VERSION "HNNBNNNYNNNNNNNNNNNNNNNNNNNNNNNNNNNNNNNNNN/4/%%%/4/'%**4NNN///"

NS_ :

BS_:

BU_: BAP_Tester BCM Gateway_Max TSGGen3_BFS TSGGen3_FS TSGGen3_HBFS TSGGen3_HFS WLC_01_CFD

BO_ 1524 Innenlicht_11: 8 BCM
 SG_ IL_Dimmung_V_Tuerkontur : 0|8@1+ (1,0) [0|100] "Unit_PerCent"  Gateway_Max
 SG_ IL_Dimmung_H_Tuerkontur : 8|8@1+ (1,0) [0|100] "Unit_PerCent"  Gateway_Max
 SG_ IL_Dimmung_Tuerinnengriff : 16|8@1+ (1,0) [0|100] "Unit_PerCent"  Gateway_Max
 SG_ IL_Dimmung_Umfeldbel : 24|8@1+ (1,0) [0|100] "Unit_PerCent"  Gateway_Max
 SG_ IL_Bel_FS_Ausstieg : 32|1@1+ (1.0,0.0) [0.0|1] ""  Gateway_Max
 SG_ IL_Bel_BFS_Ausstieg : 33|1@1+ (1.0,0.0) [0.0|1] ""  Gateway_Max
 SG_ IL_Bel_HFS_Ausstieg : 34|1@1+ (1.0,0.0) [0.0|1] ""  Gateway_Max
 SG_ IL_Bel_HBFS_Ausstieg : 35|1@1+ (1.0,0.0) [0.0|1] ""  Gateway_Max
 SG_ BCM1_Innenlicht_gedimmt_V : 36|1@1+ (1.0,0.0) [0.0|1] ""  Gateway_Max
 SG_ BCM1_Innenlicht_gedimmt_H : 37|1@1+ (1.0,0.0) [0.0|1] ""  Gateway_Max
 SG_ IL_Innenlicht_aktiv : 38|1@1+ (1.0,0.0) [0.0|1] ""  Gateway_Max
 SG_ IL_Klemme_30G_aktiv : 39|1@1+ (1.0,0.0) [0.0|1] ""  Gateway_Max,TSGGen3_BFS,TSGGen3_FS,TSGGen3_HBFS,TSGGen3_HFS
 SG_ BCM1_DI_Rampe_Innenlicht : 40|1@1+ (1.0,0.0) [0.0|1] ""  Gateway_Max
 SG_ BCM1_DI_Rampe_Leselicht : 41|1@1+ (1.0,0.0) [0.0|1] ""  Gateway_Max
 SG_ BCM1_Innenlicht_H : 42|1@1+ (1.0,0.0) [0.0|1] ""  Gateway_Max
 SG_ BCM1_Innenlicht_V : 43|1@1+ (1.0,0.0) [0.0|1] ""  Gateway_Max
 SG_ BCM1_Leselicht_Anf_hl : 44|1@1+ (1.0,0.0) [0.0|1] ""  Gateway_Max
 SG_ BCM1_Leselicht_Anf_hr : 45|1@1+ (1.0,0.0) [0.0|1] ""  Gateway_Max
 SG_ BCM1_Leselicht_Anf_vl : 46|1@1+ (1.0,0.0) [0.0|1] ""  Gateway_Max
 SG_ BCM1_Leselicht_Anf_vr : 47|1@1+ (1.0,0.0) [0.0|1] ""  Gateway_Max
 SG_ BCM1_Leuchten_Aus : 48|1@1+ (1.0,0.0) [0.0|1] ""  Gateway_Max
 SG_ AMB_Charisma_FahrPr : 49|4@1+ (1.0,0.0) [0.0|15] ""  Gateway_Max
 SG_ AMB_Charisma_Status : 53|2@1+ (1.0,0.0) [0.0|3] ""  Gateway_Max
 SG_ IL_Dimmung_Lautspr : 56|8@1+ (1,0) [0|100] "Unit_PerCent"  Gateway_Max

BO_ 2527679583 IPA_02: 8 Gateway_Max
 SG_ IPA_02_CRC : 0|8@1+ (1,0) [0|255] ""  BCM
 SG_ IPA_02_BZ : 8|4@1+ (1,0) [0|15] ""  BCM
 SG_ IPA_PL_Anzeige_links : 12|2@1+ (1.0,0.0) [0.0|3] ""  BCM
 SG_ IPA_PL_Anzeige_rechts : 14|2@1+ (1.0,0.0) [0.0|3] ""  BCM
 SG_ Parken_Seitenspiegel_Anf : 20|2@1+ (1.0,0.0) [0.0|3] ""  BCM
 SG_ Parken_ZV_Schliessen : 22|2@1+ (1.0,0.0) [0.0|3] ""  BCM
 SG_ Parken_aktives_System_02 : 24|5@1+ (1.0,0.0) [0.0|31] ""  BCM
 SG_ Parken_ZR_Sondermodus_Anf : 29|2@1+ (1.0,0.0) [0.0|3] ""  BCM
 SG_ Parken_Schluesselsuche_Anf : 31|1@1+ (1.0,0.0) [0.0|1] ""  BCM
 SG_ Parken_FFB_LED_Anf : 32|2@1+ (1.0,0.0) [0.0|3] ""  BCM
 SG_ Parken_Wegfahrsperren_Anf : 34|2@1+ (1.0,0.0) [0.0|3] ""  BCM
 SG_ Parken_Aktivierungslicht_Anf : 36|1@1+ (1.0,0.0) [0.0|1] ""  BCM
 SG_ Parken_Fahrtrichtungslicht_Anf : 37|2@1+ (1.0,0.0) [0.0|3] ""  BCM
 SG_ Parken_Lichtnachlauf_Anf : 39|1@1+ (1.0,0.0) [0.0|1] ""  BCM
 SG_ IPA_Akustik_PL_gefunden : 45|1@1+ (1.0,0.0) [0.0|1] ""  BCM
 SG_ Parken_Blinker_li_Anf : 46|1@1+ (1.0,0.0) [0.0|1] ""  BCM
 SG_ Parken_Blinker_re_Anf : 47|1@1+ (1.0,0.0) [0.0|1] ""  BCM
 SG_ Parken_Fahrerhinweise_Anf : 51|1@1+ (1.0,0.0) [0.0|1] ""  BCM
 SG_ Parken_Bestaetigungsblinken_Anf : 52|2@1+ (1.0,0.0) [0.0|3] ""  BCM
 SG_ Parken_Fahrbereitschaftlicht_Anf : 54|1@1+ (1.0,0.0) [0.0|1] ""  BCM
 SG_ Parken_Lichtsteuerung_Anf : 55|1@1+ (1.0,0.0) [0.0|1] ""  BCM
 SG_ IPA_Anf_Meldungen : 56|8@1+ (1.0,0.0) [0.0|255] ""  BCM

BO_ 1806 ISO_BCM1_Req: 8 Gateway_Max
 SG_ ISO_BCM1_Req_Data : 0|64@1+ (1.0,0.0) [0.0|18446744073709551615] ""  BCM

BO_ 1912 ISO_BCM1_Resp: 8 BCM
 SG_ ISO_BCM1_Resp_Data : 0|64@1+ (1.0,0.0) [0.0|18446744073709551615] ""  Gateway_Max

BO_ 1792 ISO_Funktionaler_Req_All: 8 Gateway_Max
 SG_ ISO_ALL_01_Req_Data : 0|64@1+ (1.0,0.0) [0.0|18446744073709551615] ""  BCM,TSGGen3_BFS,TSGGen3_FS,TSGGen3_HBFS,TSGGen3_HFS,WLC_01_CFD

BO_ 1842 ISO_Kessy_Req: 8 Gateway_Max
 SG_ ISO_Kessy_Req_Data : 0|64@1+ (1.0,0.0) [0.0|18446744073709551615] ""  BCM

BO_ 1948 ISO_Kessy_Resp: 8 BCM
 SG_ ISO_Kessy_Resp_Data : 0|64@1+ (1.0,0.0) [0.0|18446744073709551615] ""  Gateway_Max

BO_ 1867 ISO_TSG_BT_Req: 8 Gateway_Max
 SG_ ISO_TSG_BT_Req_Data : 0|64@1+ (1.0,0.0) [0.0|18446744073709551615] ""  TSGGen3_BFS

BO_ 1973 ISO_TSG_BT_Resp: 8 TSGGen3_BFS
 SG_ ISO_TSG_BT_Resp_Data : 0|64@1+ (1.0,0.0) [0.0|18446744073709551615] ""  Gateway_Max

BO_ 1866 ISO_TSG_FT_Req: 8 Gateway_Max
 SG_ ISO_TSG_FT_Req_Data : 0|64@1+ (1.0,0.0) [0.0|18446744073709551615] ""  TSGGen3_FS

BO_ 1972 ISO_TSG_FT_Resp: 8 TSGGen3_FS
 SG_ ISO_TSG_FT_Resp_Data : 0|64@1+ (1.0,0.0) [0.0|18446744073709551615] ""  Gateway_Max

BO_ 1855 ISO_TSG_HBFS_Req: 8 Gateway_Max
 SG_ ISO_TSG_HBFS_Req_Data : 0|64@1+ (1.0,0.0) [0.0|18446744073709551615] ""  TSGGen3_HBFS

BO_ 1961 ISO_TSG_HBFS_Resp: 8 TSGGen3_HBFS
 SG_ ISO_TSG_HBFS_Resp_Data : 0|64@1+ (1.0,0.0) [0.0|18446744073709551615] ""  Gateway_Max

BO_ 1854 ISO_TSG_HFS_Req: 8 Gateway_Max
 SG_ ISO_TSG_HFS_Req_Data : 0|64@1+ (1.0,0.0) [0.0|18446744073709551615] ""  TSGGen3_HFS

BO_ 1960 ISO_TSG_HFS_Resp: 8 TSGGen3_HFS
 SG_ ISO_TSG_HFS_Resp_Data : 0|64@1+ (1.0,0.0) [0.0|18446744073709551615] ""  Gateway_Max

BO_ 2621440014 ISOx_BCM1_Req_FD: 64 Gateway_Max
 SG_ ISOx_BCM1_Req_FD_Data : 0|512@1+ (1.0,0.0) [0.0|13407807929942597099574024998205846127479365820592393377723561443721764030073546976801874298166903427690031858186486050853753882811946569946433649006084095] ""  BCM

BO_ 2621571086 ISOx_BCM1_Resp_FD: 64 BCM
 SG_ ISOx_BCM1_Resp_FD_Data : 0|512@1+ (1.0,0.0) [0.0|13407807929942597099574024998205846127479365820592393377723561443721764030073546976801874298166903427690031858186486050853753882811946569946433649006084095] ""  Gateway_Max

BO_ 2549874874 ISOx_DDA_Req: 8 Gateway_Max
 SG_ ISOx_DDA_Req_Data : 0|64@1+ (1.0,0.0) [0.0|18446744073709551615] ""  BCM

BO_ 2550005946 ISOx_DDA_Resp: 8 BCM
 SG_ ISOx_DDA_Resp_Data : 0|64@1+ (1.0,0.0) [0.0|18446744073709551615] ""  Gateway_Max

BO_ 2621505536 ISOx_Funkt_Req_All_FD: 64 Gateway_Max
 SG_ ISOx_Funkt_Req_All_FD_Data : 0|512@1+ (1.0,0.0) [0.0|13407807929942597099574024998205846127479365820592393377723561443721764030073546976801874298166903427690031858186486050853753882811946569946433649006084095] ""  BCM,TSGGen3_BFS,TSGGen3_FS,TSGGen3_HBFS,TSGGen3_HFS,WLC_01_CFD

BO_ 2549874838 ISOx_LED_LM_L_Req: 8 Gateway_Max
 SG_ ISOx_LED_LM_L_Req_Data : 0|64@1+ (1.0,0.0) [0.0|18446744073709551615] ""  BCM

BO_ 2550005910 ISOx_LED_LM_L_Resp: 8 BCM
 SG_ ISOx_LED_LM_L_Resp_Data : 0|64@1+ (1.0,0.0) [0.0|18446744073709551615] ""  Gateway_Max

BO_ 2549874839 ISOx_LED_LM_R_Req: 8 Gateway_Max
 SG_ ISOx_LED_LM_R_Req_Data : 0|64@1+ (1.0,0.0) [0.0|18446744073709551615] ""  BCM

BO_ 2550005911 ISOx_LED_LM_R_Resp: 8 BCM
 SG_ ISOx_LED_LM_R_Resp_Data : 0|64@1+ (1.0,0.0) [0.0|18446744073709551615] ""  Gateway_Max

BO_ 2550398979 ISOx_RSAD_HL_Req: 8 Gateway_Max
 SG_ ISOx_RSAD_HL_Req_Data : 0|64@1+ (1.0,0.0) [0.0|18446744073709551615] ""  BCM

BO_ 2621702147 ISOx_RSAD_HL_Req_FD: 64 Gateway_Max
 SG_ ISOx_RSAD_HL_Req_FD_Data : 0|512@1+ (1.0,0.0) [0.0|13407807929942597099574024998205846127479365820592393377723561443721764030073546976801874298166903427690031858186486050853753882811946569946433649006084095] ""  BCM

BO_ 2550530051 ISOx_RSAD_HL_Resp: 8 BCM
 SG_ ISOx_RSAD_HL_Resp_Data : 0|64@1+ (1.0,0.0) [0.0|18446744073709551615] ""  Gateway_Max

BO_ 2621833219 ISOx_RSAD_HL_Resp_FD: 64 BCM
 SG_ ISOx_RSAD_HL_Resp_FD_Data : 0|512@1+ (1.0,0.0) [0.0|13407807929942597099574024998205846127479365820592393377723561443721764030073546976801874298166903427690031858186486050853753882811946569946433649006084095] ""  Gateway_Max

BO_ 2550398980 ISOx_RSAD_HR_Req: 8 Gateway_Max
 SG_ ISOx_RSAD_HR_Req_Data : 0|64@1+ (1.0,0.0) [0.0|18446744073709551615] ""  BCM

BO_ 2621702148 ISOx_RSAD_HR_Req_FD: 64 Gateway_Max
 SG_ ISOx_RSAD_HR_Req_FD_Data : 0|512@1+ (1.0,0.0) [0.0|13407807929942597099574024998205846127479365820592393377723561443721764030073546976801874298166903427690031858186486050853753882811946569946433649006084095] ""  BCM

BO_ 2550530052 ISOx_RSAD_HR_Resp: 8 BCM
 SG_ ISOx_RSAD_HR_Resp_Data : 0|64@1+ (1.0,0.0) [0.0|18446744073709551615] ""  Gateway_Max

BO_ 2621833220 ISOx_RSAD_HR_Resp_FD: 64 BCM
 SG_ ISOx_RSAD_HR_Resp_FD_Data : 0|512@1+ (1.0,0.0) [0.0|13407807929942597099574024998205846127479365820592393377723561443721764030073546976801874298166903427690031858186486050853753882811946569946433649006084095] ""  Gateway_Max

BO_ 2550399029 ISOx_RSAD_IN2_Req: 8 Gateway_Max
 SG_ ISOx_RSAD_IN2_Req_Data : 0|64@1+ (1.0,0.0) [0.0|18446744073709551615] ""  BCM

BO_ 2621702197 ISOx_RSAD_IN2_Req_FD: 64 Gateway_Max
 SG_ ISOx_RSAD_IN2_Req_FD_Data : 0|512@1+ (1.0,0.0) [0.0|13407807929942597099574024998205846127479365820592393377723561443721764030073546976801874298166903427690031858186486050853753882811946569946433649006084095] ""  BCM

BO_ 2550530101 ISOx_RSAD_IN2_Resp: 8 BCM
 SG_ ISOx_RSAD_IN2_Resp_Data : 0|64@1+ (1.0,0.0) [0.0|18446744073709551615] ""  Gateway_Max

BO_ 2621833269 ISOx_RSAD_IN2_Resp_FD: 64 BCM
 SG_ ISOx_RSAD_IN2_Resp_FD_Data : 0|512@1+ (1.0,0.0) [0.0|13407807929942597099574024998205846127479365820592393377723561443721764030073546976801874298166903427690031858186486050853753882811946569946433649006084095] ""  Gateway_Max

BO_ 2550399030 ISOx_RSAD_IN3_Req: 8 Gateway_Max
 SG_ ISOx_RSAD_IN3_Req_Data : 0|64@1+ (1.0,0.0) [0.0|18446744073709551615] ""  BCM

BO_ 2621702198 ISOx_RSAD_IN3_Req_FD: 64 Gateway_Max
 SG_ ISOx_RSAD_IN3_Req_FD_Data : 0|512@1+ (1.0,0.0) [0.0|13407807929942597099574024998205846127479365820592393377723561443721764030073546976801874298166903427690031858186486050853753882811946569946433649006084095] ""  BCM

BO_ 2550530102 ISOx_RSAD_IN3_Resp: 8 BCM
 SG_ ISOx_RSAD_IN3_Resp_Data : 0|64@1+ (1.0,0.0) [0.0|18446744073709551615] ""  Gateway_Max

BO_ 2621833270 ISOx_RSAD_IN3_Resp_FD: 64 BCM
 SG_ ISOx_RSAD_IN3_Resp_FD_Data : 0|512@1+ (1.0,0.0) [0.0|13407807929942597099574024998205846127479365820592393377723561443721764030073546976801874298166903427690031858186486050853753882811946569946433649006084095] ""  Gateway_Max

BO_ 2550399031 ISOx_RSAD_IN4_Req: 8 Gateway_Max
 SG_ ISOx_RSAD_IN4_Req_Data : 0|64@1+ (1.0,0.0) [0.0|18446744073709551615] ""  BCM

BO_ 2621702199 ISOx_RSAD_IN4_Req_FD: 64 Gateway_Max
 SG_ ISOx_RSAD_IN4_Req_FD_Data : 0|512@1+ (1.0,0.0) [0.0|13407807929942597099574024998205846127479365820592393377723561443721764030073546976801874298166903427690031858186486050853753882811946569946433649006084095] ""  BCM

BO_ 2550530103 ISOx_RSAD_IN4_Resp: 8 BCM
 SG_ ISOx_RSAD_IN4_Resp_Data : 0|64@1+ (1.0,0.0) [0.0|18446744073709551615] ""  Gateway_Max

BO_ 2621833271 ISOx_RSAD_IN4_Resp_FD: 64 BCM
 SG_ ISOx_RSAD_IN4_Resp_FD_Data : 0|512@1+ (1.0,0.0) [0.0|13407807929942597099574024998205846127479365820592393377723561443721764030073546976801874298166903427690031858186486050853753882811946569946433649006084095] ""  Gateway_Max

BO_ 2550398981 ISOx_RSAD_IN_Req: 8 Gateway_Max
 SG_ ISOx_RSAD_IN_Req_Data : 0|64@1+ (1.0,0.0) [0.0|18446744073709551615] ""  BCM

BO_ 2621702149 ISOx_RSAD_IN_Req_FD: 64 Gateway_Max
 SG_ ISOx_RSAD_IN_Req_FD_Data : 0|512@1+ (1.0,0.0) [0.0|13407807929942597099574024998205846127479365820592393377723561443721764030073546976801874298166903427690031858186486050853753882811946569946433649006084095] ""  BCM

BO_ 2550530053 ISOx_RSAD_IN_Resp: 8 BCM
 SG_ ISOx_RSAD_IN_Resp_Data : 0|64@1+ (1.0,0.0) [0.0|18446744073709551615] ""  Gateway_Max

BO_ 2621833221 ISOx_RSAD_IN_Resp_FD: 64 BCM
 SG_ ISOx_RSAD_IN_Resp_FD_Data : 0|512@1+ (1.0,0.0) [0.0|13407807929942597099574024998205846127479365820592393377723561443721764030073546976801874298166903427690031858186486050853753882811946569946433649006084095] ""  Gateway_Max

BO_ 2550398977 ISOx_RSAD_VL_Req: 8 Gateway_Max
 SG_ ISOx_RSAD_VL_Req_Data : 0|64@1+ (1.0,0.0) [0.0|18446744073709551615] ""  BCM

BO_ 2621702145 ISOx_RSAD_VL_Req_FD: 64 Gateway_Max
 SG_ ISOx_RSAD_VL_Req_FD_Data : 0|512@1+ (1.0,0.0) [0.0|13407807929942597099574024998205846127479365820592393377723561443721764030073546976801874298166903427690031858186486050853753882811946569946433649006084095] ""  BCM

BO_ 2550530049 ISOx_RSAD_VL_Resp: 8 BCM
 SG_ ISOx_RSAD_VL_Resp_Data : 0|64@1+ (1.0,0.0) [0.0|18446744073709551615] ""  Gateway_Max

BO_ 2621833217 ISOx_RSAD_VL_Resp_FD: 64 BCM
 SG_ ISOx_RSAD_VL_Resp_FD_Data : 0|512@1+ (1.0,0.0) [0.0|13407807929942597099574024998205846127479365820592393377723561443721764030073546976801874298166903427690031858186486050853753882811946569946433649006084095] ""  Gateway_Max

BO_ 2550398978 ISOx_RSAD_VR_Req: 8 Gateway_Max
 SG_ ISOx_RSAD_VR_Req_Data : 0|64@1+ (1.0,0.0) [0.0|18446744073709551615] ""  BCM

BO_ 2621702146 ISOx_RSAD_VR_Req_FD: 64 Gateway_Max
 SG_ ISOx_RSAD_VR_Req_FD_Data : 0|512@1+ (1.0,0.0) [0.0|13407807929942597099574024998205846127479365820592393377723561443721764030073546976801874298166903427690031858186486050853753882811946569946433649006084095] ""  BCM

BO_ 2550530050 ISOx_RSAD_VR_Resp: 8 BCM
 SG_ ISOx_RSAD_VR_Resp_Data : 0|64@1+ (1.0,0.0) [0.0|18446744073709551615] ""  Gateway_Max

BO_ 2621833218 ISOx_RSAD_VR_Resp_FD: 64 BCM
 SG_ ISOx_RSAD_VR_Resp_FD_Data : 0|512@1+ (1.0,0.0) [0.0|13407807929942597099574024998205846127479365820592393377723561443721764030073546976801874298166903427690031858186486050853753882811946569946433649006084095] ""  Gateway_Max

BO_ 2621440075 ISOx_TSG_BT_Req_FD: 64 Gateway_Max
 SG_ ISOx_TSG_BT_Req_FD_Data : 0|512@1+ (1.0,0.0) [0.0|13407807929942597099574024998205846127479365820592393377723561443721764030073546976801874298166903427690031858186486050853753882811946569946433649006084095] ""  TSGGen3_BFS

BO_ 2621571147 ISOx_TSG_BT_Resp_FD: 64 TSGGen3_BFS
 SG_ ISOx_TSG_BT_Resp_FD_Data : 0|512@1+ (1.0,0.0) [0.0|13407807929942597099574024998205846127479365820592393377723561443721764030073546976801874298166903427690031858186486050853753882811946569946433649006084095] ""  Gateway_Max

BO_ 2621440074 ISOx_TSG_FT_Req_FD: 64 Gateway_Max
 SG_ ISOx_TSG_FT_Req_FD_Data : 0|512@1+ (1.0,0.0) [0.0|13407807929942597099574024998205846127479365820592393377723561443721764030073546976801874298166903427690031858186486050853753882811946569946433649006084095] ""  TSGGen3_FS

BO_ 2621571146 ISOx_TSG_FT_Resp_FD: 64 TSGGen3_FS
 SG_ ISOx_TSG_FT_Resp_FD_Data : 0|512@1+ (1.0,0.0) [0.0|13407807929942597099574024998205846127479365820592393377723561443721764030073546976801874298166903427690031858186486050853753882811946569946433649006084095] ""  Gateway_Max

BO_ 2621440063 ISOx_TSG_HBFS_Req_FD: 64 Gateway_Max
 SG_ ISOx_TSG_HBFS_Req_FD_Data : 0|512@1+ (1.0,0.0) [0.0|13407807929942597099574024998205846127479365820592393377723561443721764030073546976801874298166903427690031858186486050853753882811946569946433649006084095] ""  TSGGen3_HBFS

BO_ 2621571135 ISOx_TSG_HBFS_Resp_FD: 64 TSGGen3_HBFS
 SG_ ISOx_TSG_HBFS_Resp_FD_Data : 0|512@1+ (1.0,0.0) [0.0|13407807929942597099574024998205846127479365820592393377723561443721764030073546976801874298166903427690031858186486050853753882811946569946433649006084095] ""  Gateway_Max

BO_ 2621440062 ISOx_TSG_HFS_Req_FD: 64 Gateway_Max
 SG_ ISOx_TSG_HFS_Req_FD_Data : 0|512@1+ (1.0,0.0) [0.0|13407807929942597099574024998205846127479365820592393377723561443721764030073546976801874298166903427690031858186486050853753882811946569946433649006084095] ""  TSGGen3_HFS

BO_ 2621571134 ISOx_TSG_HFS_Resp_FD: 64 TSGGen3_HFS
 SG_ ISOx_TSG_HFS_Resp_FD_Data : 0|512@1+ (1.0,0.0) [0.0|13407807929942597099574024998205846127479365820592393377723561443721764030073546976801874298166903427690031858186486050853753882811946569946433649006084095] ""  Gateway_Max

BO_ 2549874853 ISOx_WLC1_Req: 8 Gateway_Max
 SG_ ISOx_WLC1_Req_Data : 0|64@1+ (1.0,0.0) [0.0|18446744073709551615] ""  WLC_01_CFD

BO_ 2621440165 ISOx_WLC1_Req_FD: 64 Gateway_Max
 SG_ ISOx_WLC1_Req_FD_Data : 0|512@1+ (1.0,0.0) [0.0|13407807929942597099574024998205846127479365820592393377723561443721764030073546976801874298166903427690031858186486050853753882811946569946433649006084095] ""  WLC_01_CFD

BO_ 2550005925 ISOx_WLC1_Resp: 8 WLC_01_CFD
 SG_ ISOx_WLC1_Resp_Data : 0|64@1+ (1.0,0.0) [0.0|18446744073709551615] ""  Gateway_Max

BO_ 2621571237 ISOx_WLC1_Resp_FD: 64 WLC_01_CFD
 SG_ ISOx_WLC1_Resp_FD_Data : 0|512@1+ (1.0,0.0) [0.0|13407807929942597099574024998205846127479365820592393377723561443721764030073546976801874298166903427690031858186486050853753882811946569946433649006084095] ""  Gateway_Max

BO_ 1425 Kessy_03: 8 BCM
 SG_ KY_Gesamt_Entr : 8|1@1+ (1.0,0.0) [0.0|1] ""  Gateway_Max
 SG_ KY_FS_Entr : 9|1@1+ (1.0,0.0) [0.0|1] ""  Gateway_Max
 SG_ KY_BFS_Entr : 10|1@1+ (1.0,0.0) [0.0|1] ""  Gateway_Max
 SG_ KY_HFS_Entr : 11|1@1+ (1.0,0.0) [0.0|1] ""  Gateway_Max
 SG_ KY_HBFS_Entr : 12|1@1+ (1.0,0.0) [0.0|1] ""  Gateway_Max
 SG_ KY_HD_Entr : 13|1@1+ (1.0,0.0) [0.0|1] ""  Gateway_Max
 SG_ KY_HS_Entr : 14|1@1+ (1.0,0.0) [0.0|1] ""  Gateway_Max
 SG_ KY_Schliessverh_HD : 15|1@1+ (1.0,0.0) [0.0|1] ""  Gateway_Max
 SG_ KY_Zufallszahl : 16|32@1+ (1.0,0.0) [0.0|4294967295] ""  Gateway_Max
 SG_ KY_Burst_1 : 48|2@1+ (1,0) [0|3] ""  Gateway_Max
 SG_ KY_Burst_2 : 50|2@1+ (1,0) [0|3] ""  Gateway_Max
 SG_ KY_Burst_3 : 52|2@1+ (1,0) [0|3] ""  Gateway_Max
 SG_ KY_Bdraten_Rueckspr : 56|1@1+ (1.0,0.0) [0.0|1] ""  Gateway_Max
 SG_ KY_Entry_ETuer_HFS : 57|1@1+ (1.0,0.0) [0.0|1] ""  Gateway_Max
 SG_ KY_Entry_ETuer_HBFS : 58|1@1+ (1.0,0.0) [0.0|1] ""  Gateway_Max
 SG_ KY_VirtuellesPedal_HK : 59|1@1+ (1.0,0.0) [0.0|1] ""  Gateway_Max
 SG_ KY_3_Bremslicht_Ein : 60|1@1+ (1.0,0.0) [0.0|1] ""  Gateway_Max

BO_ 1426 Kessy_04: 8 BCM
 SG_ KY_ID_Geber1_im_Fzg : 12|1@1+ (1.0,0.0) [0.0|1] ""  Gateway_Max
 SG_ KY_ID_Geber2_im_Fzg : 13|1@1+ (1.0,0.0) [0.0|1] ""  Gateway_Max
 SG_ KY_ID_Geber3_im_Fzg : 14|1@1+ (1.0,0.0) [0.0|1] ""  Gateway_Max
 SG_ KY_ID_Geber4_im_Fzg : 15|1@1+ (1.0,0.0) [0.0|1] ""  Gateway_Max
 SG_ KY_Startknopf_Bel : 16|1@1+ (1.0,0.0) [0.0|1] ""  Gateway_Max
 SG_ KY_ID_Geber_Suche : 17|1@1+ (1.0,0.0) [0.0|1] ""  Gateway_Max
 SG_ KY_Meldungen : 18|4@1+ (1.0,0.0) [0.0|15] ""  Gateway_Max
 SG_ KY_Gong_600 : 22|1@1+ (1.0,0.0) [0.0|1] ""  Gateway_Max
 SG_ KY_Passiv_Autolock_Menue : 23|1@1+ (1.0,0.0) [0.0|1] ""  Gateway_Max
 SG_ KY_Passiv_Autolock_Akt : 24|1@1+ (1.0,0.0) [0.0|1] ""  Gateway_Max
 SG_ KY_Passiv_Autolock : 25|1@1+ (1.0,0.0) [0.0|1] ""  Gateway_Max
 SG_ KY_Passiv_Autounlock : 26|1@1+ (1.0,0.0) [0.0|1] ""  Gateway_Max
 SG_ KY_Gestik_HD : 27|1@1+ (1.0,0.0) [0.0|1] ""  Gateway_Max
 SG_ KY_StartStopp_Info : 28|2@1+ (1.0,0.0) [0.0|3] ""  Gateway_Max
 SG_ KY_Fzg_Verlassen_erkannt : 30|1@1+ (1.0,0.0) [0.0|1] ""  Gateway_Max
 SG_ KY_Fzg_Zugang_erkannt : 31|1@1+ (1.0,0.0) [0.0|1] ""  Gateway_Max
 SG_ KY_EasyClose_Abbruch : 32|1@1+ (1.0,0.0) [0.0|1] ""  Gateway_Max
 SG_ KY_EasyClose_Status : 33|3@1+ (1.0,0.0) [0.0|7] ""  Gateway_Max
 SG_ KY_HD_Auffahrt : 36|1@1+ (1.0,0.0) [0.0|1] ""  Gateway_Max
 SG_ KY_HD_Zufahrt : 37|1@1+ (1.0,0.0) [0.0|1] ""  Gateway_Max
 SG_ KY_Aktive_LFScans : 38|4@1+ (1.0,0.0) [0.0|15] ""  Gateway_Max
 SG_ KY_LF_Aktiv : 42|1@1+ (1.0,0.0) [0.0|1] ""  Gateway_Max
 SG_ KY_AnzKoord_Info : 43|2@1+ (1.0,0.0) [0.0|3] ""  Gateway_Max
 SG_ KY_Schluesselposition_9 : 45|2@1+ (1.0,0.0) [0.0|3] ""  Gateway_Max
 SG_ KY_Schluesselposition_1 : 48|2@1+ (1.0,0.0) [0.0|3] ""  Gateway_Max
 SG_ KY_Schluesselposition_2 : 50|2@1+ (1.0,0.0) [0.0|3] ""  Gateway_Max
 SG_ KY_Schluesselposition_3 : 52|2@1+ (1.0,0.0) [0.0|3] ""  Gateway_Max
 SG_ KY_Schluesselposition_4 : 54|2@1+ (1.0,0.0) [0.0|3] ""  Gateway_Max
 SG_ KY_Schluesselposition_5 : 56|2@1+ (1.0,0.0) [0.0|3] ""  Gateway_Max
 SG_ KY_Schluesselposition_6 : 58|2@1+ (1.0,0.0) [0.0|3] ""  Gateway_Max
 SG_ KY_Schluesselposition_7 : 60|2@1+ (1.0,0.0) [0.0|3] ""  Gateway_Max
 SG_ KY_Schluesselposition_8 : 62|2@1+ (1.0,0.0) [0.0|3] ""  Gateway_Max

BO_ 960 Klemmen_Status_01: 4 BCM
 SG_ Klemmen_Status_01_CRC : 0|8@1+ (1,0) [0|255] ""  Gateway_Max
 SG_ Klemmen_Status_01_BZ : 8|4@1+ (1,0) [0|15] ""  Gateway_Max
 SG_ RSt_Fahrerhinweise : 12|4@1+ (1.0,0.0) [0.0|15] ""  Gateway_Max
 SG_ ZAS_Kl_S : 16|1@1+ (1.0,0.0) [0.0|1] ""  Gateway_Max,TSGGen3_BFS,TSGGen3_FS,TSGGen3_HBFS,TSGGen3_HFS,WLC_01_CFD
 SG_ ZAS_Kl_15 : 17|1@1+ (1.0,0.0) [0.0|1] ""  Gateway_Max,TSGGen3_BFS,TSGGen3_FS,TSGGen3_HBFS,TSGGen3_HFS,WLC_01_CFD
 SG_ ZAS_Kl_X : 18|1@1+ (1.0,0.0) [0.0|1] ""  Gateway_Max,TSGGen3_BFS,TSGGen3_FS,TSGGen3_HBFS,TSGGen3_HFS
 SG_ ZAS_Kl_50_Startanforderung : 19|1@1+ (1.0,0.0) [0.0|1] ""  Gateway_Max,TSGGen3_BFS,TSGGen3_FS,TSGGen3_HBFS,TSGGen3_HFS
 SG_ BCM_Remotestart_Betrieb : 20|1@1+ (1.0,0.0) [0.0|1] ""  Gateway_Max,TSGGen3_BFS,TSGGen3_FS
 SG_ ZAS_Kl_Infotainment : 21|1@1+ (1.0,0.0) [0.0|1] ""  Gateway_Max
 SG_ BCM_Remotestart_KL15_Anf : 22|1@1+ (1.0,0.0) [0.0|1] ""  Gateway_Max
 SG_ BCM_Remotestart_MO_Start : 23|1@1+ (1.0,0.0) [0.0|1] ""  Gateway_Max
 SG_ KST_Warn_P1_ZST_def : 24|1@1+ (1.0,0.0) [0.0|1] ""  Gateway_Max
 SG_ KST_Warn_P2_ZST_def : 25|1@1+ (1.0,0.0) [0.0|1] ""  Gateway_Max
 SG_ KST_Fahrerhinweis_1 : 26|1@1+ (1.0,0.0) [0.0|1] ""  Gateway_Max
 SG_ KST_Fahrerhinweis_2 : 27|1@1+ (1.0,0.0) [0.0|1] ""  Gateway_Max
 SG_ BCM_Ausparken_Betrieb : 28|1@1+ (1.0,0.0) [0.0|1] ""  Gateway_Max
 SG_ KST_Fahrerhinweis_4 : 29|1@1+ (1.0,0.0) [0.0|1] ""  Gateway_Max
 SG_ KST_Fahrerhinweis_5 : 30|1@1+ (1.0,0.0) [0.0|1] ""  Gateway_Max
 SG_ KST_Fahrerhinweis_6 : 31|1@1+ (1.0,0.0) [0.0|1] ""  Gateway_Max

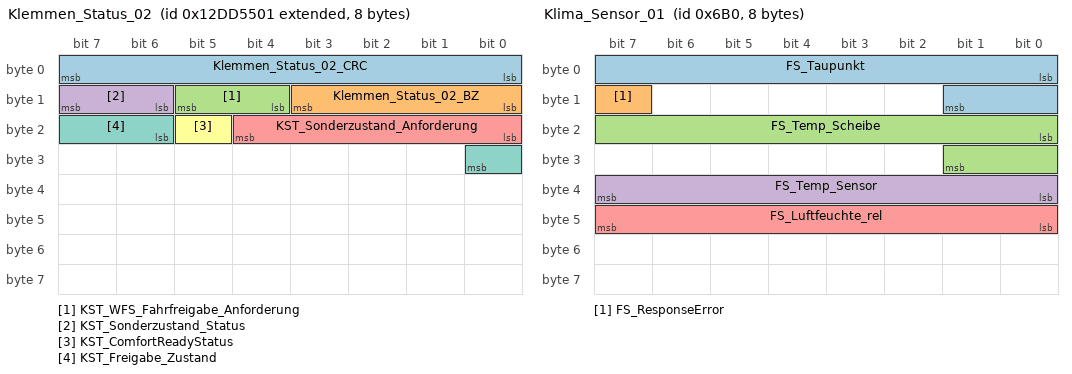
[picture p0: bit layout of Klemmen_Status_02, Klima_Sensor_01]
BO_ 2463978753 Klemmen_Status_02: 8 BCM
 SG_ Klemmen_Status_02_CRC : 0|8@1+ (1,0) [0|255] ""  Gateway_Max
 SG_ Klemmen_Status_02_BZ : 8|4@1+ (1,0) [0|15] ""  Gateway_Max
 SG_ KST_WFS_Fahrfreigabe_Anforderung : 12|2@1+ (1.0,0.0) [0.0|3] ""  Gateway_Max
 SG_ KST_Sonderzustand_Status : 14|2@1+ (1.0,0.0) [0.0|3] ""  Gateway_Max,TSGGen3_BFS,TSGGen3_FS,TSGGen3_HBFS,TSGGen3_HFS
 SG_ KST_Sonderzustand_Anforderung : 16|5@1+ (1.0,0.0) [0.0|31] ""  Gateway_Max,TSGGen3_BFS,TSGGen3_FS,TSGGen3_HBFS,TSGGen3_HFS
 SG_ KST_ComfortReadyStatus : 21|1@1+ (1.0,0.0) [0.0|1] ""  Gateway_Max
 SG_ KST_Freigabe_Zustand : 22|3@1+ (1.0,0.0) [0.0|7] ""  Gateway_Max

BO_ 1420 Klemmen_Steuerung_01: 8 BCM
 SG_ Klemmen_Steuerung_01_CRC : 0|8@1+ (1,0) [0|255] ""  Gateway_Max
 SG_ Klemmen_Steuerung_01_BZ : 8|4@1+ (1,0) [0|15] ""  Gateway_Max
 SG_ KST_Anf_Klemme_15 : 12|1@1+ (1.0,0.0) [0.0|1] ""  Gateway_Max
 SG_ KST_Anf_Klemme_50 : 13|1@1+ (1.0,0.0) [0.0|1] ""  Gateway_Max
 SG_ KST_Anf_Klemme_S : 14|1@1+ (1.0,0.0) [0.0|1] ""  Gateway_Max
 SG_ KST_Txt_Werkstatt : 15|1@1+ (1.0,0.0) [0.0|1] ""  Gateway_Max
 SG_ KST_Txt_P_Gang : 16|1@1+ (1.0,0.0) [0.0|1] ""  Gateway_Max
 SG_ KST_Txt_Panikabschaltung : 17|1@1+ (1.0,0.0) [0.0|1] ""  Gateway_Max
 SG_ KST_Anf_Klemmenfreigabe_ELV : 18|1@1+ (1.0,0.0) [0.0|1] ""  Gateway_Max
 SG_ KST_Txt_Komfortabschaltung : 19|1@1+ (1.0,0.0) [0.0|1] ""  Gateway_Max
 SG_ KST_ZAT_betaetigt : 20|1@1+ (1.0,0.0) [0.0|1] ""  Gateway_Max
 SG_ KST_Unterdr_Zuendungsmeldung : 21|1@1+ (1.0,0.0) [0.0|1] ""  Gateway_Max
 SG_ KST_aut_Abschaltung_Zuendung : 22|1@1+ (1.0,0.0) [0.0|1] ""  Gateway_Max
 SG_ KST_Anf_Klemmenfreigabe_WFS : 23|1@1+ (1.0,0.0) [0.0|1] ""  Gateway_Max
 SG_ KST_Anf_ZV_Verriegelung : 24|1@1+ (1.0,0.0) [0.0|1] ""  Gateway_Max
 SG_ Relais_VoKo_angesteuert : 25|1@1+ (1.0,0.0) [0.0|1] ""  Gateway_Max
 SG_ RSt_Anforderung_HMS : 26|3@1+ (1.0,0.0) [0.0|7] ""  Gateway_Max
 SG_ KST_Zuendungswarnung : 29|2@1+ (1.0,0.0) [0.0|3] ""  Gateway_Max
 SG_ KST_Anzeige_Klemmenzustand : 36|3@1+ (1.0,0.0) [0.0|7] ""  Gateway_Max

BO_ 1646 Klima_03: 8 Gateway_Max
 SG_ KL_STL_aktiv : 0|1@1+ (1.0,0.0) [0.0|1] ""  BCM
 SG_ KL_STH_aktiv : 1|1@1+ (1.0,0.0) [0.0|1] ""  BCM,TSGGen3_FS
 SG_ KL_Solarluefter_aktiv : 2|1@1+ (1.0,0.0) [0.0|1] ""  Vector__XXX
 SG_ KL_Umluft_Taste : 3|1@1+ (1.0,0.0) [0.0|1] ""  Vector__XXX
 SG_ KL_Geblaese_Fond_Status : 4|4@1+ (1.0,0.0) [0.0|15] ""  BCM
 SG_ KL_STH_Ansteuerung : 8|2@1+ (1.0,0.0) [0.0|3] ""  Vector__XXX
 SG_ KL_STH_Betriebsdauer : 10|6@1+ (1,0) [0|60] "Unit_Minut"  Vector__XXX
 SG_ KL_Magnetventil : 16|1@1+ (1.0,0.0) [0.0|1] ""  Vector__XXX
 SG_ KL_WaPu : 17|1@1+ (1.0,0.0) [0.0|1] ""  Vector__XXX
 SG_ KL_Geblaese_Status : 18|4@1+ (1.0,0.0) [0.0|15] ""  BCM,WLC_01_CFD
 SG_ KL_Restwaerme_aktiv : 22|1@1+ (1.0,0.0) [0.0|1] ""  BCM
 SG_ KL_Kompressorkupplung : 23|1@1+ (1.0,0.0) [0.0|1] ""  Vector__XXX
 SG_ KL_BCmE_Livetip_Freigabe : 24|1@1+ (1.0,0.0) [0.0|1] ""  Vector__XXX
 SG_ KL_SH_Soll_hl : 25|3@1+ (1.0,0.0) [0.0|7] ""  Vector__XXX
 SG_ KL_SH_Soll_hr : 28|3@1+ (1.0,0.0) [0.0|7] ""  Vector__XXX
 SG_ KL_ErwVK_Anf : 31|1@1+ (1.0,0.0) [0.0|1] ""  BCM,TSGGen3_BFS,TSGGen3_FS,TSGGen3_HBFS,TSGGen3_HFS
 SG_ KL_Innen_Temp : 32|8@1+ (0.5,-50) [-50.0|76.0] "Unit_DegreCelsi"  TSGGen3_BFS,TSGGen3_FS,TSGGen3_HBFS,TSGGen3_HFS,WLC_01_CFD
 SG_ KL_I_Geblaese_Fond : 40|8@1+ (0.25,0) [0.00|63.50] "Unit_Amper"  Vector__XXX
 SG_ KL_Anf_AussenspiegelHzg : 48|1@1+ (1.0,0.0) [0.0|1] ""  TSGGen3_BFS,TSGGen3_FS
 SG_ KL_Heizkreisventilstellung : 49|2@1+ (1.0,0.0) [0.0|3] ""  Vector__XXX
 SG_ KL_FSH_Automatikbetrieb : 51|1@1+ (1.0,0.0) [0.0|1] ""  Vector__XXX
 SG_ KL_SIH_LEH_Verteilung_VL : 52|3@1+ (1.0,0.0) [0.0|7] ""  Vector__XXX
 SG_ KL_SIH_LEL_Verteilung_VL : 55|3@1+ (1.0,0.0) [0.0|7] ""  BCM
 SG_ KL_SIH_LEH_Verteilung_VR : 58|3@1+ (1.0,0.0) [0.0|7] ""  Vector__XXX
 SG_ KL_SIH_LEL_Verteilung_VR : 61|3@1+ (1.0,0.0) [0.0|7] ""  BCM

BO_ 1640 Klima_12: 8 Gateway_Max
 SG_ KL_LRH_Taster : 0|1@1+ (1.0,0.0) [0.0|1] ""  BCM
 SG_ KL_LRH_Stufe : 1|2@1+ (1.0,0.0) [0.0|3] ""  BCM
 SG_ HSH_Taster : 3|2@1+ (1.0,0.0) [0.0|3] ""  Vector__XXX
 SG_ FSH_Taster : 5|1@1+ (1.0,0.0) [0.0|1] ""  Vector__XXX
 SG_ KL_Zuheizer_Freigabe : 6|1@1+ (1.0,0.0) [0.0|1] ""  Vector__XXX
 SG_ KL_Beschlagsgefahr : 7|1@1+ (1.0,0.0) [0.0|1] ""  Vector__XXX
 SG_ KL_SIH_Soll_li : 8|3@1+ (1,0) [0|6] ""  Vector__XXX
 SG_ KL_SIH_Soll_re : 11|3@1+ (1,0) [0|6] ""  Vector__XXX
 SG_ KRH_Soll_li : 14|2@1+ (1.0,0.0) [0.0|3] ""  BCM
 SG_ KL_SIL_Soll_li : 16|3@1+ (1,0) [0|6] ""  Vector__XXX
 SG_ KL_SIL_Soll_re : 19|3@1+ (1,0) [0|6] ""  Vector__XXX
 SG_ KRH_Soll_re : 22|2@1+ (1.0,0.0) [0.0|3] ""  BCM
 SG_ KL_Geblspng_Soll : 24|8@1+ (0.05,1.45) [1.50|14.00] "Unit_Volt"  BCM
 SG_ KL_Geblspng_Fond_Soll : 32|8@1+ (0.05,1.45) [1.50|14.00] "Unit_Volt"  BCM
 SG_ KL_I_Geblaese : 40|8@1+ (0.25,0) [0.00|63.50] "Unit_Amper"  Vector__XXX
 SG_ KL_Kompressorstrom_soll : 48|10@1+ (1,0) [0|1021] ""  Vector__XXX
 SG_ KL_Umluftklappe_Status : 58|4@1+ (1.0,0.0) [0.0|15] ""  Vector__XXX
 SG_ KL_PTC_Verbauinfo : 62|2@1+ (1.0,0.0) [0.0|3] ""  Vector__XXX

BO_ 2527679635 Klima_16: 8 Gateway_Max
 SG_ KL_Voko_Status : 0|4@1+ (1.0,0.0) [0.0|15] ""  Vector__XXX
 SG_ KL_LRH_PWM : 4|7@1+ (1,0) [0|100] "Unit_PerCent"  Vector__XXX
 SG_ KL_LRH_Soll : 11|1@1+ (1.0,0.0) [0.0|1] ""  Vector__XXX
 SG_ KL_AL_VR_Anf : 12|2@1+ (1.0,0.0) [0.0|3] ""  BCM
 SG_ KL_AL_VL_Anf : 14|2@1+ (1.0,0.0) [0.0|3] ""  BCM
 SG_ KL_AL_HR_Anf : 16|2@1+ (1.0,0.0) [0.0|3] ""  BCM
 SG_ KL_AL_HL_Anf : 18|2@1+ (1.0,0.0) [0.0|3] ""  BCM
 SG_ KL_HSH_Soll : 20|1@1+ (1.0,0.0) [0.0|1] ""  Vector__XXX
 SG_ KL_FSH_Soll : 21|1@1+ (1.0,0.0) [0.0|1] ""  Vector__XXX
 SG_ KL_ZR_Anforderung : 22|2@1+ (1.0,0.0) [0.0|3] ""  Vector__XXX
 SG_ KL_VoKo_LED : 24|1@1+ (1.0,0.0) [0.0|1] ""  BCM
 SG_ KL_Defrost_LED : 25|1@1+ (1.0,0.0) [0.0|1] ""  BCM
 SG_ KL_HSH_LED : 26|1@1+ (1.0,0.0) [0.0|1] ""  BCM
 SG_ HSH_Relais_Anf : 27|1@1+ (1.0,0.0) [0.0|1] ""  BCM
 SG_ FSH_Status : 28|2@1+ (1.0,0.0) [0.0|3] ""  Vector__XXX
 SG_ SIH_Stufe_LED_li : 30|3@1+ (1.0,0.0) [0.0|7] ""  Vector__XXX
 SG_ SIH_Stufe_LED_re : 33|3@1+ (1.0,0.0) [0.0|7] ""  Vector__XXX
 SG_ KL_FSH_LED : 36|1@1+ (1.0,0.0) [0.0|1] ""  BCM
 SG_ KL_HUP_aktiv : 37|1@1+ (1.0,0.0) [0.0|1] ""  Vector__XXX
 SG_ KL_LSH_DBetr_Ein : 38|1@1+ (1.0,0.0) [0.0|1] ""  Vector__XXX
 SG_ KL_LSH_DBetr_Bestaet : 39|1@1+ (1.0,0.0) [0.0|1] ""  Vector__XXX
 SG_ KL_Klappe_Status : 40|3@1+ (1.0,0.0) [0.0|7] ""  Vector__XXX
 SG_ KL_LSH_Ansteuerung : 43|2@1+ (1.0,0.0) [0.0|3] ""  Vector__XXX
 SG_ KL_Heizstufe_LSH : 45|4@1+ (1.0,0.0) [0.0|15] ""  Vector__XXX
 SG_ KL_LSH_Betriebsdauer : 49|7@1+ (1,0) [0|120] "Unit_Minut"  Vector__XXX
 SG_ KL_Temp_ZH_Soll : 56|8@1+ (0.5,0) [0.5|127.0] "Unit_DegreCelsi"  Vector__XXX

BO_ 1712 Klima_Sensor_01: 8 BCM
 SG_ FS_Taupunkt : 0|10@1+ (0.1,-39.6) [-39.5|60.4] "Unit_DegreCelsi"  Gateway_Max
 SG_ FS_ResponseError : 15|1@1+ (1.0,0.0) [0.0|1] ""  Gateway_Max
 SG_ FS_Temp_Scheibe : 16|10@1+ (0.1,-39.6) [-39.5|60.4] "Unit_DegreCelsi"  Gateway_Max
 SG_ FS_Temp_Sensor : 32|8@1+ (0.5,-40) [-39.5|87.0] "Unit_DegreCelsi"  Gateway_Max
 SG_ FS_Luftfeuchte_rel : 40|8@1+ (0.5,-0.5) [0.0|100.0] "Unit_PerCent"  Gateway_Max

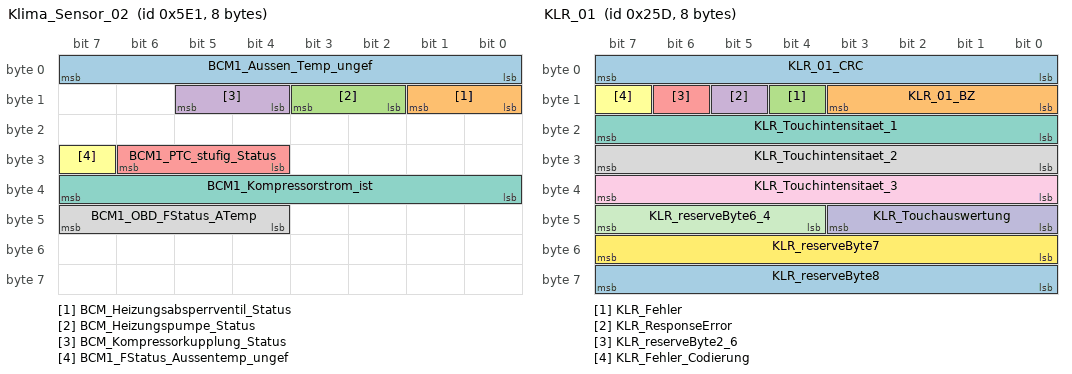
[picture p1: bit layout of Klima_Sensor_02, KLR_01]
BO_ 1505 Klima_Sensor_02: 8 BCM
 SG_ BCM1_Aussen_Temp_ungef : 0|8@1+ (0.5,-50) [-50.0|76.0] "Unit_DegreCelsi"  Gateway_Max,TSGGen3_BFS,TSGGen3_FS,TSGGen3_HBFS,TSGGen3_HFS
 SG_ BCM_Heizungsabsperrventil_Status : 8|2@1+ (1.0,0.0) [0.0|3] ""  Gateway_Max
 SG_ BCM_Heizungspumpe_Status : 10|2@1+ (1.0,0.0) [0.0|3] ""  Gateway_Max
 SG_ BCM_Kompressorkupplung_Status : 12|2@1+ (1.0,0.0) [0.0|3] ""  Gateway_Max
 SG_ BCM1_PTC_stufig_Status : 28|3@1+ (1.0,0.0) [0.0|7] ""  Gateway_Max
 SG_ BCM1_FStatus_Aussentemp_ungef : 31|1@1+ (1.0,0.0) [0.0|1] ""  Gateway_Max,TSGGen3_BFS,TSGGen3_FS,TSGGen3_HBFS,TSGGen3_HFS
 SG_ BCM1_Kompressorstrom_ist : 32|8@1+ (4,0) [0|1000] "Unit_MilliAmper"  Gateway_Max
 SG_ BCM1_OBD_FStatus_ATemp : 44|4@1+ (1.0,0.0) [0.0|15] ""  Gateway_Max

BO_ 605 KLR_01: 8 Gateway_Max
 SG_ KLR_01_CRC : 0|8@1+ (1,0) [0|255] ""  BCM
 SG_ KLR_01_BZ : 8|4@1+ (1,0) [0|15] ""  BCM
 SG_ KLR_Fehler : 12|1@1+ (1.0,0.0) [0.0|1] ""  Vector__XXX
 SG_ KLR_ResponseError : 13|1@1+ (1.0,0.0) [0.0|1] ""  Vector__XXX
 SG_ KLR_reserveByte2_6 : 14|1@1+ (1.0,0.0) [0.0|1] ""  Vector__XXX
 SG_ KLR_Fehler_Codierung : 15|1@1+ (1.0,0.0) [0.0|1] ""  Vector__XXX
 SG_ KLR_Touchintensitaet_1 : 16|8@1+ (1,0) [0|250] "Unit_None"  Vector__XXX
 SG_ KLR_Touchintensitaet_2 : 24|8@1+ (1,0) [0|250] "Unit_None"  Vector__XXX
 SG_ KLR_Touchintensitaet_3 : 32|8@1+ (1,0) [0|250] "Unit_None"  Vector__XXX
 SG_ KLR_Touchauswertung : 40|4@1+ (1.0,0.0) [0.0|15] ""  BCM
 SG_ KLR_reserveByte6_4 : 44|4@1+ (1.0,0.0) [0.0|15] ""  Vector__XXX
 SG_ KLR_reserveByte7 : 48|8@1+ (1.0,0.0) [0.0|255] ""  Vector__XXX
 SG_ KLR_reserveByte8 : 56|8@1+ (1.0,0.0) [0.0|255] ""  Vector__XXX

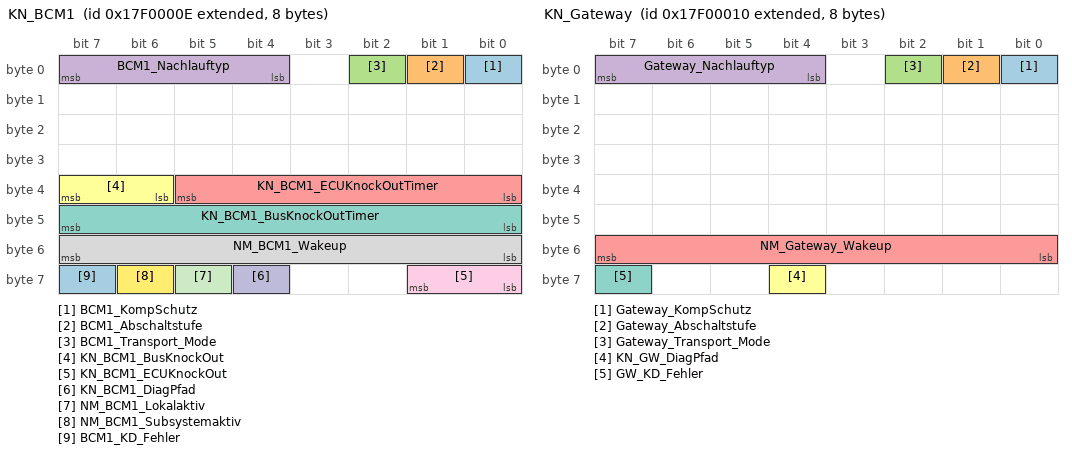
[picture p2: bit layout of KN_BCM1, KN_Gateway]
BO_ 2549088270 KN_BCM1: 8 BCM
 SG_ BCM1_KompSchutz : 0|1@1+ (1.0,0.0) [0.0|1] ""  Vector__XXX
 SG_ BCM1_Abschaltstufe : 1|1@1+ (1.0,0.0) [0.0|1] ""  Vector__XXX
 SG_ BCM1_Transport_Mode : 2|1@1+ (1.0,0.0) [0.0|1] ""  Vector__XXX
 SG_ BCM1_Nachlauftyp : 4|4@1+ (1.0,0.0) [0.0|15] ""  Gateway_Max
 SG_ KN_BCM1_ECUKnockOutTimer : 32|6@1+ (1,0) [0|62] "Unit_Minut"  Vector__XXX
 SG_ KN_BCM1_BusKnockOut : 38|2@1+ (1.0,0.0) [0.0|3] ""  Vector__XXX
 SG_ KN_BCM1_BusKnockOutTimer : 40|8@1+ (1,0) [0|254] "Unit_Minut"  Vector__XXX
 SG_ NM_BCM1_Wakeup : 48|8@1+ (1.0,0.0) [0.0|255] ""  Vector__XXX
 SG_ KN_BCM1_ECUKnockOut : 56|2@1+ (1.0,0.0) [0.0|3] ""  Vector__XXX
 SG_ KN_BCM1_DiagPfad : 60|1@1+ (1.0,0.0) [0.0|1] ""  Gateway_Max
 SG_ NM_BCM1_Lokalaktiv : 61|1@1+ (1.0,0.0) [0.0|1] ""  Vector__XXX
 SG_ NM_BCM1_Subsystemaktiv : 62|1@1+ (1.0,0.0) [0.0|1] ""  Vector__XXX
 SG_ BCM1_KD_Fehler : 63|1@1+ (1.0,0.0) [0.0|1] ""  Gateway_Max

BO_ 2549088272 KN_Gateway: 8 Gateway_Max
 SG_ Gateway_KompSchutz : 0|1@1+ (1.0,0.0) [0.0|1] ""  Vector__XXX
 SG_ Gateway_Abschaltstufe : 1|1@1+ (1.0,0.0) [0.0|1] ""  Vector__XXX
 SG_ Gateway_Transport_Mode : 2|1@1+ (1.0,0.0) [0.0|1] ""  Vector__XXX
 SG_ Gateway_Nachlauftyp : 4|4@1+ (1.0,0.0) [0.0|15] ""  Vector__XXX
 SG_ NM_Gateway_Wakeup : 48|8@1+ (1.0,0.0) [0.0|255] ""  Vector__XXX
 SG_ KN_GW_DiagPfad : 60|1@1+ (1.0,0.0) [0.0|1] ""  Vector__XXX
 SG_ GW_KD_Fehler : 63|1@1+ (1.0,0.0) [0.0|1] ""  Vector__XXX

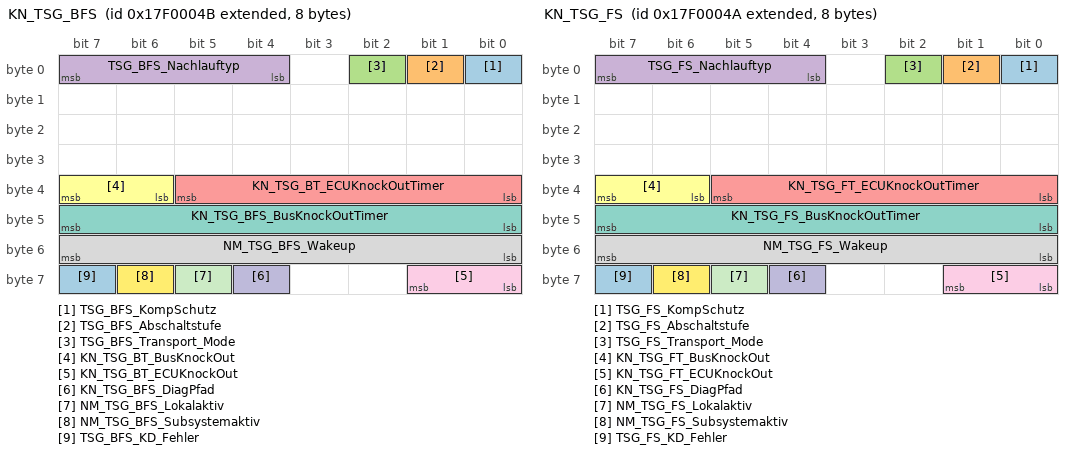
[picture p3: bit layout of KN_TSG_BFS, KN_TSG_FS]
BO_ 2549088331 KN_TSG_BFS: 8 TSGGen3_BFS
 SG_ TSG_BFS_KompSchutz : 0|1@1+ (1.0,0.0) [0.0|1] ""  Vector__XXX
 SG_ TSG_BFS_Abschaltstufe : 1|1@1+ (1.0,0.0) [0.0|1] ""  Vector__XXX
 SG_ TSG_BFS_Transport_Mode : 2|1@1+ (1.0,0.0) [0.0|1] ""  Vector__XXX
 SG_ TSG_BFS_Nachlauftyp : 4|4@1+ (1.0,0.0) [0.0|15] ""  Gateway_Max
 SG_ KN_TSG_BT_ECUKnockOutTimer : 32|6@1+ (1,0) [0|62] ""  Vector__XXX
 SG_ KN_TSG_BT_BusKnockOut : 38|2@1+ (1.0,0.0) [0.0|3] ""  Vector__XXX
 SG_ KN_TSG_BFS_BusKnockOutTimer : 40|8@1+ (1,0) [0|254] ""  Vector__XXX
 SG_ NM_TSG_BFS_Wakeup : 48|8@1+ (1.0,0.0) [0.0|255] ""  Vector__XXX
 SG_ KN_TSG_BT_ECUKnockOut : 56|2@1+ (1.0,0.0) [0.0|3] ""  Vector__XXX
 SG_ KN_TSG_BFS_DiagPfad : 60|1@1+ (1.0,0.0) [0.0|1] ""  Gateway_Max
 SG_ NM_TSG_BFS_Lokalaktiv : 61|1@1+ (1.0,0.0) [0.0|1] ""  Vector__XXX
 SG_ NM_TSG_BFS_Subsystemaktiv : 62|1@1+ (1.0,0.0) [0.0|1] ""  Vector__XXX
 SG_ TSG_BFS_KD_Fehler : 63|1@1+ (1.0,0.0) [0.0|1] ""  Gateway_Max

BO_ 2549088330 KN_TSG_FS: 8 TSGGen3_FS
 SG_ TSG_FS_KompSchutz : 0|1@1+ (1.0,0.0) [0.0|1] ""  Vector__XXX
 SG_ TSG_FS_Abschaltstufe : 1|1@1+ (1.0,0.0) [0.0|1] ""  Vector__XXX
 SG_ TSG_FS_Transport_Mode : 2|1@1+ (1.0,0.0) [0.0|1] ""  Vector__XXX
 SG_ TSG_FS_Nachlauftyp : 4|4@1+ (1.0,0.0) [0.0|15] ""  Gateway_Max
 SG_ KN_TSG_FT_ECUKnockOutTimer : 32|6@1+ (1,0) [0|62] ""  Vector__XXX
 SG_ KN_TSG_FT_BusKnockOut : 38|2@1+ (1.0,0.0) [0.0|3] ""  Vector__XXX
 SG_ KN_TSG_FS_BusKnockOutTimer : 40|8@1+ (1,0) [0|254] ""  Vector__XXX
 SG_ NM_TSG_FS_Wakeup : 48|8@1+ (1.0,0.0) [0.0|255] ""  Vector__XXX
 SG_ KN_TSG_FT_ECUKnockOut : 56|2@1+ (1.0,0.0) [0.0|3] ""  Vector__XXX
 SG_ KN_TSG_FS_DiagPfad : 60|1@1+ (1.0,0.0) [0.0|1] ""  Gateway_Max
 SG_ NM_TSG_FS_Lokalaktiv : 61|1@1+ (1.0,0.0) [0.0|1] ""  Vector__XXX
 SG_ NM_TSG_FS_Subsystemaktiv : 62|1@1+ (1.0,0.0) [0.0|1] ""  Vector__XXX
 SG_ TSG_FS_KD_Fehler : 63|1@1+ (1.0,0.0) [0.0|1] ""  Gateway_Max

CM_ BO_ 2527679583 "ehemals ZFAS_01";
CM_ BO_ 2621505536 "VWAG Diagnose funktionaler Request auf CANFD";
CM_ BO_ 2549874838 "Lichtsteuerung links am Frontlicht-CAN";
CM_ BO_ 2550005910 "Lichtsteuerung links am Frontlicht-CAN";
CM_ BO_ 2549874839 "Lichtsteuerung rechts am Frontlicht-CAN";
CM_ BO_ 2550005911 "Lichtsteuerung rechts am Frontlicht-CAN";
CM_ BO_ 960 "MQB";
CM_ BO_ 1646 "ab MQB 7.3";
CM_ BO_ 1640 "ab MQB IS-4";
CM_ BO_ 1712 "1:1 LIN-CAN Botschaft, Originalsender ist Regen-/Licht-/Feuchtesensor auf dem BCM-LIN1";
CM_ BO_ 1505 "ab MQB 7.3";

CM_ SG_ 1524 AMB_Charisma_FahrPr "MLBevo: Aktuelles Fahrprogramm des Charisma-Teilnehmers (siehe Systemlastenheft Drive Select)
MQB: Istwert der Kennlinie (siehe Systemlastenheft MQB FPA)";
CM_ SG_ 1524 AMB_Charisma_Status "Systemstatus des Charismateilnehmers

Wert 0x3 ist nur für Fahrzeuge ab MQB relevant";
CM_ SG_ 1524 BCM1_DI_Rampe_Innenlicht "Dimmrampe Innenlicht";
CM_ SG_ 1524 BCM1_DI_Rampe_Leselicht "Dimmrampe Leselicht";
CM_ SG_ 1524 BCM1_Innenlicht_gedimmt_H "Steuerung von BCM_Innenlicht_H";
CM_ SG_ 1524 BCM1_Innenlicht_gedimmt_V "Steuerung von BCM_Innenlicht_V";
CM_ SG_ 1524 BCM1_Innenlicht_H "Anforderung Innenlicht hinten";
CM_ SG_ 1524 BCM1_Innenlicht_V "Anforderung Innenlicht vorne";
CM_ SG_ 1524 BCM1_Leselicht_Anf_hl " Leselicht hinten links Anforderung";
CM_ SG_ 1524 BCM1_Leselicht_Anf_hr "Leselicht hinten rechts Anforderung";
CM_ SG_ 1524 BCM1_Leselicht_Anf_vl "Leselicht vorne links Anforderung";
CM_ SG_ 1524 BCM1_Leselicht_Anf_vr "Leselicht vorne rechts Anforderung";
CM_ SG_ 1524 BCM1_Leuchten_Aus "Innenbeleuchtung ausschalten (keine Änderung / ausschalten)";
CM_ SG_ 1524 IL_Bel_BFS_Ausstieg "Einschalten der Ausstiegsleuchten oder Türwarnleuchten in Tür oder im Schweller";
CM_ SG_ 1524 IL_Bel_FS_Ausstieg "Einschalten der Ausstiegsleuchten oder Türwarnleuchten in Tür oder im Schweller";
CM_ SG_ 1524 IL_Bel_HBFS_Ausstieg "Einschalten der Ausstiegsleuchten oder Türwarnleuchten in Tür oder im Schweller";
CM_ SG_ 1524 IL_Bel_HFS_Ausstieg "Einschalten der Ausstiegsleuchten oder Türwarnleuchten in Tür oder im Schweller";
CM_ SG_ 1524 IL_Dimmung_H_Tuerkontur "Dimmung Türkontur hinten (bei Änderung im 30 ms Raster)";
CM_ SG_ 1524 IL_Dimmung_Lautspr "Dimmung Umfeldbeleuchtung an Türaußenseite oder Außenspiegel";
CM_ SG_ 1524 IL_Dimmung_Tuerinnengriff "Dimmung Türinnengriff";
CM_ SG_ 1524 IL_Dimmung_Umfeldbel "Dimmung Umfeldbeleuchtung an Türaußenseite oder Außenspiegel";
CM_ SG_ 1524 IL_Dimmung_V_Tuerkontur "Dimmung Türkontur vorne (bei Änderung im 30 ms Raster)";
CM_ SG_ 1524 IL_Innenlicht_aktiv "Status Innenlicht";
CM_ SG_ 1524 IL_Klemme_30G_aktiv "Synchrones Abschalten";

CM_ SG_ 2527679583 IPA_02_BZ "4bit Botschaftszähler, wird mit jeder Sendebotschaft inkrementiert";
CM_ SG_ 2527679583 IPA_02_CRC "Für MLB:
Berechnung siehe Lastenheft 'Kommunikationsabsicherung für FlexRay und CAN'
Ab MQB und MLBevo:
Berechnung siehe Lastenheft 'End-to-End Kommunikationsabsicherung'

Endwerte siehe Begleitdokument 'S-PDU Kennungsfolgen'";
CM_ SG_ 2527679583 IPA_Akustik_PL_gefunden "Signalisiert ein akustische Benachrichtigung, dass Parklücken gefunden wurden.";
CM_ SG_ 2527679583 IPA_Anf_Meldungen "Das Signal fordert die Anzeige einer Meldung an. Jedem Signalwert ist eine Meldung zugeordnet. Das Signal ist derzeit für die Funktionen IPA/RPA und TPA implementiert.";
CM_ SG_ 2527679583 IPA_PL_Anzeige_links "Zeigt an, ob auf der linken Seite eine Parklücke erkannt wurde.";
CM_ SG_ 2527679583 IPA_PL_Anzeige_rechts "Zeigt an, ob auf der rechten Seite eine Parklücke erkannt wurde.";
CM_ SG_ 2527679583 Parken_aktives_System_02 "zeigt an welches parkendes System aktiv ist";
CM_ SG_ 2527679583 Parken_Aktivierungslicht_Anf "Anforderung des Aktivierungslichts nach erfolgreicher Aktivierungshandlung seitens Pilotiertem Parken.";
CM_ SG_ 2527679583 Parken_Bestaetigungsblinken_Anf "Anforderung seitens Pilotiertem Parken für ein Erfolgsblinken nach dem Erreichen der Zielposition bzw. für ein Abbruchsblinken bei Eintreten einer Abbruchsbedingung.";
CM_ SG_ 2527679583 Parken_Blinker_li_Anf "Anforderung seitens Parkens für 'Links blinken'";
CM_ SG_ 2527679583 Parken_Blinker_re_Anf "Anforderung seitens Parken für 'Rechts blinken'";
CM_ SG_ 2527679583 Parken_Fahrbereitschaftlicht_Anf "Anforderung des Fahrbereitschaftslichts";
CM_ SG_ 2527679583 Parken_Fahrerhinweise_Anf "Anforderung zur erneuten Lampenaufprüfung und Anzeige von Warnhinweisen nach einem pilotierten Ausparkvorgang.";
CM_ SG_ 2527679583 Parken_Fahrtrichtungslicht_Anf "Anforderung seitens Pilotiertem Parken für die Anzeige der initialen Fahrtrichtung nach Systemaktivierung.";
CM_ SG_ 2527679583 Parken_FFB_LED_Anf "Statusinformation des Pilotierten Parkens für die Ansteuerung der LED auf der Funkfernbedienung.";
CM_ SG_ 2527679583 Parken_Lichtnachlauf_Anf "Anforderung des Lichtnachlaufs beim BCM1 (analog Verlassenskonzept) für das Pilotierte Parken. ";
CM_ SG_ 2527679583 Parken_Lichtsteuerung_Anf "Anforderung zum Setzen des Lichtmodus des Fahrzeuges von der Parkfunktion";
CM_ SG_ 2527679583 Parken_Schluesselsuche_Anf "Ansteuerung der Schlüsselsuche für das pilotierte Parken.";
CM_ SG_ 2527679583 Parken_Seitenspiegel_Anf "Anforderung für Seitenspiegel an- oder abklappen beim PiloPa";
CM_ SG_ 2527679583 Parken_Wegfahrsperren_Anf "Ansteuerung der Wegfahrsperren Komponenten für das pilotierte Parken.  ";
CM_ SG_ 2527679583 Parken_ZR_Sondermodus_Anf "Anforderung Sondermodus, um beim „pilotierten Parken“ spezielle Funktionsanpassungen im Infotainment-Bereich zu ermöglichen (u.a. schnellerer Startup, Abschaltung BT)";
CM_ SG_ 2527679583 Parken_ZV_Schliessen "Anforderung für Zentralverriegelung verriegeln oder safen beim PiloPa";

CM_ SG_ 1806 ISO_BCM1_Req_Data "OffBoard Tester Diagnose Request BCM1";

CM_ SG_ 1912 ISO_BCM1_Resp_Data "OffBoard Tester Diagnose Response BCM1";

CM_ SG_ 1792 ISO_ALL_01_Req_Data "Funktionaler Request ALL";

CM_ SG_ 1842 ISO_Kessy_Req_Data "Diagnose Request Keyless Entry System";

CM_ SG_ 1948 ISO_Kessy_Resp_Data "Diagnose Response Keyless Entry System";

CM_ SG_ 1867 ISO_TSG_BT_Req_Data "OffBoard Tester Diagnose Request TSG_BT";

CM_ SG_ 1973 ISO_TSG_BT_Resp_Data "OffBoard Tester Diagnose Response TSG_BT";

CM_ SG_ 1866 ISO_TSG_FT_Req_Data "OffBoard Tester Diagnose Request TSG_FT";

CM_ SG_ 1972 ISO_TSG_FT_Resp_Data "OffBoard Tester Diagnose Response TSG_FT";

CM_ SG_ 1855 ISO_TSG_HBFS_Req_Data "OffBoard Tester Diagnose Request TSG_HBFS";

CM_ SG_ 1961 ISO_TSG_HBFS_Resp_Data "OffBoard Tester Diagnose Response TSG_HBFS";

CM_ SG_ 1854 ISO_TSG_HFS_Req_Data "OffBoard Tester Diagnose Request TSG_HFS";

CM_ SG_ 1960 ISO_TSG_HFS_Resp_Data "OffBoard Tester Diagnose Response TSG_HFS";

CM_ SG_ 2621440014 ISOx_BCM1_Req_FD_Data "Diagnose Request BCM";

CM_ SG_ 2621571086 ISOx_BCM1_Resp_FD_Data "Diagnose Response FD BCM";

CM_ SG_ 2549874874 ISOx_DDA_Req_Data "Diagnose Request DDA";

CM_ SG_ 2550005946 ISOx_DDA_Resp_Data "Diagnose Response CAN HS";

CM_ SG_ 2621505536 ISOx_Funkt_Req_All_FD_Data "OffBoard Tester funktionaler Diagnose Request ALL CANFD";

CM_ SG_ 2549874838 ISOx_LED_LM_L_Req_Data "Diagnose Resquest Steuergeraet für LED-Scheinwerfer links";

CM_ SG_ 2550005910 ISOx_LED_LM_L_Resp_Data "OffBoard Tester Diagnose Response LED_LM_L";

CM_ SG_ 2549874839 ISOx_LED_LM_R_Req_Data "Diagnose Request Steuergeraet für LED-Scheinwerfer rechts";

CM_ SG_ 2550005911 ISOx_LED_LM_R_Resp_Data "OffBoard Tester Diagnose Response LED_LM_R";

CM_ SG_ 2550398979 ISOx_RSAD_HL_Req_Data "OffBoard Tester Diagnose Request RSAD_HL";

CM_ SG_ 2621702147 ISOx_RSAD_HL_Req_FD_Data "OffBoard Tester Diagnose Response RSAD_HL";

CM_ SG_ 2550530051 ISOx_RSAD_HL_Resp_Data "OffBoard Tester Diagnose Response RSAD_HL";

CM_ SG_ 2621833219 ISOx_RSAD_HL_Resp_FD_Data "OffBoard Tester Diagnose Response RSAD_HL";

CM_ SG_ 2550398980 ISOx_RSAD_HR_Req_Data "OffBoard Tester Diagnose Request RSAD_HR";

CM_ SG_ 2621702148 ISOx_RSAD_HR_Req_FD_Data "OffBoard Tester Diagnose Response RSAD_HR";

CM_ SG_ 2550530052 ISOx_RSAD_HR_Resp_Data "OffBoard Tester Diagnose Response RSAD_HR";

CM_ SG_ 2621833220 ISOx_RSAD_HR_Resp_FD_Data "OffBoard Tester Diagnose Response RSAD_HR";

CM_ SG_ 2550399029 ISOx_RSAD_IN2_Req_Data "OffBoard Tester Diagnose Request RSAD_IN2";

CM_ SG_ 2621702197 ISOx_RSAD_IN2_Req_FD_Data "OffBoard Tester Diagnose Response RSAD_IN2";

CM_ SG_ 2550530101 ISOx_RSAD_IN2_Resp_Data "OffBoard Tester Diagnose Response RSAD_IN2";

CM_ SG_ 2621833269 ISOx_RSAD_IN2_Resp_FD_Data "OffBoard Tester Diagnose Response RSAD_IN2";

CM_ SG_ 2550399030 ISOx_RSAD_IN3_Req_Data "OffBoard Tester Diagnose Request RSAD_IN3";

CM_ SG_ 2621702198 ISOx_RSAD_IN3_Req_FD_Data "OffBoard Tester Diagnose Response RSAD_IN3";

CM_ SG_ 2550530102 ISOx_RSAD_IN3_Resp_Data "OffBoard Tester Diagnose Response RSAD_IN3";

CM_ SG_ 2621833270 ISOx_RSAD_IN3_Resp_FD_Data "OffBoard Tester Diagnose Response RSAD_IN3";

CM_ SG_ 2550399031 ISOx_RSAD_IN4_Req_Data "OffBoard Tester Diagnose Request RSAD_IN4";

CM_ SG_ 2621702199 ISOx_RSAD_IN4_Req_FD_Data "OffBoard Tester Diagnose Response RSAD_IN4";

CM_ SG_ 2550530103 ISOx_RSAD_IN4_Resp_Data "OffBoard Tester Diagnose Response RSAD_IN4";

CM_ SG_ 2621833271 ISOx_RSAD_IN4_Resp_FD_Data "OffBoard Tester Diagnose Response RSAD_IN4";

CM_ SG_ 2550398981 ISOx_RSAD_IN_Req_Data "Diagnose Request Relay Station Attack Device 5 (Innenraum)";

CM_ SG_ 2621702149 ISOx_RSAD_IN_Req_FD_Data "OffBoard Tester Diagnose Response RSAD_IN";

CM_ SG_ 2550530053 ISOx_RSAD_IN_Resp_Data "OffBoard Tester Diagnose Response RSAD_IN";

CM_ SG_ 2621833221 ISOx_RSAD_IN_Resp_FD_Data "OffBoard Tester Diagnose Response RSAD_IN";

CM_ SG_ 2550398977 ISOx_RSAD_VL_Req_Data "Diagnose Request Relay Station Attack Device 1 (vorne links)";

CM_ SG_ 2621702145 ISOx_RSAD_VL_Req_FD_Data "OffBoard Tester Diagnose Response RSAD_VL";

CM_ SG_ 2550530049 ISOx_RSAD_VL_Resp_Data "Diagnose Response Relay Station Attack Device 1 (vorne links)";

CM_ SG_ 2621833217 ISOx_RSAD_VL_Resp_FD_Data "OffBoard Tester Diagnose Response RSAD_VL";

CM_ SG_ 2550398978 ISOx_RSAD_VR_Req_Data "OffBoard Tester Diagnose Request RSAD_VR";

CM_ SG_ 2621702146 ISOx_RSAD_VR_Req_FD_Data "OffBoard Tester Diagnose Response RSAD_VR";

CM_ SG_ 2550530050 ISOx_RSAD_VR_Resp_Data "OffBoard Tester Diagnose Response RSAD_VR";

CM_ SG_ 2621833218 ISOx_RSAD_VR_Resp_FD_Data "OffBoard Tester Diagnose Response RSAD_VR";

CM_ SG_ 2621440075 ISOx_TSG_BT_Req_FD_Data "Diagnose Request TSG_BT";

CM_ SG_ 2621571147 ISOx_TSG_BT_Resp_FD_Data "Diagnose Response TSG_BT";

CM_ SG_ 2621440074 ISOx_TSG_FT_Req_FD_Data "Diagnose Request TSG_FS";

CM_ SG_ 2621571146 ISOx_TSG_FT_Resp_FD_Data "Diagnose Response TSG_FT";

CM_ SG_ 2621440063 ISOx_TSG_HBFS_Req_FD_Data "OffBoard Tester Diagnose Response TSG_HBFS";

CM_ SG_ 2621571135 ISOx_TSG_HBFS_Resp_FD_Data "OffBoard Tester Diagnose Response TSG_HBFS";

CM_ SG_ 2621440062 ISOx_TSG_HFS_Req_FD_Data "OffBoard Tester Diagnose Response TSG_HFS";

CM_ SG_ 2621571134 ISOx_TSG_HFS_Resp_FD_Data "OffBoard Tester Diagnose Response TSG_HFS";

CM_ SG_ 2549874853 ISOx_WLC1_Req_Data "OffBoard Tester Diagnose Request WLC1";

CM_ SG_ 2621440165 ISOx_WLC1_Req_FD_Data "OffBoard Tester Diagnose Response WLC1";

CM_ SG_ 2550005925 ISOx_WLC1_Resp_Data "OffBoard Tester Diagnose Response WLC1";

CM_ SG_ 2621571237 ISOx_WLC1_Resp_FD_Data "OffBoard Tester Diagnose Response WLC1";

CM_ SG_ 1425 KY_3_Bremslicht_Ein "Schaltet das dritte Bremslicht ein, wenn das virtuelle Heckklappenpedal aktiv ist";
CM_ SG_ 1425 KY_Bdraten_Rueckspr "Schaltet den Receiver auf 1,7 kBaud zurück";
CM_ SG_ 1425 KY_BFS_Entr "Schlüssel im Fzg.: BFS wieder entriegeln";
CM_ SG_ 1425 KY_Burst_1 "Burst 1 an BCM";
CM_ SG_ 1425 KY_Burst_2 "Burst 2 an BCM";
CM_ SG_ 1425 KY_Burst_3 "Burst 3 an BCM";
CM_ SG_ 1425 KY_Entry_ETuer_HBFS "1 = Entriegelung der elektrischen Schiebetür durch TAG HBFS angestoßen.";
CM_ SG_ 1425 KY_Entry_ETuer_HFS "1 = Entriegelung der elektrischen Schiebetür durch TAG HFS angestoßen.";
CM_ SG_ 1425 KY_FS_Entr "Schlüssel im Fzg.: FS wieder entriegeln";
CM_ SG_ 1425 KY_Gesamt_Entr "Kessy ID-Geber im Fahrzeug: ZV soll komplett entriegelt werden.";
CM_ SG_ 1425 KY_HBFS_Entr "Schlüssel im Fzg.: HBFS wieder entriegeln";
CM_ SG_ 1425 KY_HD_Entr "HD entriegeln oder Softtouch freigeben (abhängig von Codierung des BCM)
Ursache der Entriegelung: virtuelles Pedal aktiv oder Schlüssel im Fzg. gefunden";
CM_ SG_ 1425 KY_HFS_Entr "Schlüssel im Fzg.: HFS wieder entriegeln";
CM_ SG_ 1425 KY_HS_Entr "Schlüssel im Fzg.: Heckscheibe wieder entriegeln";
CM_ SG_ 1425 KY_Schliessverh_HD "Kein Schlüssel im Fzg.: HD freigeben, kann durch HDSG geschlossen werden";
CM_ SG_ 1425 KY_VirtuellesPedal_HK "1 = Virtuelles Pedal am Heck betätigt";
CM_ SG_ 1425 KY_Zufallszahl "Zufallszahl auf Anforderung vom Kessy zum BCM";

CM_ SG_ 1426 KY_Aktive_LFScans "Signalisierung eines aktiven Kessy-Scans (LF auf 125kHz) mit Angabe der Scanart";
CM_ SG_ 1426 KY_AnzKoord_Info "Signalisierung, ob beim Kessy-Scan ein Schlüssel gefunden wurde (1) oder nicht (2)";
CM_ SG_ 1426 KY_EasyClose_Abbruch "ID-Geber während HD-Zufahrt im Nahbereich EasyClose erkannt";
CM_ SG_ 1426 KY_EasyClose_Status "Signal zur LED Ansteuerung im HD-Verriegelungstaster für die Funktion EasyClose.";
CM_ SG_ 1426 KY_Fzg_Verlassen_erkannt "Fahrer/Schlüssel hat das Fahrzeug verlassen und FT wurde geschlossen";
CM_ SG_ 1426 KY_Fzg_Zugang_erkannt "Fahrer/Schlüssel hat Fahrzeug betreten und die FT geschlossen";
CM_ SG_ 1426 KY_Gestik_HD "Aktive Funktion (Gestikgesteuerte Heckklappe) im Kessy-SG";
CM_ SG_ 1426 KY_Gong_600 "Gong zum Meldungstext (1=aktiv)";
CM_ SG_ 1426 KY_HD_Auffahrt "Auffahrt HD nach Wiedereintritt ID-Geber in EasyClose Nahbereich";
CM_ SG_ 1426 KY_HD_Zufahrt "Zufahrt HD nach erfolgreicher Funktion EasyClose";
CM_ SG_ 1426 KY_ID_Geber1_im_Fzg "1 = ID-Geber 1 im Innenraum erkannt";
CM_ SG_ 1426 KY_ID_Geber2_im_Fzg "1 = ID-Geber 2 im Innenraum erkannt";
CM_ SG_ 1426 KY_ID_Geber3_im_Fzg "1 = ID-Geber 3 im Innenraum erkannt";
CM_ SG_ 1426 KY_ID_Geber4_im_Fzg "1 = ID-Geber 4 im Innenraum erkannt";
CM_ SG_ 1426 KY_ID_Geber_Suche "1 = Transponder Scan aktiv";
CM_ SG_ 1426 KY_LF_Aktiv "LF Schluesselkommunikation
";
CM_ SG_ 1426 KY_Meldungen "Kessy-Meldungen:
0 = keine Meldung
1 = Meldung: 'Schlüssel nicht gefunden!' bei Kl.15 ein
2= Meldung: 'Schlüssel im Kofferraum!'
3 = Meldung: 'Schlüssel im Fahrzeug'
4 = Meldung: 'KESSY defekt'
5-15: tbd";
CM_ SG_ 1426 KY_Passiv_Autolock "Aktive Funktion (Passiv Autolock) im Kessy-SG";
CM_ SG_ 1426 KY_Passiv_Autolock_Akt "1 = Funktionszustand im Kessy-SG: 'Passiv Autolock / Autounlock'";
CM_ SG_ 1426 KY_Passiv_Autolock_Menue "1 = Menue-Eintrag 'Passiv Autolock / Autounlock' aktivieren";
CM_ SG_ 1426 KY_Passiv_Autounlock "Aktive Funktion (Passiv Autounlock) im Kessy-SG";
CM_ SG_ 1426 KY_Schluesselposition_1 "Status des ID-Gebers 1 aus der letzten durchgeführten Schlüsselsuche für Remote Parkfunktionen

0 = nicht_gefunden
1 = im_Innenraum_gefunden
2 = im_Außenraum_gefunden_nah, Distanz <= parametrierter Schwelle
3 = im_Außenraum_gefunden_fern, Distanz > p";
CM_ SG_ 1426 KY_Schluesselposition_2 "Status des ID-Gebers 2 aus der letzten durchgeführten Schlüsselsuche für Remote Parkfunktionen

0 = nicht_gefunden
1 = im_Innenraum_gefunden
2 = im_Außenraum_gefunden_nah, Distanz <= parametrierter Schwelle
3 = im_Außenraum_gefunden_fern, Distanz > p";
CM_ SG_ 1426 KY_Schluesselposition_3 "Status des ID-Gebers 3 aus der letzten durchgeführten Schlüsselsuche für Remote Parkfunktionen

0 = nicht_gefunden
1 = im_Innenraum_gefunden
2 = im_Außenraum_gefunden_nah, Distanz <= parametrierter Schwelle
3 = im_Außenraum_gefunden_fern, Distanz > p";
CM_ SG_ 1426 KY_Schluesselposition_4 "Status des ID-Gebers 4 aus der letzten durchgeführten Schlüsselsuche für Remote Parkfunktionen

0 = nicht_gefunden
1 = im_Innenraum_gefunden
2 = im_Außenraum_gefunden_nah, Distanz <= parametrierter Schwelle
3 = im_Außenraum_gefunden_fern, Distanz > p";
CM_ SG_ 1426 KY_Schluesselposition_5 "Status des ID-Gebers 5 aus der letzten durchgeführten Schlüsselsuche für Remote Parkfunktionen

0 = nicht_gefunden
1 = im_Innenraum_gefunden
2 = im_Außenraum_gefunden_nah, Distanz <= parametrierter Schwelle
3 = im_Außenraum_gefunden_fern, Distanz > p";
CM_ SG_ 1426 KY_Schluesselposition_6 "Status des ID-Gebers 6 aus der letzten durchgeführten Schlüsselsuche für Remote Parkfunktionen

0 = nicht_gefunden
1 = im_Innenraum_gefunden
2 = im_Außenraum_gefunden_nah, Distanz <= parametrierter Schwelle
3 = im_Außenraum_gefunden_fern, Distanz > p";
CM_ SG_ 1426 KY_Schluesselposition_7 "Status des ID-Gebers 7 aus der letzten durchgeführten Schlüsselsuche für Remote Parkfunktionen

0 = nicht_gefunden
1 = im_Innenraum_gefunden
2 = im_Außenraum_gefunden_nah, Distanz <= parametrierter Schwelle
3 = im_Außenraum_gefunden_fern, Distanz > p";
CM_ SG_ 1426 KY_Schluesselposition_8 "Status des ID-Gebers 8 aus der letzten durchgeführten Schlüsselsuche für Remote Parkfunktionen

0 = nicht_gefunden
1 = im_Innenraum_gefunden
2 = im_Außenraum_gefunden_nah, Distanz <= parametrierter Schwelle
3 = im_Außenraum_gefunden_fern, Distanz > p";
CM_ SG_ 1426 KY_Schluesselposition_9 "Status des ID-Gebers 9 (MDK) aus der letzten durchgeführten Schlüsselsuche für Remote Parkfunktionen

0 = nicht_gefunden
1 = im_Innenraum_gefunden
2 = im_Außenraum_gefunden_nah, Distanz <= parametrierter Schwelle
3 = im_Außenraum_gefunden_fern, Dista";
CM_ SG_ 1426 KY_Startknopf_Bel "Startknopf beleuchten";
CM_ SG_ 1426 KY_StartStopp_Info "Stopp-Freigabe und Start-Anforderung an den Start-Stopp-Koordinator";

CM_ SG_ 960 BCM_Ausparken_Betrieb "Anforderung zur erneuten Lampenaufprüfung und Anzeige von Warnhinweisen nach einem pilotierten Ausparkvorgang (Trigger: fallende Flanke)";
CM_ SG_ 960 BCM_Remotestart_Betrieb "Zeigt den Status des RemoteStarts an, d.h. KL15_RSt ist aktiviert und der Motorlauf ist im RSt-Betrieb aktiv.";
CM_ SG_ 960 BCM_Remotestart_KL15_Anf "Zeigt den Status der Aktivierung der KL15_RST durch das BCM an.";
CM_ SG_ 960 BCM_Remotestart_MO_Start "Nachdem das BCM die Remotestart MSG Freigabe sicher erkannt hat, fordert das BCM wiederum über dieses Signal vom MSG einen Motorstart durchzuführen.";
CM_ SG_ 960 Klemmen_Status_01_BZ "4bit Botschaftszaehler; wird in jeder Sendebotschaft inkrementiert";
CM_ SG_ 960 Klemmen_Status_01_CRC "Für MLB:
'Berechnung siehe Lastenheft 'Kommunikationsabsicherung für FlexRay und CAN''

Ab MQB und MLBevo:
'Berechnung siehe Lastenheft 'End-to-End Kommunikationsabsicherung''

Endwerte siehe Begleitdokument 'S-PDU Kennungsfolgen'";
CM_ SG_ 960 KST_Fahrerhinweis_1 "Signalisierung Fahrerhinweis 1 der Klemmensteuerung an das Kombi";
CM_ SG_ 960 KST_Fahrerhinweis_2 "Signalisierung Fahrerhinweis 2 der Klemmensteuerung an das Kombi";
CM_ SG_ 960 KST_Fahrerhinweis_4 "Signalisierung Fahrerhinweis 4 der Klemmensteuerung an das Kombi";
CM_ SG_ 960 KST_Fahrerhinweis_5 "Anzeigesignal für RemoteStart";
CM_ SG_ 960 KST_Fahrerhinweis_6 "Signal aktiviert die Kombi-Anzeigeinstrumente (Drehzahl, Tankinhalt, Kühlmitteltemperatur) während aktiviertem RemoteStart-Betrieb";
CM_ SG_ 960 KST_Warn_P1_ZST_def "Kombi Prio Warnung Klemmensteuerung 
Zündschloß defekt, Service aufsuchen!";
CM_ SG_ 960 KST_Warn_P2_ZST_def "Kombi Prio Warnung Klemmensteuerung
Zündschloß defekt!
";
CM_ SG_ 960 RSt_Fahrerhinweise "Über das Signal fordert das BCM Fahrerhinweise im Kombi für die Funktion RemoteStart an.";
CM_ SG_ 960 ZAS_Kl_15 "Klemme 15: Zuendung (SW-Kl.15)
";
CM_ SG_ 960 ZAS_Kl_50_Startanforderung "Klemme 50: Startwunsch Fahrer
";
CM_ SG_ 960 ZAS_Kl_Infotainment "Separate Klemmeninformation für das Infotainment. Signal entspricht im wesentlichen einer Klemme S Information, kann aber über einen Vor - bzw. Nachlauf zu Klemme S verfügen. 
Ein konkreter Anwendungsfall für einen Nachlauf ist die Abschaltung der Klemme";
CM_ SG_ 960 ZAS_Kl_S "Klemme S: S-Kontakt (Schluessel steckt)
";
CM_ SG_ 960 ZAS_Kl_X "Klemme 75
";

CM_ SG_ 2463978753 Klemmen_Status_02_BZ "4bit Botschaftszähler, wird mit jeder Sendebotschaft inkrementiert";
CM_ SG_ 2463978753 Klemmen_Status_02_CRC "Für MLB:
Berechnung siehe Lastenheft 'Kommunikationsabsicherung für FlexRay und CAN'
Ab MQB und MLBevo:
Berechnung siehe Lastenheft 'End-to-End Kommunikationsabsicherung'

Endwerte siehe Begleitdokument 'S-PDU Kennungsfolgen'";
CM_ SG_ 2463978753 KST_ComfortReadyStatus "Zustand des ComfortReadyStatus über den Komfortfunktionen aktiviert werden können.";
CM_ SG_ 2463978753 KST_Freigabe_Zustand "Gibt den Sperr- bzw. Freigabezustand der Klemmensteuerung während SW-Update (z. B. Infotainment) an";
CM_ SG_ 2463978753 KST_Sonderzustand_Anforderung "Hiermit wird die aktive bzw. aktuell angeforderte (s. KST_Sonderzustand_Status) Sonderfunktion identifiziert";
CM_ SG_ 2463978753 KST_Sonderzustand_Status "Hiermit wird signalisiert, dass eine Sonderfunktion aktiv ist und die Klemme 15 durch diese angefordert wurde bzw. ein Übergang von Sonderfunktionen stattfindet";
CM_ SG_ 2463978753 KST_WFS_Fahrfreigabe_Anforderung "Hiermit wird den Wegfahrsperren-Teilnehmern signalisiert welche Art der Fahrfreigabe von der anfordernden Sonderfunktion benötigt wird";

CM_ SG_ 1420 Klemmen_Steuerung_01_BZ "4bit Botschaftszaehler; wird in jeder Sendebotschaft inkrementiert";
CM_ SG_ 1420 Klemmen_Steuerung_01_CRC "Ab MQB und MLBevo:
'Berechnung siehe Lastenheft 'End-to-End Kommunikationsabsicherung''

Endwerte siehe Begleitdokument 'S-PDU Kennungsfolgen'";
CM_ SG_ 1420 KST_Anf_Klemme_15 "Anforderung der Klemme 15 an das BCM. Signal wird zur Plausibilisierung parallel zum Klemmensignal auf dem CAN übertragen.";
CM_ SG_ 1420 KST_Anf_Klemme_50 "Anforderung der Klemme 50 an das MSG. Signal wird zur Plausibilisierung parallel zum Klemmensignal auf dem CAN übertragen.";
CM_ SG_ 1420 KST_Anf_Klemme_S "Anforderung der Klemme S an das BCM. Signal wird zur Plausibilisierung parallel zum Klemmensignal auf dem CAN übertragen.";
CM_ SG_ 1420 KST_Anf_Klemmenfreigabe_ELV "Klemmensteuerung fordert Klemmen-Freigabe durch die ELV an.";
CM_ SG_ 1420 KST_Anf_Klemmenfreigabe_WFS "Anforderung der Freigabe von der WFS zum Einschalten von Klemme 15 und Klemme S";
CM_ SG_ 1420 KST_Anf_ZV_Verriegelung "Neuer Verriegelungstrigger für die ZV nach der automatischen Klemmenabschaltung.

Wird bei Kessyfahrzeugen mit StartStop ein aktiver Stop-Mode und Fahrerverlassen erkannt, startet ein 30 Sekunden-Timer. Innerhalb dieser 30 Sekunden hat der Fahrer die Mö";
CM_ SG_ 1420 KST_Anzeige_Klemmenzustand "Klemmensteuerung zeigt (Fehler-)zustände nach/während Update Infotainment bzgl. Klemme 50 an";
CM_ SG_ 1420 KST_aut_Abschaltung_Zuendung "Falls bei eingeschalteter Zündung das Abblendlicht aktiv war, muss nach der automatischen Abschaltung der Kl_15 & Kl_S, dass Standlicht aktiv bleiben. Das Signal sendet die Information, dass eine automatische Abschaltung der Kl_15 und Kl_S erfogt.";
CM_ SG_ 1420 KST_Txt_Komfortabschaltung "Dieses Signal fordert im Kombi die Meldung an, die den Fahrer über die ausgeführte automatische Zündungsabschaltung informiert. Signal wird für10s gesendet.";
CM_ SG_ 1420 KST_Txt_P_Gang "Text: 'Wählhebel in Position P bringen!'";
CM_ SG_ 1420 KST_Txt_Panikabschaltung "Text: 'Notabschaltung''";
CM_ SG_ 1420 KST_Txt_Werkstatt "Text: 'Klemmensteuerung! Werkstatt!'";
CM_ SG_ 1420 KST_Unterdr_Zuendungsmeldung "Bei aktivem Signal soll die Zündungsmeldung durch das Kombi unterdrückt werden.";
CM_ SG_ 1420 KST_ZAT_betaetigt "Zündanlass-Taster (ZAT) betätigt";
CM_ SG_ 1420 KST_Zuendungswarnung "Bei aktivem Signal soll je nach gesetztem Status eine Warnung durch das Kombi ausgegeben werden";
CM_ SG_ 1420 Relais_VoKo_angesteuert "Signal zur Rückmeldung, ob das Relais für die Verbraucher von erweiterte Voko / RemoteStart angesteuert wird.";
CM_ SG_ 1420 RSt_Anforderung_HMS "Anforderung vom RSt (Remote Start) an das HMS (Haltemanagement System)";

CM_ SG_ 1646 KL_Anf_AussenspiegelHzg "Anforderung Außenspiegelheizung seitens Klimafunktion (z.B. bei Erweiterter VoKo)";
CM_ SG_ 1646 KL_BCmE_Livetip_Freigabe "Status der Klimaanlage. 
Zeigt an, ob der Livetip 'Fenster schließen wegen Ineffizienz Klimaanlage' sinvollerweise angezeigt werden soll";
CM_ SG_ 1646 KL_ErwVK_Anf "Erweiterte Voko angefordertert / aktiv";
CM_ SG_ 1646 KL_FSH_Automatikbetrieb "Ermöglicht eine Unterscheidung von Anforderung FSH durch Kundenwunsch und Anforderung FSH durch Regelung des Klimasteuergeräts.
Das Signal liegt als Pegel an.";
CM_ SG_ 1646 KL_Geblaese_Fond_Status "Status Geblaese









";
CM_ SG_ 1646 KL_Geblaese_Status "Status Geblaese









";
CM_ SG_ 1646 KL_Heizkreisventilstellung "Bei MQB PHEV: Stellung Heizkreisventil Motor";
CM_ SG_ 1646 KL_I_Geblaese_Fond "Stromaufnahme Gebläse Heck";
CM_ SG_ 1646 KL_Innen_Temp "Innentemperatur

";
CM_ SG_ 1646 KL_Kompressorkupplung "Signal zur Aktivierung/Deaktivierung der Kompressorkupplung";
CM_ SG_ 1646 KL_Magnetventil "Anforderung des Bypassventils.";
CM_ SG_ 1646 KL_Restwaerme_aktiv "Signal zur Aktivierung/Deaktivierung der Wasserpumpe bei Restwärme; 
reduzierte IRÜ Empfindlichkeit";
CM_ SG_ 1646 KL_SH_Soll_hl "Einstellung Sitzheizung hinten links (0...6)";
CM_ SG_ 1646 KL_SH_Soll_hr "Einstellung Sitzheizung hinten rechts (0...6)";
CM_ SG_ 1646 KL_SIH_LEH_Verteilung_VL "Vom Kunden eingestellte Aufteilung der Heizleistung auf Sitzfläche und Lehnefläche für Sitz vorne links";
CM_ SG_ 1646 KL_SIH_LEH_Verteilung_VR "Vom Kunden eingestellte Aufteilung der Heizleistung auf Sitzfläche und Lehnefläche für Sitz vorne rechts";
CM_ SG_ 1646 KL_SIH_LEL_Verteilung_VL "Vom Kunden eingestellte Aufteilung der Lüftungsleistung auf Sitzfläche und Lehnenfläche für Sitz vorne links";
CM_ SG_ 1646 KL_SIH_LEL_Verteilung_VR "Vom Kunden eingestellte Aufteilung der Lüftungsleistung auf Sitzfläche und Lehnenfläche für Sitz vorne rechts";
CM_ SG_ 1646 KL_Solarluefter_aktiv "Betriebsstatus Solarluefter
";
CM_ SG_ 1646 KL_STH_aktiv "Betriebsstatus Standheizung
";
CM_ SG_ 1646 KL_STH_Ansteuerung "Ansteuerung STH

";
CM_ SG_ 1646 KL_STH_Betriebsdauer "Betriebsdauer STH";
CM_ SG_ 1646 KL_STL_aktiv "Betriebsstatus Standlueftung
";
CM_ SG_ 1646 KL_Umluft_Taste "Betaetigung Umlufttaste
";
CM_ SG_ 1646 KL_WaPu "Ansteuerung der Standheizungswasserpumpe";

CM_ SG_ 1640 FSH_Taster "Tasterbetätigung Frontscheibenheizung
";
CM_ SG_ 1640 HSH_Taster "An-/Abforderung Heckscheibenheizung über spezielles Tastersignal
";
CM_ SG_ 1640 KL_Beschlagsgefahr "Beschlagsgefahr auf der Frontscheibe im Bereich des Spiegelfusses. Dient zur präventiven Ansteuerung der  Kamera-Scheibenheizung, um Kamera-Blindheit zu vermeiden
PHEV: volle Leistungsfreigabe 
HV Heizer und HV EKK bei Scheibenbeschlag ";
CM_ SG_ 1640 KL_Geblspng_Fond_Soll "Ausgabe des Sollwertes für die Spannung des Klimagebläsemotores hinten.






";
CM_ SG_ 1640 KL_Geblspng_Soll "Ausgabe des Sollwertes für die Spannung des Klimagebläsemotores vorne.







";
CM_ SG_ 1640 KL_I_Geblaese "Stromaufnahme Gebläse";
CM_ SG_ 1640 KL_Kompressorstrom_soll "Sollvorgabe Klima-Kompressorstrom";
CM_ SG_ 1640 KL_LRH_Stufe "Eingestellte Temperaturstufe der Lenkradheizung";
CM_ SG_ 1640 KL_LRH_Taster "Tasterbetätigung Lenkradheizung";
CM_ SG_ 1640 KL_PTC_Verbauinfo "Im Klima- bzw. Heizungsbedienteil wird der Verbau eines PTCs und dessen elektr. Leistungsklasse codiert";
CM_ SG_ 1640 KL_SIH_Soll_li "Einstellung Sitzheizung Fahrer (0...6)";
CM_ SG_ 1640 KL_SIH_Soll_re "Einstellung Sitzheizung Beifahrer (0...6)";
CM_ SG_ 1640 KL_SIL_Soll_li "Einstellung Sitzlüftung Fahrer (0...6)";
CM_ SG_ 1640 KL_SIL_Soll_re "Einstellung Sitzlüftung Beifahrer (0...6)";
CM_ SG_ 1640 KL_Umluftklappe_Status "Status Umluftklappe";
CM_ SG_ 1640 KL_Zuheizer_Freigabe "Freigabe Zuheizer
";
CM_ SG_ 1640 KRH_Soll_li "Ausgabe des Sollwertes für die Kopfraumheizung links.";
CM_ SG_ 1640 KRH_Soll_re "Ausgabe des Sollwertes für die Kopfraumheizung rechts.";

CM_ SG_ 2527679635 FSH_Status "Fehlerstatus der Frontscheibenheizung
";
CM_ SG_ 2527679635 HSH_Relais_Anf "Relaisanforderung Heckscheibenheizung";
CM_ SG_ 2527679635 KL_AL_HL_Anf "Anforderung an das funktionale Ambientelicht eine Solltemperaturveränderung hinten links darzustellen.";
CM_ SG_ 2527679635 KL_AL_HR_Anf "Anforderung an das funktionale Ambientelicht eine Solltemperaturveränderung hinten rechts darzustellen.";
CM_ SG_ 2527679635 KL_AL_VL_Anf "Anforderung an das funktionale Ambientelicht eine Solltemperaturveränderung vorn links darzustellen.";
CM_ SG_ 2527679635 KL_AL_VR_Anf "Anforderung an das funktionale Ambientelicht eine Solltemperaturveränderung vorn rechts darzustellen.";
CM_ SG_ 2527679635 KL_Defrost_LED "Beleuchtung LED Defrost";
CM_ SG_ 2527679635 KL_FSH_LED "Beleuchtung LED Frontscheibenheizung";
CM_ SG_ 2527679635 KL_FSH_Soll "Sollstatus der Frontscheibenheizung";
CM_ SG_ 2527679635 KL_Heizstufe_LSH "Vom Klimabedienteil gesendete Heizstufe der Luftstandheizung";
CM_ SG_ 2527679635 KL_HSH_LED "Beleuchtung LED Heckscheibenheizung";
CM_ SG_ 2527679635 KL_HSH_Soll "Sollstatus Heckscheibenheizung";
CM_ SG_ 2527679635 KL_HUP_aktiv "Signal des Klimabedienteils ob HUP aktiv ist.

0 = HUP aus
1 = HUP ein";
CM_ SG_ 2527679635 KL_Klappe_Status "Status Luftklappe";
CM_ SG_ 2527679635 KL_LRH_PWM "LRH PWM Signal zur Ansteuerung der Treiberstufe im SMLS (0% - 100%)";
CM_ SG_ 2527679635 KL_LRH_Soll "Sollstatus der Lenkradheizung";
CM_ SG_ 2527679635 KL_LSH_Ansteuerung "Ansteuerung LSH";
CM_ SG_ 2527679635 KL_LSH_Betriebsdauer "Betriebsdauer LSH";
CM_ SG_ 2527679635 KL_LSH_DBetr_Bestaet "Bestätigung des Klimabedienteils an die LSH das Dauerbetrieb tatsächlich angefordert ist.";
CM_ SG_ 2527679635 KL_LSH_DBetr_Ein "Dauerbetrieb der Luftstandheizung Ein";
CM_ SG_ 2527679635 KL_Temp_ZH_Soll "Übertragung der Temperaturvorgabe der Klimaanlage an die Wasserzusatzheizung";
CM_ SG_ 2527679635 KL_VoKo_LED "Signalisierung Vorkonditionierung";
CM_ SG_ 2527679635 KL_Voko_Status "Status der Vorkonditionierung.

0 = aus
1 = ein

14 = Init
15 = Fehler";
CM_ SG_ 2527679635 KL_ZR_Anforderung "Anforderung an MIB die Displays zu aktivieren";
CM_ SG_ 2527679635 SIH_Stufe_LED_li "Statusmeldung Sitzheizung links";
CM_ SG_ 2527679635 SIH_Stufe_LED_re "Statusmeldung Sitzheizung rechts";

CM_ SG_ 1712 FS_Luftfeuchte_rel "gemessene relative Luftfeuchte";
CM_ SG_ 1712 FS_ResponseError "siehe LIN2.0-Specification
(Darf nicht über ein Fehlergueltigkeitsbit abgesichtert werden!)";
CM_ SG_ 1712 FS_Taupunkt "berechneter Taupunkt";
CM_ SG_ 1712 FS_Temp_Scheibe "gemessene Frontscheibentemperatur";
CM_ SG_ 1712 FS_Temp_Sensor "gemessene Sensortemperatur";

CM_ SG_ 1505 BCM1_Aussen_Temp_ungef "ungefilterter Wert des Aussentemperatursensors
";
CM_ SG_ 1505 BCM1_FStatus_Aussentemp_ungef "Fehlerstatus für Aussentemperatur (Kombianzeige)";
CM_ SG_ 1505 BCM1_Kompressorstrom_ist "IST-Strom vom Klima-Kompressor";
CM_ SG_ 1505 BCM1_OBD_FStatus_ATemp "Fehlerstatus Umgebungstemperatursensor (OBD relevanter Sensor)
";
CM_ SG_ 1505 BCM1_PTC_stufig_Status "Status des BCM1-Heizverbrauchers PTC (stufig)";
CM_ SG_ 1505 BCM_Heizungsabsperrventil_Status "Das Signal beschreibt den Zustand des Heizungsabsperrventils, welches als Portexpander vom BCM1 elektrisch angesteuert wird.";
CM_ SG_ 1505 BCM_Heizungspumpe_Status "Das Signal beschreibt den Zustand der Heizungspumpe, welche als Portexpander vom BCM1 elektrisch angesteuert wird.";
CM_ SG_ 1505 BCM_Kompressorkupplung_Status "Das Signal beschreibt den Zustand der Klimakompressorkupplung, welche als Portexpander vom BCM1 elektrisch angesteuert wird.";

CM_ SG_ 605 KLR_01_BZ "Botschaftszähler";
CM_ SG_ 605 KLR_01_CRC "'Berechnung siehe Lastenheft 'End-to-End Kommunikationsabsicherung''

Endwerte siehe Begleitdokument 'S-PDU Kennungsfolgen'";
CM_ SG_ 605 KLR_Fehler "Fehler im KLR System";
CM_ SG_ 605 KLR_Fehler_Codierung "Erkennung eines Fehlers in der Codierung der Datensatzauswahl im KLR";
CM_ SG_ 605 KLR_reserveByte2_6 "Zweck: Befüllen der reservierten Bitpositionen mit 0 (wg. LIN-Teilnehmer KLR)";
CM_ SG_ 605 KLR_reserveByte6_4 "Zweck: Befüllen der reservierten Bitpositionen mit 0 (wg. LIN-Teilnehmer KLR)";
CM_ SG_ 605 KLR_reserveByte7 "Zweck: Befüllen der reservierten Bitpositionen mit 0 (wg. LIN-Teilnehmer KLR)";
CM_ SG_ 605 KLR_reserveByte8 "Zweck: Befüllen der reservierten Bitpositionen mit 0 (wg. LIN-Teilnehmer KLR)";
CM_ SG_ 605 KLR_ResponseError "siehe LIN2.0-Specification
(Darf nicht über ein Fehlergueltigkeitsbit abgesichtert werden!)";
CM_ SG_ 605 KLR_Touchauswertung "Touchauswertung der KLR-Elektronik";
CM_ SG_ 605 KLR_Touchintensitaet_1 "Diskreter Wert der Touchintensität von 0 bis 250 für Sensor 1";
CM_ SG_ 605 KLR_Touchintensitaet_2 "Diskreter Wert der Touchintensität von 0 bis 250 für Sensor 2";
CM_ SG_ 605 KLR_Touchintensitaet_3 "Diskreter Wert der Touchintensität von 0 bis 250 für Sensor 3";

CM_ SG_ 2549088270 BCM1_Abschaltstufe "Funktionseinschränkung aufgrund aktiver Abschaltstufe";
CM_ SG_ 2549088270 BCM1_KD_Fehler "Bei gesetztem Bit ist mindestens ein Kundendienstfehler eingetragen";
CM_ SG_ 2549088270 BCM1_KompSchutz "Funktionseinschränkung aufgrund Komponentenschutz aktiv";
CM_ SG_ 2549088270 BCM1_Nachlauftyp "Abgebildet wird die von der Hardware vorgegebene Möglichkeit, die Kommunikation nach Klemme 15 = AUS aufrecht zu erhalten. Es wird ein Init-Wert gesendet.";
CM_ SG_ 2549088270 BCM1_Transport_Mode "Funktionseinschränkung aufgrund aktivem Transport Mode und/oder Transport Schutz";
CM_ SG_ 2549088270 KN_BCM1_BusKnockOut "Ausgabe des BusKnockout-Status";
CM_ SG_ 2549088270 KN_BCM1_BusKnockOutTimer "Ausgabe des BusKnockOut-Timer";
CM_ SG_ 2549088270 KN_BCM1_DiagPfad "Kennzeichnung der Diagnosefähigkeit des BusInterfaces eines Steuergerätes (Knoten)
Umfang LAH 80127

Bei Nutzung des Signal explizit pro angebundenem BusInterface zu setzen:
MQB auf K-CAN = 0 (aktiv)
MQB2020 auf K-CAN = 0 (aktiv)
MLBevo Gen1 auf K-C";
CM_ SG_ 2549088270 KN_BCM1_ECUKnockOut "Ausgabe des ECUKnockout-Status";
CM_ SG_ 2549088270 KN_BCM1_ECUKnockOutTimer "Ausgabe des ECUKnockOut-Timer";
CM_ SG_ 2549088270 NM_BCM1_Lokalaktiv "Zeigt an ob das SG nach Klemme15 AUS und nach entsprechender MAX Aktivzeit noch aktiv war.";
CM_ SG_ 2549088270 NM_BCM1_Subsystemaktiv "Zeigt an ob ein Subsystem des SGs nach Klemme15 AUS und nach entsprechender MAX Aktivzeit noch aktiv war";
CM_ SG_ 2549088270 NM_BCM1_Wakeup "enthält die Weckursache; stehen mehrere Weckursachen parallel an, dann muss der kleinste Wert übertragen werden";

CM_ SG_ 2549088272 Gateway_Abschaltstufe "Funktionseinschränkung aufgrund aktiver Abschaltstufe";
CM_ SG_ 2549088272 Gateway_KompSchutz "Funktionseinschränkung aufgrund Komponentenschutz aktiv";
CM_ SG_ 2549088272 Gateway_Nachlauftyp "Abgebildet wird die von der Hardware vorgegebene Möglichkeit, die Kommunikation nach Klemme 15 = AUS aufrecht zu erhalten. Es wird ein Init-Wert gesendet.";
CM_ SG_ 2549088272 Gateway_Transport_Mode "Funktionseinschränkung aufgrund aktivem Transport Mode und/oder Transport Schutz";
CM_ SG_ 2549088272 GW_KD_Fehler "Kundendienstfehlerbit Gateway zur Anzeige eines im Gateway abgelegten Fehlerspeichereintrages.";
CM_ SG_ 2549088272 KN_GW_DiagPfad "Kennzeichnung der Diagnosefähigkeit des BusInterfaces eines Steuergerätes (Knoten)
Umfang LAH 80127

Bei Nutzung des Signal explizit pro angebundenem BusInterface zu setzen:
MQB auf Diag-CAN = 0 (aktiv)
MLBevo auf Diag-CAN = 0 (aktiv)
alle weiteren ";
CM_ SG_ 2549088272 NM_Gateway_Wakeup "enthält die Weckursache; stehen mehrere Weckursachen parallel an, dann muss der kleinste Wert übertragen werden";

CM_ SG_ 2549088331 KN_TSG_BFS_BusKnockOutTimer "Ausgabe des BusKnockOut-Timer in der Knotenbotschaft";
CM_ SG_ 2549088331 KN_TSG_BFS_DiagPfad "Kennzeichnung der Diagnosefähigkeit des BusInterfaces eines Steuergerätes (Knoten)
Umfang LAH 80127

Bei Nutzung des Signal explizit pro angebundenem BusInterface zu setzen:
MLBevo auf K-CAN = 0 (aktiv)
MQB auf K-CAN = 0 (aktiv)
MQB2020 auf K-CAN = ";
CM_ SG_ 2549088331 KN_TSG_BT_BusKnockOut "Ausgabe des BusKnockout-Status";
CM_ SG_ 2549088331 KN_TSG_BT_ECUKnockOut "Ausgabe des ECUKnockout-Status";
CM_ SG_ 2549088331 KN_TSG_BT_ECUKnockOutTimer "Ausgabe des ECUKnockOut-Timer";
CM_ SG_ 2549088331 NM_TSG_BFS_Lokalaktiv "Zeigt an ob das SG nach Klemme15 AUS und nach entsprechender MAX Aktivzeit noch aktiv war";
CM_ SG_ 2549088331 NM_TSG_BFS_Subsystemaktiv "Zeigt an ob ein Subsystem des SGs nach Klemme15 AUS und nach entsprechender MAX Aktivzeit noch aktiv war";
CM_ SG_ 2549088331 NM_TSG_BFS_Wakeup "enthält die Weckursache; stehen mehrere Weckursachen parallel an, dann muss der kleinste Wert übertragen werden";
CM_ SG_ 2549088331 TSG_BFS_Abschaltstufe "Funktionseinschränkung aufgrund aktiver Abschaltstufe";
CM_ SG_ 2549088331 TSG_BFS_KD_Fehler "Status Kundendienstfehlerspeichereinträge
";
CM_ SG_ 2549088331 TSG_BFS_KompSchutz "Funktionseinschränkung aufgrund Komponentenschutz aktiv";
CM_ SG_ 2549088331 TSG_BFS_Nachlauftyp "Abgebildet wird die von der Hardware vorgegebene Möglichkeit, die Kommunikation nach Klemme 15 = AUS aufrecht zu erhalten. Es wird ein Init-Wert gesendet.
0 = Kommunikation nur bei KL15=EIN (kein Nachlauf, nicht weckfähig)
1 = Kommunikation nach KL15=AU";
CM_ SG_ 2549088331 TSG_BFS_Transport_Mode "Funktionseinschränkung aufgrund aktivem Transport Mode und/oder Transport Schutz";

CM_ SG_ 2549088330 KN_TSG_FS_BusKnockOutTimer "Ausgabe des BusKnockOut-Timer in der Knotenbotschaft";
CM_ SG_ 2549088330 KN_TSG_FS_DiagPfad "Kennzeichnung der Diagnosefähigkeit des BusInterfaces eines Steuergerätes (Knoten)
Umfang LAH 80127

Bei Nutzung des Signal explizit pro angebundenem BusInterface zu setzen:
MLBevo auf K-CAN = 0 (aktiv)
MQB auf K-CAN = 0 (aktiv)
MQB2020 auf K-CAN = ";
CM_ SG_ 2549088330 KN_TSG_FT_BusKnockOut "Ausgabe des BusKnockout-Status";
CM_ SG_ 2549088330 KN_TSG_FT_ECUKnockOut "Ausgabe des ECUKnockout-Status";
CM_ SG_ 2549088330 KN_TSG_FT_ECUKnockOutTimer "Ausgabe des ECUKnockOut-Timer";
CM_ SG_ 2549088330 NM_TSG_FS_Lokalaktiv "Zeigt an ob das SG nach Klemme15 AUS und nach entsprechender MAX Aktivzeit noch aktiv war";
CM_ SG_ 2549088330 NM_TSG_FS_Subsystemaktiv "Zeigt an ob ein Subsystem des SGs nach Klemme15 AUS und nach entsprechender MAX Aktivzeit noch aktiv war";
CM_ SG_ 2549088330 NM_TSG_FS_Wakeup "enthält die Weckursache; stehen mehrere Weckursachen parallel an, dann muss der kleinste Wert übertragen werden";
CM_ SG_ 2549088330 TSG_FS_Abschaltstufe "Funktionseinschränkung aufgrund aktiver Abschaltstufe";
CM_ SG_ 2549088330 TSG_FS_KD_Fehler "Status Kundendienstfehlerspeichereinträge
";
CM_ SG_ 2549088330 TSG_FS_KompSchutz "Funktionseinschränkung aufgrund Komponentenschutz aktiv";
CM_ SG_ 2549088330 TSG_FS_Nachlauftyp "Abgebildet wird die von der Hardware vorgegebene Möglichkeit, die Kommunikation nach Klemme 15 = AUS aufrecht zu erhalten. Es wird ein Init-Wert gesendet.
0 = Kommunikation nur bei KL15=EIN (kein Nachlauf, nicht weckfähig)
1 = Kommunikation nach KL15=AU";
CM_ SG_ 2549088330 TSG_FS_Transport_Mode "Funktionseinschränkung aufgrund aktivem Transport Mode und/oder Transport Schutz";
BA_DEF_REL_ BU_SG_REL_  "GenSigTimeoutTime" INT 0 65535;
BA_DEF_ BO_  "DiagRequest" ENUM "No", "Yes";
BA_DEF_ BO_  "DiagResponse" ENUM "No", "Yes";
BA_DEF_ BO_  "DiagState" ENUM "No", "Yes";
BA_DEF_ BO_  "GenMsgChkConstant" HEX 0 4095;
BA_DEF_ BO_  "GenMsgCycleTime" INT 0 65535;
BA_DEF_ BO_  "GenMsgCycleTimeFast" INT 0 65535;
BA_DEF_ BO_  "GenMsgDelayTime" INT 0 100000;
BA_DEF_ BO_  "GenMsgILSupport" ENUM "No", "Yes";
BA_DEF_ BO_  "GenMsgNrOfRepetition" INT 0 100;
BA_DEF_ BO_  "GenMsgPDUConstants" STRING;
BA_DEF_ BO_  "GenMsgSendType" ENUM "Cyclic", "not_used", "not_used", "not_used", "not_used", "not_used", "not_used", "IfActive", "NoMsgSendType";
BA_DEF_ BO_  "GenMsgStartDelayTime" INT 0 100000;
BA_DEF_ BO_  "NmMessage" ENUM "No", "Yes";
BA_DEF_ BO_  "NmhMessage" ENUM "No", "Yes";
BA_DEF_ BO_  "MsgType" ENUM "Application", "NM ", "NMH", "TP2.0", "ISO-TP ", "BAP", "EID", "KS", "XCP_PRE_CONFIGURED", "XCP_RUNTIME_CONFIGURED";
BA_DEF_ BO_  "VAGTP20_API" HEX 0 255;
BA_DEF_ BO_  "VAGTP20_DynConnection" ENUM "No", "Yes";
BA_DEF_ BO_  "VAGTP20_DynSetup" ENUM "No", "Yes";
BA_DEF_ BO_  "VAGTP20_StatConnection" ENUM "No", "Yes";
BA_DEF_ BO_  "CANFD_BRS" ENUM "0", "1";
BA_DEF_ BO_  "VFrameFormat" ENUM "StandardCAN", "ExtendedCAN", "reserved", "reserved", "reserved", "reserved", "reserved", "reserved", "reserved", "reserved", "reserved", "reserved", "reserved", "reserved", "StandardCAN_FD", "ExtendedCAN_FD";
BA_DEF_ SG_  "GenSigActiveRepetitions" INT -2147483648 2147483647;
BA_DEF_ SG_  "GenSigInactiveValue" INT -2147483648 2147483647;
BA_DEF_ SG_  "GenSigSendType" ENUM "Cyclic", "OnWrite", "OnWriteWithRepetition", "OnChange", "OnChangeWithRepetition", "IfActive", "IfActiveWithRepetition", "NoSigSendType", "OnChangeAndIfActive", "OnChangeAndIfActiveWithRepetition";
BA_DEF_ SG_  "GenSigStartValue" INT -2147483648 2147483647;
BA_DEF_ SG_  "NWM-WakeupAllowed" ENUM "No", "Yes";
BA_DEF_ SG_  "GenSigFuncType" ENUM "NoFunction", "MsgCounter", "CRC-8", "XOR", "XOR-2", "DatedBit", "SW-Kl15", "CHK", "Constant", "Protocol", "CRC-8-SAE_J1850", "CRC-32", "DataLength", "DataID", "MsgCounter16", "SOK-Signatur", "Cluster";
BA_DEF_ SG_  "GenSigSwitchedByIgnition" ENUM "No", "Yes";
BA_DEF_ SG_  "Fehlerwert" HEX 0 2147483647;
BA_DEF_ SG_  "GenSigMissingSourceValue" HEX 0 2147483647;
BA_DEF_DEF_REL_  "GenSigTimeoutTime" 0;
BA_DEF_DEF_  "DiagRequest" "No";
BA_DEF_DEF_  "DiagResponse" "No";
BA_DEF_DEF_  "DiagState" "No";
BA_DEF_DEF_  "GenMsgChkConstant" 0;
BA_DEF_DEF_  "GenMsgCycleTime" 0;
BA_DEF_DEF_  "GenMsgCycleTimeFast" 0;
BA_DEF_DEF_  "GenMsgDelayTime" 0;
BA_DEF_DEF_  "GenMsgILSupport" "No";
BA_DEF_DEF_  "GenMsgNrOfRepetition" 0;
BA_DEF_DEF_  "GenMsgPDUConstants" "";
BA_DEF_DEF_  "GenMsgSendType" "NoMsgSendType";
BA_DEF_DEF_  "GenMsgStartDelayTime" 0;
BA_DEF_DEF_  "NmMessage" "No";
BA_DEF_DEF_  "NmhMessage" "No";
BA_DEF_DEF_  "MsgType" "Application";
BA_DEF_DEF_  "VAGTP20_API" 0;
BA_DEF_DEF_  "VAGTP20_DynConnection" "No";
BA_DEF_DEF_  "VAGTP20_DynSetup" "No";
BA_DEF_DEF_  "VAGTP20_StatConnection" "No";
BA_DEF_DEF_  "CANFD_BRS" "1";
BA_DEF_DEF_  "VFrameFormat" "StandardCAN";
BA_DEF_DEF_  "GenSigActiveRepetitions" 0;
BA_DEF_DEF_  "GenSigInactiveValue" 0;
BA_DEF_DEF_  "GenSigSendType" "NoSigSendType";
BA_DEF_DEF_  "GenSigStartValue" 0;
BA_DEF_DEF_  "NWM-WakeupAllowed" "No";
BA_DEF_DEF_  "GenSigFuncType" "NoFunction";
BA_DEF_DEF_  "GenSigSwitchedByIgnition" "Yes";
BA_DEF_DEF_  "Fehlerwert" 0;
BA_DEF_DEF_  "GenSigMissingSourceValue" 0;
BA_ "GenMsgCycleTime" BO_ 1524 500;
BA_ "GenMsgDelayTime" BO_ 1524 50;
BA_ "GenMsgILSupport" BO_ 1524 1;
BA_ "GenMsgSendType" BO_ 1524 0;
BA_ "CANFD_BRS" BO_ 1524 0;
BA_ "VFrameFormat" BO_ 1524 14;
BA_ "GenMsgCycleTime" BO_ 2527679583 1000;
BA_ "GenMsgCycleTimeFast" BO_ 2527679583 100;
BA_ "GenMsgDelayTime" BO_ 2527679583 50;
BA_ "GenMsgILSupport" BO_ 2527679583 1;
BA_ "GenMsgNrOfRepetition" BO_ 2527679583 5;
BA_ "GenMsgPDUConstants" BO_ 2527679583 "0xc6,0x7f,0x85,0xb6,0xe6,0xae,0xf8,0x26,0xb0,0x8c,0x19,0x10,0x5b,0x33,0x64,0x6c";
BA_ "GenMsgSendType" BO_ 2527679583 0;
BA_ "CANFD_BRS" BO_ 2527679583 0;
BA_ "VFrameFormat" BO_ 2527679583 15;
BA_ "DiagRequest" BO_ 1806 1;
BA_ "MsgType" BO_ 1806 4;
BA_ "CANFD_BRS" BO_ 1806 0;
BA_ "VFrameFormat" BO_ 1806 14;
BA_ "DiagResponse" BO_ 1912 1;
BA_ "MsgType" BO_ 1912 4;
BA_ "CANFD_BRS" BO_ 1912 0;
BA_ "VFrameFormat" BO_ 1912 14;
BA_ "DiagState" BO_ 1792 1;
BA_ "MsgType" BO_ 1792 4;
BA_ "CANFD_BRS" BO_ 1792 0;
BA_ "VFrameFormat" BO_ 1792 14;
BA_ "DiagRequest" BO_ 1842 1;
BA_ "MsgType" BO_ 1842 4;
BA_ "CANFD_BRS" BO_ 1842 0;
BA_ "VFrameFormat" BO_ 1842 14;
BA_ "DiagResponse" BO_ 1948 1;
BA_ "MsgType" BO_ 1948 4;
BA_ "CANFD_BRS" BO_ 1948 0;
BA_ "VFrameFormat" BO_ 1948 14;
BA_ "DiagRequest" BO_ 1867 1;
BA_ "MsgType" BO_ 1867 4;
BA_ "CANFD_BRS" BO_ 1867 0;
BA_ "VFrameFormat" BO_ 1867 14;
BA_ "DiagResponse" BO_ 1973 1;
BA_ "MsgType" BO_ 1973 4;
BA_ "CANFD_BRS" BO_ 1973 0;
BA_ "VFrameFormat" BO_ 1973 14;
BA_ "DiagRequest" BO_ 1866 1;
BA_ "MsgType" BO_ 1866 4;
BA_ "CANFD_BRS" BO_ 1866 0;
BA_ "VFrameFormat" BO_ 1866 14;
BA_ "DiagResponse" BO_ 1972 1;
BA_ "MsgType" BO_ 1972 4;
BA_ "CANFD_BRS" BO_ 1972 0;
BA_ "VFrameFormat" BO_ 1972 14;
BA_ "DiagRequest" BO_ 1855 1;
BA_ "MsgType" BO_ 1855 4;
BA_ "CANFD_BRS" BO_ 1855 0;
BA_ "VFrameFormat" BO_ 1855 14;
BA_ "DiagResponse" BO_ 1961 1;
BA_ "MsgType" BO_ 1961 4;
BA_ "CANFD_BRS" BO_ 1961 0;
BA_ "VFrameFormat" BO_ 1961 14;
BA_ "DiagRequest" BO_ 1854 1;
BA_ "MsgType" BO_ 1854 4;
BA_ "CANFD_BRS" BO_ 1854 0;
BA_ "VFrameFormat" BO_ 1854 14;
BA_ "DiagResponse" BO_ 1960 1;
BA_ "MsgType" BO_ 1960 4;
BA_ "CANFD_BRS" BO_ 1960 0;
BA_ "VFrameFormat" BO_ 1960 14;
BA_ "DiagRequest" BO_ 2621440014 1;
BA_ "MsgType" BO_ 2621440014 4;
BA_ "CANFD_BRS" BO_ 2621440014 0;
BA_ "VFrameFormat" BO_ 2621440014 15;
BA_ "DiagResponse" BO_ 2621571086 1;
BA_ "MsgType" BO_ 2621571086 4;
BA_ "CANFD_BRS" BO_ 2621571086 0;
BA_ "VFrameFormat" BO_ 2621571086 15;
BA_ "DiagRequest" BO_ 2549874874 1;
BA_ "MsgType" BO_ 2549874874 4;
BA_ "CANFD_BRS" BO_ 2549874874 0;
BA_ "VFrameFormat" BO_ 2549874874 15;
BA_ "DiagResponse" BO_ 2550005946 1;
BA_ "MsgType" BO_ 2550005946 4;
BA_ "CANFD_BRS" BO_ 2550005946 0;
BA_ "VFrameFormat" BO_ 2550005946 15;
BA_ "DiagState" BO_ 2621505536 1;
BA_ "MsgType" BO_ 2621505536 4;
BA_ "CANFD_BRS" BO_ 2621505536 0;
BA_ "VFrameFormat" BO_ 2621505536 15;
BA_ "DiagRequest" BO_ 2549874838 1;
BA_ "MsgType" BO_ 2549874838 4;
BA_ "CANFD_BRS" BO_ 2549874838 0;
BA_ "VFrameFormat" BO_ 2549874838 15;
BA_ "DiagResponse" BO_ 2550005910 1;
BA_ "MsgType" BO_ 2550005910 4;
BA_ "CANFD_BRS" BO_ 2550005910 0;
BA_ "VFrameFormat" BO_ 2550005910 15;
BA_ "DiagRequest" BO_ 2549874839 1;
BA_ "MsgType" BO_ 2549874839 4;
BA_ "CANFD_BRS" BO_ 2549874839 0;
BA_ "VFrameFormat" BO_ 2549874839 15;
BA_ "DiagResponse" BO_ 2550005911 1;
BA_ "MsgType" BO_ 2550005911 4;
BA_ "CANFD_BRS" BO_ 2550005911 0;
BA_ "VFrameFormat" BO_ 2550005911 15;
BA_ "DiagRequest" BO_ 2550398979 1;
BA_ "MsgType" BO_ 2550398979 4;
BA_ "CANFD_BRS" BO_ 2550398979 0;
BA_ "VFrameFormat" BO_ 2550398979 15;
BA_ "DiagRequest" BO_ 2621702147 1;
BA_ "MsgType" BO_ 2621702147 4;
BA_ "CANFD_BRS" BO_ 2621702147 0;
BA_ "VFrameFormat" BO_ 2621702147 15;
BA_ "DiagResponse" BO_ 2550530051 1;
BA_ "MsgType" BO_ 2550530051 4;
BA_ "CANFD_BRS" BO_ 2550530051 0;
BA_ "VFrameFormat" BO_ 2550530051 15;
BA_ "DiagResponse" BO_ 2621833219 1;
BA_ "MsgType" BO_ 2621833219 4;
BA_ "CANFD_BRS" BO_ 2621833219 0;
BA_ "VFrameFormat" BO_ 2621833219 15;
BA_ "DiagRequest" BO_ 2550398980 1;
BA_ "MsgType" BO_ 2550398980 4;
BA_ "CANFD_BRS" BO_ 2550398980 0;
BA_ "VFrameFormat" BO_ 2550398980 15;
BA_ "DiagRequest" BO_ 2621702148 1;
BA_ "MsgType" BO_ 2621702148 4;
BA_ "CANFD_BRS" BO_ 2621702148 0;
BA_ "VFrameFormat" BO_ 2621702148 15;
BA_ "DiagResponse" BO_ 2550530052 1;
BA_ "MsgType" BO_ 2550530052 4;
BA_ "CANFD_BRS" BO_ 2550530052 0;
BA_ "VFrameFormat" BO_ 2550530052 15;
BA_ "DiagResponse" BO_ 2621833220 1;
BA_ "MsgType" BO_ 2621833220 4;
BA_ "CANFD_BRS" BO_ 2621833220 0;
BA_ "VFrameFormat" BO_ 2621833220 15;
BA_ "DiagRequest" BO_ 2550399029 1;
BA_ "MsgType" BO_ 2550399029 4;
BA_ "CANFD_BRS" BO_ 2550399029 0;
BA_ "VFrameFormat" BO_ 2550399029 15;
BA_ "DiagRequest" BO_ 2621702197 1;
BA_ "MsgType" BO_ 2621702197 4;
BA_ "CANFD_BRS" BO_ 2621702197 0;
BA_ "VFrameFormat" BO_ 2621702197 15;
BA_ "DiagResponse" BO_ 2550530101 1;
BA_ "MsgType" BO_ 2550530101 4;
BA_ "CANFD_BRS" BO_ 2550530101 0;
BA_ "VFrameFormat" BO_ 2550530101 15;
BA_ "DiagResponse" BO_ 2621833269 1;
BA_ "MsgType" BO_ 2621833269 4;
BA_ "CANFD_BRS" BO_ 2621833269 0;
BA_ "VFrameFormat" BO_ 2621833269 15;
BA_ "DiagRequest" BO_ 2550399030 1;
BA_ "MsgType" BO_ 2550399030 4;
BA_ "CANFD_BRS" BO_ 2550399030 0;
BA_ "VFrameFormat" BO_ 2550399030 15;
BA_ "DiagRequest" BO_ 2621702198 1;
BA_ "MsgType" BO_ 2621702198 4;
BA_ "CANFD_BRS" BO_ 2621702198 0;
BA_ "VFrameFormat" BO_ 2621702198 15;
BA_ "DiagResponse" BO_ 2550530102 1;
BA_ "MsgType" BO_ 2550530102 4;
BA_ "CANFD_BRS" BO_ 2550530102 0;
BA_ "VFrameFormat" BO_ 2550530102 15;
BA_ "DiagResponse" BO_ 2621833270 1;
BA_ "MsgType" BO_ 2621833270 4;
BA_ "CANFD_BRS" BO_ 2621833270 0;
BA_ "VFrameFormat" BO_ 2621833270 15;
BA_ "DiagRequest" BO_ 2550399031 1;
BA_ "MsgType" BO_ 2550399031 4;
BA_ "CANFD_BRS" BO_ 2550399031 0;
BA_ "VFrameFormat" BO_ 2550399031 15;
BA_ "DiagRequest" BO_ 2621702199 1;
BA_ "MsgType" BO_ 2621702199 4;
BA_ "CANFD_BRS" BO_ 2621702199 0;
BA_ "VFrameFormat" BO_ 2621702199 15;
BA_ "DiagResponse" BO_ 2550530103 1;
BA_ "MsgType" BO_ 2550530103 4;
BA_ "CANFD_BRS" BO_ 2550530103 0;
BA_ "VFrameFormat" BO_ 2550530103 15;
BA_ "DiagResponse" BO_ 2621833271 1;
BA_ "MsgType" BO_ 2621833271 4;
BA_ "CANFD_BRS" BO_ 2621833271 0;
BA_ "VFrameFormat" BO_ 2621833271 15;
BA_ "DiagRequest" BO_ 2550398981 1;
BA_ "MsgType" BO_ 2550398981 4;
BA_ "CANFD_BRS" BO_ 2550398981 0;
BA_ "VFrameFormat" BO_ 2550398981 15;
BA_ "DiagRequest" BO_ 2621702149 1;
BA_ "MsgType" BO_ 2621702149 4;
BA_ "CANFD_BRS" BO_ 2621702149 0;
BA_ "VFrameFormat" BO_ 2621702149 15;
BA_ "DiagResponse" BO_ 2550530053 1;
BA_ "MsgType" BO_ 2550530053 4;
BA_ "CANFD_BRS" BO_ 2550530053 0;
BA_ "VFrameFormat" BO_ 2550530053 15;
BA_ "DiagResponse" BO_ 2621833221 1;
BA_ "MsgType" BO_ 2621833221 4;
BA_ "CANFD_BRS" BO_ 2621833221 0;
BA_ "VFrameFormat" BO_ 2621833221 15;
BA_ "DiagRequest" BO_ 2550398977 1;
BA_ "MsgType" BO_ 2550398977 4;
BA_ "CANFD_BRS" BO_ 2550398977 0;
BA_ "VFrameFormat" BO_ 2550398977 15;
BA_ "DiagRequest" BO_ 2621702145 1;
BA_ "MsgType" BO_ 2621702145 4;
BA_ "CANFD_BRS" BO_ 2621702145 0;
BA_ "VFrameFormat" BO_ 2621702145 15;
BA_ "DiagResponse" BO_ 2550530049 1;
BA_ "MsgType" BO_ 2550530049 4;
BA_ "CANFD_BRS" BO_ 2550530049 0;
BA_ "VFrameFormat" BO_ 2550530049 15;
BA_ "DiagResponse" BO_ 2621833217 1;
BA_ "MsgType" BO_ 2621833217 4;
BA_ "CANFD_BRS" BO_ 2621833217 0;
BA_ "VFrameFormat" BO_ 2621833217 15;
BA_ "DiagRequest" BO_ 2550398978 1;
BA_ "MsgType" BO_ 2550398978 4;
BA_ "CANFD_BRS" BO_ 2550398978 0;
BA_ "VFrameFormat" BO_ 2550398978 15;
BA_ "DiagRequest" BO_ 2621702146 1;
BA_ "MsgType" BO_ 2621702146 4;
BA_ "CANFD_BRS" BO_ 2621702146 0;
BA_ "VFrameFormat" BO_ 2621702146 15;
BA_ "DiagResponse" BO_ 2550530050 1;
BA_ "MsgType" BO_ 2550530050 4;
BA_ "CANFD_BRS" BO_ 2550530050 0;
BA_ "VFrameFormat" BO_ 2550530050 15;
BA_ "DiagResponse" BO_ 2621833218 1;
BA_ "MsgType" BO_ 2621833218 4;
BA_ "CANFD_BRS" BO_ 2621833218 0;
BA_ "VFrameFormat" BO_ 2621833218 15;
BA_ "DiagRequest" BO_ 2621440075 1;
BA_ "MsgType" BO_ 2621440075 4;
BA_ "CANFD_BRS" BO_ 2621440075 0;
BA_ "VFrameFormat" BO_ 2621440075 15;
BA_ "DiagResponse" BO_ 2621571147 1;
BA_ "MsgType" BO_ 2621571147 4;
BA_ "CANFD_BRS" BO_ 2621571147 0;
BA_ "VFrameFormat" BO_ 2621571147 15;
BA_ "DiagRequest" BO_ 2621440074 1;
BA_ "MsgType" BO_ 2621440074 4;
BA_ "CANFD_BRS" BO_ 2621440074 0;
BA_ "VFrameFormat" BO_ 2621440074 15;
BA_ "DiagResponse" BO_ 2621571146 1;
BA_ "MsgType" BO_ 2621571146 4;
BA_ "CANFD_BRS" BO_ 2621571146 0;
BA_ "VFrameFormat" BO_ 2621571146 15;
BA_ "DiagRequest" BO_ 2621440063 1;
BA_ "MsgType" BO_ 2621440063 4;
BA_ "CANFD_BRS" BO_ 2621440063 0;
BA_ "VFrameFormat" BO_ 2621440063 15;
BA_ "DiagResponse" BO_ 2621571135 1;
BA_ "MsgType" BO_ 2621571135 4;
BA_ "CANFD_BRS" BO_ 2621571135 0;
BA_ "VFrameFormat" BO_ 2621571135 15;
BA_ "DiagRequest" BO_ 2621440062 1;
BA_ "MsgType" BO_ 2621440062 4;
BA_ "CANFD_BRS" BO_ 2621440062 0;
BA_ "VFrameFormat" BO_ 2621440062 15;
BA_ "DiagResponse" BO_ 2621571134 1;
BA_ "MsgType" BO_ 2621571134 4;
BA_ "CANFD_BRS" BO_ 2621571134 0;
BA_ "VFrameFormat" BO_ 2621571134 15;
BA_ "DiagRequest" BO_ 2549874853 1;
BA_ "MsgType" BO_ 2549874853 4;
BA_ "CANFD_BRS" BO_ 2549874853 0;
BA_ "VFrameFormat" BO_ 2549874853 15;
BA_ "DiagRequest" BO_ 2621440165 1;
BA_ "MsgType" BO_ 2621440165 4;
BA_ "CANFD_BRS" BO_ 2621440165 0;
BA_ "VFrameFormat" BO_ 2621440165 15;
BA_ "DiagResponse" BO_ 2550005925 1;
BA_ "MsgType" BO_ 2550005925 4;
BA_ "CANFD_BRS" BO_ 2550005925 0;
BA_ "VFrameFormat" BO_ 2550005925 15;
BA_ "DiagResponse" BO_ 2621571237 1;
BA_ "MsgType" BO_ 2621571237 4;
BA_ "CANFD_BRS" BO_ 2621571237 0;
BA_ "VFrameFormat" BO_ 2621571237 15;
BA_ "GenMsgCycleTimeFast" BO_ 1425 200;
BA_ "GenMsgDelayTime" BO_ 1425 20;
BA_ "GenMsgILSupport" BO_ 1425 1;
BA_ "GenMsgNrOfRepetition" BO_ 1425 5;
BA_ "GenMsgSendType" BO_ 1425 7;
BA_ "CANFD_BRS" BO_ 1425 0;
BA_ "VFrameFormat" BO_ 1425 14;
BA_ "GenMsgCycleTime" BO_ 1426 200;
BA_ "GenMsgDelayTime" BO_ 1426 20;
BA_ "GenMsgILSupport" BO_ 1426 1;
BA_ "GenMsgSendType" BO_ 1426 0;
BA_ "CANFD_BRS" BO_ 1426 0;
BA_ "VFrameFormat" BO_ 1426 14;
BA_ "GenMsgChkConstant" BO_ 960 195;
BA_ "GenMsgCycleTime" BO_ 960 100;
BA_ "GenMsgDelayTime" BO_ 960 10;
BA_ "GenMsgILSupport" BO_ 960 1;
BA_ "GenMsgPDUConstants" BO_ 960 "0xc3,0xc3,0xc3,0xc3,0xc3,0xc3,0xc3,0xc3,0xc3,0xc3,0xc3,0xc3,0xc3,0xc3,0xc3,0xc3";
BA_ "GenMsgSendType" BO_ 960 0;
BA_ "CANFD_BRS" BO_ 960 0;
BA_ "VFrameFormat" BO_ 960 14;
BA_ "GenMsgCycleTime" BO_ 2463978753 1000;
BA_ "GenMsgCycleTimeFast" BO_ 2463978753 100;
BA_ "GenMsgDelayTime" BO_ 2463978753 10;
BA_ "GenMsgILSupport" BO_ 2463978753 1;
BA_ "GenMsgNrOfRepetition" BO_ 2463978753 5;
BA_ "GenMsgPDUConstants" BO_ 2463978753 "0x80,0xf1,0xa5,0xaf,0x94,0x59,0xe8,0x8c,0x03,0xd4,0xf5,0x5e,0xec,0x73,0x81,0x50";
BA_ "GenMsgSendType" BO_ 2463978753 0;
BA_ "CANFD_BRS" BO_ 2463978753 0;
BA_ "VFrameFormat" BO_ 2463978753 15;
BA_ "GenMsgCycleTime" BO_ 1420 1000;
BA_ "GenMsgCycleTimeFast" BO_ 1420 20;
BA_ "GenMsgDelayTime" BO_ 1420 10;
BA_ "GenMsgILSupport" BO_ 1420 1;
BA_ "GenMsgNrOfRepetition" BO_ 1420 5;
BA_ "GenMsgPDUConstants" BO_ 1420 "0x9b,0xb5,0x9d,0x06,0x01,0xe7,0x8f,0xc1,0xd0,0x10,0x47,0xe9,0xd3,0xca,0x05,0xf0";
BA_ "GenMsgSendType" BO_ 1420 0;
BA_ "CANFD_BRS" BO_ 1420 0;
BA_ "VFrameFormat" BO_ 1420 14;
BA_ "GenMsgCycleTime" BO_ 1646 2000;
BA_ "GenMsgDelayTime" BO_ 1646 200;
BA_ "GenMsgILSupport" BO_ 1646 1;
BA_ "GenMsgSendType" BO_ 1646 0;
BA_ "CANFD_BRS" BO_ 1646 0;
BA_ "VFrameFormat" BO_ 1646 14;
BA_ "GenMsgCycleTime" BO_ 1640 200;
BA_ "GenMsgCycleTimeFast" BO_ 1640 100;
BA_ "GenMsgDelayTime" BO_ 1640 50;
BA_ "GenMsgILSupport" BO_ 1640 1;
BA_ "GenMsgNrOfRepetition" BO_ 1640 5;
BA_ "GenMsgSendType" BO_ 1640 0;
BA_ "CANFD_BRS" BO_ 1640 0;
BA_ "VFrameFormat" BO_ 1640 14;
BA_ "GenMsgCycleTime" BO_ 2527679635 2000;
BA_ "GenMsgDelayTime" BO_ 2527679635 200;
BA_ "GenMsgILSupport" BO_ 2527679635 1;
BA_ "GenMsgSendType" BO_ 2527679635 0;
BA_ "CANFD_BRS" BO_ 2527679635 0;
BA_ "VFrameFormat" BO_ 2527679635 15;
BA_ "GenMsgCycleTime" BO_ 1712 500;
BA_ "GenMsgILSupport" BO_ 1712 1;
BA_ "GenMsgSendType" BO_ 1712 0;
BA_ "CANFD_BRS" BO_ 1712 0;
BA_ "VFrameFormat" BO_ 1712 14;
BA_ "GenMsgCycleTime" BO_ 1505 200;
BA_ "GenMsgILSupport" BO_ 1505 1;
BA_ "GenMsgSendType" BO_ 1505 0;
BA_ "CANFD_BRS" BO_ 1505 0;
BA_ "VFrameFormat" BO_ 1505 14;
BA_ "GenMsgCycleTime" BO_ 605 60;
BA_ "GenMsgILSupport" BO_ 605 1;
BA_ "GenMsgPDUConstants" BO_ 605 "0xda,0x6b,0x0e,0xb2,0x78,0xbd,0x5a,0x81,0x7b,0xd6,0x41,0x39,0x76,0xb6,0xd7,0x35";
BA_ "GenMsgSendType" BO_ 605 0;
BA_ "CANFD_BRS" BO_ 605 0;
BA_ "VFrameFormat" BO_ 605 14;
BA_ "GenMsgCycleTime" BO_ 2549088270 500;
BA_ "GenMsgILSupport" BO_ 2549088270 1;
BA_ "GenMsgSendType" BO_ 2549088270 0;
BA_ "CANFD_BRS" BO_ 2549088270 0;
BA_ "VFrameFormat" BO_ 2549088270 15;
BA_ "GenMsgCycleTime" BO_ 2549088272 500;
BA_ "GenMsgILSupport" BO_ 2549088272 1;
BA_ "GenMsgSendType" BO_ 2549088272 0;
BA_ "CANFD_BRS" BO_ 2549088272 0;
BA_ "VFrameFormat" BO_ 2549088272 15;
BA_ "GenMsgCycleTime" BO_ 2549088331 500;
BA_ "GenMsgILSupport" BO_ 2549088331 1;
BA_ "GenMsgSendType" BO_ 2549088331 0;
BA_ "CANFD_BRS" BO_ 2549088331 0;
BA_ "VFrameFormat" BO_ 2549088331 15;
BA_ "GenMsgCycleTime" BO_ 2549088330 500;
BA_ "GenMsgILSupport" BO_ 2549088330 1;
BA_ "GenMsgSendType" BO_ 2549088330 0;
BA_ "CANFD_BRS" BO_ 2549088330 0;
BA_ "VFrameFormat" BO_ 2549088330 15;
BA_ "GenSigSendType" SG_ 1524 AMB_Charisma_FahrPr 3;
BA_ "GenSigSwitchedByIgnition" SG_ 1524 AMB_Charisma_FahrPr 0;
BA_ "GenSigSendType" SG_ 1524 AMB_Charisma_Status 3;
BA_ "GenSigSwitchedByIgnition" SG_ 1524 AMB_Charisma_Status 0;
BA_ "GenSigSendType" SG_ 1524 BCM1_DI_Rampe_Innenlicht 3;
BA_ "GenSigSwitchedByIgnition" SG_ 1524 BCM1_DI_Rampe_Innenlicht 0;
BA_ "GenSigSendType" SG_ 1524 BCM1_DI_Rampe_Leselicht 3;
BA_ "GenSigSwitchedByIgnition" SG_ 1524 BCM1_DI_Rampe_Leselicht 0;
BA_ "GenSigSendType" SG_ 1524 BCM1_Innenlicht_gedimmt_H 3;
BA_ "GenSigSwitchedByIgnition" SG_ 1524 BCM1_Innenlicht_gedimmt_H 0;
BA_ "GenSigSendType" SG_ 1524 BCM1_Innenlicht_gedimmt_V 3;
BA_ "GenSigSwitchedByIgnition" SG_ 1524 BCM1_Innenlicht_gedimmt_V 0;
BA_ "GenSigSendType" SG_ 1524 BCM1_Innenlicht_H 3;
BA_ "GenSigSwitchedByIgnition" SG_ 1524 BCM1_Innenlicht_H 0;
BA_ "GenSigSendType" SG_ 1524 BCM1_Innenlicht_V 3;
BA_ "GenSigSwitchedByIgnition" SG_ 1524 BCM1_Innenlicht_V 0;
BA_ "GenSigSendType" SG_ 1524 BCM1_Leselicht_Anf_hl 3;
BA_ "GenSigSwitchedByIgnition" SG_ 1524 BCM1_Leselicht_Anf_hl 0;
BA_ "GenSigSendType" SG_ 1524 BCM1_Leselicht_Anf_hr 3;
BA_ "GenSigSwitchedByIgnition" SG_ 1524 BCM1_Leselicht_Anf_hr 0;
BA_ "GenSigSendType" SG_ 1524 BCM1_Leselicht_Anf_vl 3;
BA_ "GenSigSwitchedByIgnition" SG_ 1524 BCM1_Leselicht_Anf_vl 0;
BA_ "GenSigSendType" SG_ 1524 BCM1_Leselicht_Anf_vr 3;
BA_ "GenSigSwitchedByIgnition" SG_ 1524 BCM1_Leselicht_Anf_vr 0;
BA_ "GenSigSendType" SG_ 1524 BCM1_Leuchten_Aus 3;
BA_ "GenSigSwitchedByIgnition" SG_ 1524 BCM1_Leuchten_Aus 0;
BA_ "GenSigSendType" SG_ 1524 IL_Bel_BFS_Ausstieg 3;
BA_ "GenSigSwitchedByIgnition" SG_ 1524 IL_Bel_BFS_Ausstieg 0;
BA_ "GenSigSendType" SG_ 1524 IL_Bel_FS_Ausstieg 3;
BA_ "GenSigSwitchedByIgnition" SG_ 1524 IL_Bel_FS_Ausstieg 0;
BA_ "GenSigSendType" SG_ 1524 IL_Bel_HBFS_Ausstieg 3;
BA_ "GenSigSwitchedByIgnition" SG_ 1524 IL_Bel_HBFS_Ausstieg 0;
BA_ "GenSigSendType" SG_ 1524 IL_Bel_HFS_Ausstieg 3;
BA_ "GenSigSwitchedByIgnition" SG_ 1524 IL_Bel_HFS_Ausstieg 0;
BA_ "GenSigSendType" SG_ 1524 IL_Dimmung_H_Tuerkontur 3;
BA_ "GenSigSwitchedByIgnition" SG_ 1524 IL_Dimmung_H_Tuerkontur 0;
BA_ "GenSigSendType" SG_ 1524 IL_Dimmung_Lautspr 3;
BA_ "GenSigSwitchedByIgnition" SG_ 1524 IL_Dimmung_Lautspr 0;
BA_ "GenSigSendType" SG_ 1524 IL_Dimmung_Tuerinnengriff 3;
BA_ "GenSigSwitchedByIgnition" SG_ 1524 IL_Dimmung_Tuerinnengriff 0;
BA_ "GenSigSendType" SG_ 1524 IL_Dimmung_Umfeldbel 3;
BA_ "GenSigSwitchedByIgnition" SG_ 1524 IL_Dimmung_Umfeldbel 0;
BA_ "GenSigSendType" SG_ 1524 IL_Dimmung_V_Tuerkontur 3;
BA_ "GenSigSwitchedByIgnition" SG_ 1524 IL_Dimmung_V_Tuerkontur 0;
BA_ "GenSigSendType" SG_ 1524 IL_Innenlicht_aktiv 3;
BA_ "GenSigSwitchedByIgnition" SG_ 1524 IL_Innenlicht_aktiv 0;
BA_ "GenSigSendType" SG_ 1524 IL_Klemme_30G_aktiv 3;
BA_ "GenSigSwitchedByIgnition" SG_ 1524 IL_Klemme_30G_aktiv 0;
BA_ "GenSigSendType" SG_ 2527679583 IPA_02_BZ 0;
BA_ "GenSigFuncType" SG_ 2527679583 IPA_02_BZ 1;
BA_ "GenSigSwitchedByIgnition" SG_ 2527679583 IPA_02_BZ 0;
BA_ "GenSigSendType" SG_ 2527679583 IPA_02_CRC 0;
BA_ "GenSigFuncType" SG_ 2527679583 IPA_02_CRC 2;
BA_ "GenSigSwitchedByIgnition" SG_ 2527679583 IPA_02_CRC 0;
BA_ "GenSigActiveRepetitions" SG_ 2527679583 IPA_Akustik_PL_gefunden 5;
BA_ "GenSigSendType" SG_ 2527679583 IPA_Akustik_PL_gefunden 4;
BA_ "GenSigActiveRepetitions" SG_ 2527679583 IPA_Anf_Meldungen 5;
BA_ "GenSigSendType" SG_ 2527679583 IPA_Anf_Meldungen 4;
BA_ "GenSigSwitchedByIgnition" SG_ 2527679583 IPA_Anf_Meldungen 0;
BA_ "GenSigActiveRepetitions" SG_ 2527679583 IPA_PL_Anzeige_links 5;
BA_ "GenSigSendType" SG_ 2527679583 IPA_PL_Anzeige_links 4;
BA_ "GenSigActiveRepetitions" SG_ 2527679583 IPA_PL_Anzeige_rechts 5;
BA_ "GenSigSendType" SG_ 2527679583 IPA_PL_Anzeige_rechts 4;
BA_ "GenSigActiveRepetitions" SG_ 2527679583 Parken_aktives_System_02 5;
BA_ "GenSigSendType" SG_ 2527679583 Parken_aktives_System_02 4;
BA_ "GenSigSwitchedByIgnition" SG_ 2527679583 Parken_aktives_System_02 0;
BA_ "GenSigActiveRepetitions" SG_ 2527679583 Parken_Aktivierungslicht_Anf 5;
BA_ "GenSigSendType" SG_ 2527679583 Parken_Aktivierungslicht_Anf 4;
BA_ "GenSigSwitchedByIgnition" SG_ 2527679583 Parken_Aktivierungslicht_Anf 0;
BA_ "GenSigActiveRepetitions" SG_ 2527679583 Parken_Bestaetigungsblinken_Anf 5;
BA_ "GenSigSendType" SG_ 2527679583 Parken_Bestaetigungsblinken_Anf 4;
BA_ "GenSigSwitchedByIgnition" SG_ 2527679583 Parken_Bestaetigungsblinken_Anf 0;
BA_ "GenSigActiveRepetitions" SG_ 2527679583 Parken_Blinker_li_Anf 5;
BA_ "GenSigSendType" SG_ 2527679583 Parken_Blinker_li_Anf 4;
BA_ "GenSigSwitchedByIgnition" SG_ 2527679583 Parken_Blinker_li_Anf 0;
BA_ "GenSigActiveRepetitions" SG_ 2527679583 Parken_Blinker_re_Anf 5;
BA_ "GenSigSendType" SG_ 2527679583 Parken_Blinker_re_Anf 4;
BA_ "GenSigSwitchedByIgnition" SG_ 2527679583 Parken_Blinker_re_Anf 0;
BA_ "GenSigActiveRepetitions" SG_ 2527679583 Parken_Fahrbereitschaftlicht_Anf 5;
BA_ "GenSigSendType" SG_ 2527679583 Parken_Fahrbereitschaftlicht_Anf 4;
BA_ "GenSigActiveRepetitions" SG_ 2527679583 Parken_Fahrerhinweise_Anf 5;
BA_ "GenSigSendType" SG_ 2527679583 Parken_Fahrerhinweise_Anf 4;
BA_ "GenSigSwitchedByIgnition" SG_ 2527679583 Parken_Fahrerhinweise_Anf 0;
BA_ "GenSigActiveRepetitions" SG_ 2527679583 Parken_Fahrtrichtungslicht_Anf 5;
BA_ "GenSigSendType" SG_ 2527679583 Parken_Fahrtrichtungslicht_Anf 4;
BA_ "GenSigActiveRepetitions" SG_ 2527679583 Parken_FFB_LED_Anf 5;
BA_ "GenSigSendType" SG_ 2527679583 Parken_FFB_LED_Anf 4;
BA_ "GenSigActiveRepetitions" SG_ 2527679583 Parken_Lichtnachlauf_Anf 5;
BA_ "GenSigSendType" SG_ 2527679583 Parken_Lichtnachlauf_Anf 4;
BA_ "GenSigActiveRepetitions" SG_ 2527679583 Parken_Lichtsteuerung_Anf 5;
BA_ "GenSigSendType" SG_ 2527679583 Parken_Lichtsteuerung_Anf 4;
BA_ "GenSigSwitchedByIgnition" SG_ 2527679583 Parken_Lichtsteuerung_Anf 0;
BA_ "GenSigActiveRepetitions" SG_ 2527679583 Parken_Schluesselsuche_Anf 5;
BA_ "GenSigSendType" SG_ 2527679583 Parken_Schluesselsuche_Anf 4;
BA_ "GenSigActiveRepetitions" SG_ 2527679583 Parken_Seitenspiegel_Anf 5;
BA_ "GenSigSendType" SG_ 2527679583 Parken_Seitenspiegel_Anf 4;
BA_ "GenSigActiveRepetitions" SG_ 2527679583 Parken_Wegfahrsperren_Anf 5;
BA_ "GenSigSendType" SG_ 2527679583 Parken_Wegfahrsperren_Anf 4;
BA_ "GenSigActiveRepetitions" SG_ 2527679583 Parken_ZR_Sondermodus_Anf 5;
BA_ "GenSigSendType" SG_ 2527679583 Parken_ZR_Sondermodus_Anf 4;
BA_ "GenSigSwitchedByIgnition" SG_ 2527679583 Parken_ZR_Sondermodus_Anf 0;
BA_ "GenSigActiveRepetitions" SG_ 2527679583 Parken_ZV_Schliessen 5;
BA_ "GenSigSendType" SG_ 2527679583 Parken_ZV_Schliessen 4;
BA_ "GenSigSendType" SG_ 1806 ISO_BCM1_Req_Data 3;
BA_ "GenSigFuncType" SG_ 1806 ISO_BCM1_Req_Data 9;
BA_ "GenSigSwitchedByIgnition" SG_ 1806 ISO_BCM1_Req_Data 0;
BA_ "GenSigSendType" SG_ 1912 ISO_BCM1_Resp_Data 3;
BA_ "GenSigFuncType" SG_ 1912 ISO_BCM1_Resp_Data 9;
BA_ "GenSigSwitchedByIgnition" SG_ 1912 ISO_BCM1_Resp_Data 0;
BA_ "GenSigSendType" SG_ 1792 ISO_ALL_01_Req_Data 3;
BA_ "GenSigFuncType" SG_ 1792 ISO_ALL_01_Req_Data 9;
BA_ "GenSigSwitchedByIgnition" SG_ 1792 ISO_ALL_01_Req_Data 0;
BA_ "GenSigSendType" SG_ 1842 ISO_Kessy_Req_Data 3;
BA_ "GenSigFuncType" SG_ 1842 ISO_Kessy_Req_Data 9;
BA_ "GenSigSwitchedByIgnition" SG_ 1842 ISO_Kessy_Req_Data 0;
BA_ "GenSigSendType" SG_ 1948 ISO_Kessy_Resp_Data 3;
BA_ "GenSigFuncType" SG_ 1948 ISO_Kessy_Resp_Data 9;
BA_ "GenSigSwitchedByIgnition" SG_ 1948 ISO_Kessy_Resp_Data 0;
BA_ "GenSigSendType" SG_ 1867 ISO_TSG_BT_Req_Data 3;
BA_ "GenSigFuncType" SG_ 1867 ISO_TSG_BT_Req_Data 9;
BA_ "GenSigSwitchedByIgnition" SG_ 1867 ISO_TSG_BT_Req_Data 0;
BA_ "GenSigSendType" SG_ 1973 ISO_TSG_BT_Resp_Data 3;
BA_ "GenSigFuncType" SG_ 1973 ISO_TSG_BT_Resp_Data 9;
BA_ "GenSigSwitchedByIgnition" SG_ 1973 ISO_TSG_BT_Resp_Data 0;
BA_ "GenSigSendType" SG_ 1866 ISO_TSG_FT_Req_Data 3;
BA_ "GenSigFuncType" SG_ 1866 ISO_TSG_FT_Req_Data 9;
BA_ "GenSigSwitchedByIgnition" SG_ 1866 ISO_TSG_FT_Req_Data 0;
BA_ "GenSigSendType" SG_ 1972 ISO_TSG_FT_Resp_Data 3;
BA_ "GenSigFuncType" SG_ 1972 ISO_TSG_FT_Resp_Data 9;
BA_ "GenSigSwitchedByIgnition" SG_ 1972 ISO_TSG_FT_Resp_Data 0;
BA_ "GenSigSendType" SG_ 1855 ISO_TSG_HBFS_Req_Data 3;
BA_ "GenSigFuncType" SG_ 1855 ISO_TSG_HBFS_Req_Data 9;
BA_ "GenSigSwitchedByIgnition" SG_ 1855 ISO_TSG_HBFS_Req_Data 0;
BA_ "GenSigSendType" SG_ 1961 ISO_TSG_HBFS_Resp_Data 3;
BA_ "GenSigFuncType" SG_ 1961 ISO_TSG_HBFS_Resp_Data 9;
BA_ "GenSigSwitchedByIgnition" SG_ 1961 ISO_TSG_HBFS_Resp_Data 0;
BA_ "GenSigSendType" SG_ 1854 ISO_TSG_HFS_Req_Data 3;
BA_ "GenSigFuncType" SG_ 1854 ISO_TSG_HFS_Req_Data 9;
BA_ "GenSigSwitchedByIgnition" SG_ 1854 ISO_TSG_HFS_Req_Data 0;
BA_ "GenSigSendType" SG_ 1960 ISO_TSG_HFS_Resp_Data 3;
BA_ "GenSigFuncType" SG_ 1960 ISO_TSG_HFS_Resp_Data 9;
BA_ "GenSigSwitchedByIgnition" SG_ 1960 ISO_TSG_HFS_Resp_Data 0;
BA_ "GenSigSendType" SG_ 2621440014 ISOx_BCM1_Req_FD_Data 3;
BA_ "GenSigFuncType" SG_ 2621440014 ISOx_BCM1_Req_FD_Data 9;
BA_ "GenSigSwitchedByIgnition" SG_ 2621440014 ISOx_BCM1_Req_FD_Data 0;
BA_ "GenSigSendType" SG_ 2621571086 ISOx_BCM1_Resp_FD_Data 3;
BA_ "GenSigFuncType" SG_ 2621571086 ISOx_BCM1_Resp_FD_Data 9;
BA_ "GenSigSwitchedByIgnition" SG_ 2621571086 ISOx_BCM1_Resp_FD_Data 0;
BA_ "GenSigSendType" SG_ 2549874874 ISOx_DDA_Req_Data 3;
BA_ "GenSigFuncType" SG_ 2549874874 ISOx_DDA_Req_Data 9;
BA_ "GenSigSwitchedByIgnition" SG_ 2549874874 ISOx_DDA_Req_Data 0;
BA_ "GenSigSendType" SG_ 2550005946 ISOx_DDA_Resp_Data 3;
BA_ "GenSigFuncType" SG_ 2550005946 ISOx_DDA_Resp_Data 9;
BA_ "GenSigSwitchedByIgnition" SG_ 2550005946 ISOx_DDA_Resp_Data 0;
BA_ "GenSigSendType" SG_ 2621505536 ISOx_Funkt_Req_All_FD_Data 3;
BA_ "GenSigFuncType" SG_ 2621505536 ISOx_Funkt_Req_All_FD_Data 9;
BA_ "GenSigSwitchedByIgnition" SG_ 2621505536 ISOx_Funkt_Req_All_FD_Data 0;
BA_ "GenSigSendType" SG_ 2549874838 ISOx_LED_LM_L_Req_Data 3;
BA_ "GenSigFuncType" SG_ 2549874838 ISOx_LED_LM_L_Req_Data 9;
BA_ "GenSigSwitchedByIgnition" SG_ 2549874838 ISOx_LED_LM_L_Req_Data 0;
BA_ "GenSigSendType" SG_ 2550005910 ISOx_LED_LM_L_Resp_Data 3;
BA_ "GenSigFuncType" SG_ 2550005910 ISOx_LED_LM_L_Resp_Data 9;
BA_ "GenSigSwitchedByIgnition" SG_ 2550005910 ISOx_LED_LM_L_Resp_Data 0;
BA_ "GenSigSendType" SG_ 2549874839 ISOx_LED_LM_R_Req_Data 3;
BA_ "GenSigFuncType" SG_ 2549874839 ISOx_LED_LM_R_Req_Data 9;
BA_ "GenSigSwitchedByIgnition" SG_ 2549874839 ISOx_LED_LM_R_Req_Data 0;
BA_ "GenSigSendType" SG_ 2550005911 ISOx_LED_LM_R_Resp_Data 3;
BA_ "GenSigFuncType" SG_ 2550005911 ISOx_LED_LM_R_Resp_Data 9;
BA_ "GenSigSwitchedByIgnition" SG_ 2550005911 ISOx_LED_LM_R_Resp_Data 0;
BA_ "GenSigSendType" SG_ 2550398979 ISOx_RSAD_HL_Req_Data 3;
BA_ "GenSigFuncType" SG_ 2550398979 ISOx_RSAD_HL_Req_Data 9;
BA_ "GenSigSwitchedByIgnition" SG_ 2550398979 ISOx_RSAD_HL_Req_Data 0;
BA_ "GenSigSendType" SG_ 2621702147 ISOx_RSAD_HL_Req_FD_Data 3;
BA_ "GenSigFuncType" SG_ 2621702147 ISOx_RSAD_HL_Req_FD_Data 9;
BA_ "GenSigSwitchedByIgnition" SG_ 2621702147 ISOx_RSAD_HL_Req_FD_Data 0;
BA_ "GenSigSendType" SG_ 2550530051 ISOx_RSAD_HL_Resp_Data 3;
BA_ "GenSigFuncType" SG_ 2550530051 ISOx_RSAD_HL_Resp_Data 9;
BA_ "GenSigSwitchedByIgnition" SG_ 2550530051 ISOx_RSAD_HL_Resp_Data 0;
BA_ "GenSigSendType" SG_ 2621833219 ISOx_RSAD_HL_Resp_FD_Data 3;
BA_ "GenSigFuncType" SG_ 2621833219 ISOx_RSAD_HL_Resp_FD_Data 9;
BA_ "GenSigSwitchedByIgnition" SG_ 2621833219 ISOx_RSAD_HL_Resp_FD_Data 0;
BA_ "GenSigSendType" SG_ 2550398980 ISOx_RSAD_HR_Req_Data 3;
BA_ "GenSigFuncType" SG_ 2550398980 ISOx_RSAD_HR_Req_Data 9;
BA_ "GenSigSwitchedByIgnition" SG_ 2550398980 ISOx_RSAD_HR_Req_Data 0;
BA_ "GenSigSendType" SG_ 2621702148 ISOx_RSAD_HR_Req_FD_Data 3;
BA_ "GenSigFuncType" SG_ 2621702148 ISOx_RSAD_HR_Req_FD_Data 9;
BA_ "GenSigSwitchedByIgnition" SG_ 2621702148 ISOx_RSAD_HR_Req_FD_Data 0;
BA_ "GenSigSendType" SG_ 2550530052 ISOx_RSAD_HR_Resp_Data 3;
BA_ "GenSigFuncType" SG_ 2550530052 ISOx_RSAD_HR_Resp_Data 9;
BA_ "GenSigSwitchedByIgnition" SG_ 2550530052 ISOx_RSAD_HR_Resp_Data 0;
BA_ "GenSigSendType" SG_ 2621833220 ISOx_RSAD_HR_Resp_FD_Data 3;
BA_ "GenSigFuncType" SG_ 2621833220 ISOx_RSAD_HR_Resp_FD_Data 9;
BA_ "GenSigSwitchedByIgnition" SG_ 2621833220 ISOx_RSAD_HR_Resp_FD_Data 0;
BA_ "GenSigSendType" SG_ 2550399029 ISOx_RSAD_IN2_Req_Data 3;
BA_ "GenSigFuncType" SG_ 2550399029 ISOx_RSAD_IN2_Req_Data 9;
BA_ "GenSigSwitchedByIgnition" SG_ 2550399029 ISOx_RSAD_IN2_Req_Data 0;
BA_ "GenSigSendType" SG_ 2621702197 ISOx_RSAD_IN2_Req_FD_Data 3;
BA_ "GenSigFuncType" SG_ 2621702197 ISOx_RSAD_IN2_Req_FD_Data 9;
BA_ "GenSigSwitchedByIgnition" SG_ 2621702197 ISOx_RSAD_IN2_Req_FD_Data 0;
BA_ "GenSigSendType" SG_ 2550530101 ISOx_RSAD_IN2_Resp_Data 3;
BA_ "GenSigFuncType" SG_ 2550530101 ISOx_RSAD_IN2_Resp_Data 9;
BA_ "GenSigSwitchedByIgnition" SG_ 2550530101 ISOx_RSAD_IN2_Resp_Data 0;
BA_ "GenSigSendType" SG_ 2621833269 ISOx_RSAD_IN2_Resp_FD_Data 3;
BA_ "GenSigFuncType" SG_ 2621833269 ISOx_RSAD_IN2_Resp_FD_Data 9;
BA_ "GenSigSwitchedByIgnition" SG_ 2621833269 ISOx_RSAD_IN2_Resp_FD_Data 0;
BA_ "GenSigSendType" SG_ 2550399030 ISOx_RSAD_IN3_Req_Data 3;
BA_ "GenSigFuncType" SG_ 2550399030 ISOx_RSAD_IN3_Req_Data 9;
BA_ "GenSigSwitchedByIgnition" SG_ 2550399030 ISOx_RSAD_IN3_Req_Data 0;
BA_ "GenSigSendType" SG_ 2621702198 ISOx_RSAD_IN3_Req_FD_Data 3;
BA_ "GenSigFuncType" SG_ 2621702198 ISOx_RSAD_IN3_Req_FD_Data 9;
BA_ "GenSigSwitchedByIgnition" SG_ 2621702198 ISOx_RSAD_IN3_Req_FD_Data 0;
BA_ "GenSigSendType" SG_ 2550530102 ISOx_RSAD_IN3_Resp_Data 3;
BA_ "GenSigFuncType" SG_ 2550530102 ISOx_RSAD_IN3_Resp_Data 9;
BA_ "GenSigSwitchedByIgnition" SG_ 2550530102 ISOx_RSAD_IN3_Resp_Data 0;
BA_ "GenSigSendType" SG_ 2621833270 ISOx_RSAD_IN3_Resp_FD_Data 3;
BA_ "GenSigFuncType" SG_ 2621833270 ISOx_RSAD_IN3_Resp_FD_Data 9;
BA_ "GenSigSwitchedByIgnition" SG_ 2621833270 ISOx_RSAD_IN3_Resp_FD_Data 0;
BA_ "GenSigSendType" SG_ 2550399031 ISOx_RSAD_IN4_Req_Data 3;
BA_ "GenSigFuncType" SG_ 2550399031 ISOx_RSAD_IN4_Req_Data 9;
BA_ "GenSigSwitchedByIgnition" SG_ 2550399031 ISOx_RSAD_IN4_Req_Data 0;
BA_ "GenSigSendType" SG_ 2621702199 ISOx_RSAD_IN4_Req_FD_Data 3;
BA_ "GenSigFuncType" SG_ 2621702199 ISOx_RSAD_IN4_Req_FD_Data 9;
BA_ "GenSigSwitchedByIgnition" SG_ 2621702199 ISOx_RSAD_IN4_Req_FD_Data 0;
BA_ "GenSigSendType" SG_ 2550530103 ISOx_RSAD_IN4_Resp_Data 3;
BA_ "GenSigFuncType" SG_ 2550530103 ISOx_RSAD_IN4_Resp_Data 9;
BA_ "GenSigSwitchedByIgnition" SG_ 2550530103 ISOx_RSAD_IN4_Resp_Data 0;
BA_ "GenSigSendType" SG_ 2621833271 ISOx_RSAD_IN4_Resp_FD_Data 3;
BA_ "GenSigFuncType" SG_ 2621833271 ISOx_RSAD_IN4_Resp_FD_Data 9;
BA_ "GenSigSwitchedByIgnition" SG_ 2621833271 ISOx_RSAD_IN4_Resp_FD_Data 0;
BA_ "GenSigSendType" SG_ 2550398981 ISOx_RSAD_IN_Req_Data 3;
BA_ "GenSigFuncType" SG_ 2550398981 ISOx_RSAD_IN_Req_Data 9;
BA_ "GenSigSwitchedByIgnition" SG_ 2550398981 ISOx_RSAD_IN_Req_Data 0;
BA_ "GenSigSendType" SG_ 2621702149 ISOx_RSAD_IN_Req_FD_Data 3;
BA_ "GenSigFuncType" SG_ 2621702149 ISOx_RSAD_IN_Req_FD_Data 9;
BA_ "GenSigSwitchedByIgnition" SG_ 2621702149 ISOx_RSAD_IN_Req_FD_Data 0;
BA_ "GenSigSendType" SG_ 2550530053 ISOx_RSAD_IN_Resp_Data 3;
BA_ "GenSigFuncType" SG_ 2550530053 ISOx_RSAD_IN_Resp_Data 9;
BA_ "GenSigSwitchedByIgnition" SG_ 2550530053 ISOx_RSAD_IN_Resp_Data 0;
BA_ "GenSigSendType" SG_ 2621833221 ISOx_RSAD_IN_Resp_FD_Data 3;
BA_ "GenSigFuncType" SG_ 2621833221 ISOx_RSAD_IN_Resp_FD_Data 9;
BA_ "GenSigSwitchedByIgnition" SG_ 2621833221 ISOx_RSAD_IN_Resp_FD_Data 0;
BA_ "GenSigSendType" SG_ 2550398977 ISOx_RSAD_VL_Req_Data 3;
BA_ "GenSigFuncType" SG_ 2550398977 ISOx_RSAD_VL_Req_Data 9;
BA_ "GenSigSwitchedByIgnition" SG_ 2550398977 ISOx_RSAD_VL_Req_Data 0;
BA_ "GenSigSendType" SG_ 2621702145 ISOx_RSAD_VL_Req_FD_Data 3;
BA_ "GenSigFuncType" SG_ 2621702145 ISOx_RSAD_VL_Req_FD_Data 9;
BA_ "GenSigSwitchedByIgnition" SG_ 2621702145 ISOx_RSAD_VL_Req_FD_Data 0;
BA_ "GenSigSendType" SG_ 2550530049 ISOx_RSAD_VL_Resp_Data 3;
BA_ "GenSigFuncType" SG_ 2550530049 ISOx_RSAD_VL_Resp_Data 9;
BA_ "GenSigSwitchedByIgnition" SG_ 2550530049 ISOx_RSAD_VL_Resp_Data 0;
BA_ "GenSigSendType" SG_ 2621833217 ISOx_RSAD_VL_Resp_FD_Data 3;
BA_ "GenSigFuncType" SG_ 2621833217 ISOx_RSAD_VL_Resp_FD_Data 9;
BA_ "GenSigSwitchedByIgnition" SG_ 2621833217 ISOx_RSAD_VL_Resp_FD_Data 0;
BA_ "GenSigSendType" SG_ 2550398978 ISOx_RSAD_VR_Req_Data 3;
BA_ "GenSigFuncType" SG_ 2550398978 ISOx_RSAD_VR_Req_Data 9;
BA_ "GenSigSwitchedByIgnition" SG_ 2550398978 ISOx_RSAD_VR_Req_Data 0;
BA_ "GenSigSendType" SG_ 2621702146 ISOx_RSAD_VR_Req_FD_Data 3;
BA_ "GenSigFuncType" SG_ 2621702146 ISOx_RSAD_VR_Req_FD_Data 9;
BA_ "GenSigSwitchedByIgnition" SG_ 2621702146 ISOx_RSAD_VR_Req_FD_Data 0;
BA_ "GenSigSendType" SG_ 2550530050 ISOx_RSAD_VR_Resp_Data 3;
BA_ "GenSigFuncType" SG_ 2550530050 ISOx_RSAD_VR_Resp_Data 9;
BA_ "GenSigSwitchedByIgnition" SG_ 2550530050 ISOx_RSAD_VR_Resp_Data 0;
BA_ "GenSigSendType" SG_ 2621833218 ISOx_RSAD_VR_Resp_FD_Data 3;
BA_ "GenSigFuncType" SG_ 2621833218 ISOx_RSAD_VR_Resp_FD_Data 9;
BA_ "GenSigSwitchedByIgnition" SG_ 2621833218 ISOx_RSAD_VR_Resp_FD_Data 0;
BA_ "GenSigSendType" SG_ 2621440075 ISOx_TSG_BT_Req_FD_Data 3;
BA_ "GenSigFuncType" SG_ 2621440075 ISOx_TSG_BT_Req_FD_Data 9;
BA_ "GenSigSwitchedByIgnition" SG_ 2621440075 ISOx_TSG_BT_Req_FD_Data 0;
BA_ "GenSigSendType" SG_ 2621571147 ISOx_TSG_BT_Resp_FD_Data 3;
BA_ "GenSigFuncType" SG_ 2621571147 ISOx_TSG_BT_Resp_FD_Data 9;
BA_ "GenSigSwitchedByIgnition" SG_ 2621571147 ISOx_TSG_BT_Resp_FD_Data 0;
BA_ "GenSigSendType" SG_ 2621440074 ISOx_TSG_FT_Req_FD_Data 3;
BA_ "GenSigFuncType" SG_ 2621440074 ISOx_TSG_FT_Req_FD_Data 9;
BA_ "GenSigSwitchedByIgnition" SG_ 2621440074 ISOx_TSG_FT_Req_FD_Data 0;
BA_ "GenSigSendType" SG_ 2621571146 ISOx_TSG_FT_Resp_FD_Data 3;
BA_ "GenSigFuncType" SG_ 2621571146 ISOx_TSG_FT_Resp_FD_Data 9;
BA_ "GenSigSwitchedByIgnition" SG_ 2621571146 ISOx_TSG_FT_Resp_FD_Data 0;
BA_ "GenSigSendType" SG_ 2621440063 ISOx_TSG_HBFS_Req_FD_Data 3;
BA_ "GenSigFuncType" SG_ 2621440063 ISOx_TSG_HBFS_Req_FD_Data 9;
BA_ "GenSigSwitchedByIgnition" SG_ 2621440063 ISOx_TSG_HBFS_Req_FD_Data 0;
BA_ "GenSigSendType" SG_ 2621571135 ISOx_TSG_HBFS_Resp_FD_Data 3;
BA_ "GenSigFuncType" SG_ 2621571135 ISOx_TSG_HBFS_Resp_FD_Data 9;
BA_ "GenSigSwitchedByIgnition" SG_ 2621571135 ISOx_TSG_HBFS_Resp_FD_Data 0;
BA_ "GenSigSendType" SG_ 2621440062 ISOx_TSG_HFS_Req_FD_Data 3;
BA_ "GenSigFuncType" SG_ 2621440062 ISOx_TSG_HFS_Req_FD_Data 9;
BA_ "GenSigSwitchedByIgnition" SG_ 2621440062 ISOx_TSG_HFS_Req_FD_Data 0;
BA_ "GenSigSendType" SG_ 2621571134 ISOx_TSG_HFS_Resp_FD_Data 3;
BA_ "GenSigFuncType" SG_ 2621571134 ISOx_TSG_HFS_Resp_FD_Data 9;
BA_ "GenSigSwitchedByIgnition" SG_ 2621571134 ISOx_TSG_HFS_Resp_FD_Data 0;
BA_ "GenSigSendType" SG_ 2549874853 ISOx_WLC1_Req_Data 3;
BA_ "GenSigFuncType" SG_ 2549874853 ISOx_WLC1_Req_Data 9;
BA_ "GenSigSwitchedByIgnition" SG_ 2549874853 ISOx_WLC1_Req_Data 0;
BA_ "GenSigSendType" SG_ 2621440165 ISOx_WLC1_Req_FD_Data 3;
BA_ "GenSigFuncType" SG_ 2621440165 ISOx_WLC1_Req_FD_Data 9;
BA_ "GenSigSwitchedByIgnition" SG_ 2621440165 ISOx_WLC1_Req_FD_Data 0;
BA_ "GenSigSendType" SG_ 2550005925 ISOx_WLC1_Resp_Data 3;
BA_ "GenSigFuncType" SG_ 2550005925 ISOx_WLC1_Resp_Data 9;
BA_ "GenSigSwitchedByIgnition" SG_ 2550005925 ISOx_WLC1_Resp_Data 0;
BA_ "GenSigSendType" SG_ 2621571237 ISOx_WLC1_Resp_FD_Data 3;
BA_ "GenSigFuncType" SG_ 2621571237 ISOx_WLC1_Resp_FD_Data 9;
BA_ "GenSigSwitchedByIgnition" SG_ 2621571237 ISOx_WLC1_Resp_FD_Data 0;
BA_ "GenSigSendType" SG_ 1425 KY_3_Bremslicht_Ein 5;
BA_ "GenSigSwitchedByIgnition" SG_ 1425 KY_3_Bremslicht_Ein 0;
BA_ "GenSigSendType" SG_ 1425 KY_Bdraten_Rueckspr 3;
BA_ "GenSigSwitchedByIgnition" SG_ 1425 KY_Bdraten_Rueckspr 0;
BA_ "GenSigSendType" SG_ 1425 KY_BFS_Entr 3;
BA_ "GenSigSwitchedByIgnition" SG_ 1425 KY_BFS_Entr 0;
BA_ "GenSigSendType" SG_ 1425 KY_Burst_1 5;
BA_ "GenSigSwitchedByIgnition" SG_ 1425 KY_Burst_1 0;
BA_ "GenSigSendType" SG_ 1425 KY_Burst_2 5;
BA_ "GenSigSwitchedByIgnition" SG_ 1425 KY_Burst_2 0;
BA_ "GenSigSendType" SG_ 1425 KY_Burst_3 5;
BA_ "GenSigSwitchedByIgnition" SG_ 1425 KY_Burst_3 0;
BA_ "GenSigSendType" SG_ 1425 KY_Entry_ETuer_HBFS 3;
BA_ "GenSigSwitchedByIgnition" SG_ 1425 KY_Entry_ETuer_HBFS 0;
BA_ "GenSigSendType" SG_ 1425 KY_Entry_ETuer_HFS 3;
BA_ "GenSigSwitchedByIgnition" SG_ 1425 KY_Entry_ETuer_HFS 0;
BA_ "GenSigSendType" SG_ 1425 KY_FS_Entr 3;
BA_ "GenSigSwitchedByIgnition" SG_ 1425 KY_FS_Entr 0;
BA_ "GenSigSendType" SG_ 1425 KY_Gesamt_Entr 3;
BA_ "GenSigSwitchedByIgnition" SG_ 1425 KY_Gesamt_Entr 0;
BA_ "GenSigSendType" SG_ 1425 KY_HBFS_Entr 3;
BA_ "GenSigSwitchedByIgnition" SG_ 1425 KY_HBFS_Entr 0;
BA_ "GenSigSendType" SG_ 1425 KY_HD_Entr 3;
BA_ "GenSigSwitchedByIgnition" SG_ 1425 KY_HD_Entr 0;
BA_ "GenSigSendType" SG_ 1425 KY_HFS_Entr 3;
BA_ "GenSigSwitchedByIgnition" SG_ 1425 KY_HFS_Entr 0;
BA_ "GenSigSendType" SG_ 1425 KY_HS_Entr 3;
BA_ "GenSigSwitchedByIgnition" SG_ 1425 KY_HS_Entr 0;
BA_ "GenSigSendType" SG_ 1425 KY_Schliessverh_HD 3;
BA_ "GenSigSwitchedByIgnition" SG_ 1425 KY_Schliessverh_HD 0;
BA_ "GenSigSendType" SG_ 1425 KY_VirtuellesPedal_HK 3;
BA_ "GenSigSwitchedByIgnition" SG_ 1425 KY_VirtuellesPedal_HK 0;
BA_ "GenSigSendType" SG_ 1425 KY_Zufallszahl 5;
BA_ "GenSigSwitchedByIgnition" SG_ 1425 KY_Zufallszahl 0;
BA_ "GenSigSendType" SG_ 1426 KY_Aktive_LFScans 3;
BA_ "GenSigSwitchedByIgnition" SG_ 1426 KY_Aktive_LFScans 0;
BA_ "GenSigSendType" SG_ 1426 KY_AnzKoord_Info 3;
BA_ "GenSigSwitchedByIgnition" SG_ 1426 KY_AnzKoord_Info 0;
BA_ "GenSigSendType" SG_ 1426 KY_EasyClose_Abbruch 3;
BA_ "GenSigSwitchedByIgnition" SG_ 1426 KY_EasyClose_Abbruch 0;
BA_ "GenSigSendType" SG_ 1426 KY_EasyClose_Status 3;
BA_ "GenSigSwitchedByIgnition" SG_ 1426 KY_EasyClose_Status 0;
BA_ "GenSigSendType" SG_ 1426 KY_Fzg_Verlassen_erkannt 3;
BA_ "GenSigSwitchedByIgnition" SG_ 1426 KY_Fzg_Verlassen_erkannt 0;
BA_ "GenSigSendType" SG_ 1426 KY_Fzg_Zugang_erkannt 3;
BA_ "GenSigSwitchedByIgnition" SG_ 1426 KY_Fzg_Zugang_erkannt 0;
BA_ "GenSigSendType" SG_ 1426 KY_Gestik_HD 3;
BA_ "GenSigSwitchedByIgnition" SG_ 1426 KY_Gestik_HD 0;
BA_ "GenSigSendType" SG_ 1426 KY_Gong_600 3;
BA_ "GenSigSwitchedByIgnition" SG_ 1426 KY_Gong_600 0;
BA_ "GenSigSendType" SG_ 1426 KY_HD_Auffahrt 3;
BA_ "GenSigSwitchedByIgnition" SG_ 1426 KY_HD_Auffahrt 0;
BA_ "GenSigSendType" SG_ 1426 KY_HD_Zufahrt 3;
BA_ "GenSigSwitchedByIgnition" SG_ 1426 KY_HD_Zufahrt 0;
BA_ "GenSigSendType" SG_ 1426 KY_ID_Geber1_im_Fzg 3;
BA_ "GenSigSwitchedByIgnition" SG_ 1426 KY_ID_Geber1_im_Fzg 0;
BA_ "GenSigSendType" SG_ 1426 KY_ID_Geber2_im_Fzg 3;
BA_ "GenSigSwitchedByIgnition" SG_ 1426 KY_ID_Geber2_im_Fzg 0;
BA_ "GenSigSendType" SG_ 1426 KY_ID_Geber3_im_Fzg 3;
BA_ "GenSigSwitchedByIgnition" SG_ 1426 KY_ID_Geber3_im_Fzg 0;
BA_ "GenSigSendType" SG_ 1426 KY_ID_Geber4_im_Fzg 3;
BA_ "GenSigSwitchedByIgnition" SG_ 1426 KY_ID_Geber4_im_Fzg 0;
BA_ "GenSigSendType" SG_ 1426 KY_ID_Geber_Suche 3;
BA_ "GenSigSwitchedByIgnition" SG_ 1426 KY_ID_Geber_Suche 0;
BA_ "GenSigSendType" SG_ 1426 KY_LF_Aktiv 3;
BA_ "GenSigSwitchedByIgnition" SG_ 1426 KY_LF_Aktiv 0;
BA_ "GenSigSendType" SG_ 1426 KY_Meldungen 3;
BA_ "GenSigSwitchedByIgnition" SG_ 1426 KY_Meldungen 0;
BA_ "GenSigSendType" SG_ 1426 KY_Passiv_Autolock 3;
BA_ "GenSigSwitchedByIgnition" SG_ 1426 KY_Passiv_Autolock 0;
BA_ "GenSigSendType" SG_ 1426 KY_Passiv_Autolock_Akt 3;
BA_ "GenSigSwitchedByIgnition" SG_ 1426 KY_Passiv_Autolock_Akt 0;
BA_ "GenSigSendType" SG_ 1426 KY_Passiv_Autolock_Menue 3;
BA_ "GenSigSwitchedByIgnition" SG_ 1426 KY_Passiv_Autolock_Menue 0;
BA_ "GenSigSendType" SG_ 1426 KY_Passiv_Autounlock 3;
BA_ "GenSigSwitchedByIgnition" SG_ 1426 KY_Passiv_Autounlock 0;
BA_ "GenSigSendType" SG_ 1426 KY_Schluesselposition_1 3;
BA_ "GenSigSwitchedByIgnition" SG_ 1426 KY_Schluesselposition_1 0;
BA_ "GenSigSendType" SG_ 1426 KY_Schluesselposition_2 3;
BA_ "GenSigSwitchedByIgnition" SG_ 1426 KY_Schluesselposition_2 0;
BA_ "GenSigSendType" SG_ 1426 KY_Schluesselposition_3 3;
BA_ "GenSigSwitchedByIgnition" SG_ 1426 KY_Schluesselposition_3 0;
BA_ "GenSigSendType" SG_ 1426 KY_Schluesselposition_4 3;
BA_ "GenSigSwitchedByIgnition" SG_ 1426 KY_Schluesselposition_4 0;
BA_ "GenSigSendType" SG_ 1426 KY_Schluesselposition_5 3;
BA_ "GenSigSwitchedByIgnition" SG_ 1426 KY_Schluesselposition_5 0;
BA_ "GenSigSendType" SG_ 1426 KY_Schluesselposition_6 3;
BA_ "GenSigSwitchedByIgnition" SG_ 1426 KY_Schluesselposition_6 0;
BA_ "GenSigSendType" SG_ 1426 KY_Schluesselposition_7 3;
BA_ "GenSigSwitchedByIgnition" SG_ 1426 KY_Schluesselposition_7 0;
BA_ "GenSigSendType" SG_ 1426 KY_Schluesselposition_8 3;
BA_ "GenSigSwitchedByIgnition" SG_ 1426 KY_Schluesselposition_8 0;
BA_ "GenSigSendType" SG_ 1426 KY_Schluesselposition_9 3;
BA_ "GenSigSwitchedByIgnition" SG_ 1426 KY_Schluesselposition_9 0;
BA_ "GenSigSendType" SG_ 1426 KY_Startknopf_Bel 3;
BA_ "GenSigSwitchedByIgnition" SG_ 1426 KY_Startknopf_Bel 0;
BA_ "GenSigSendType" SG_ 1426 KY_StartStopp_Info 3;
BA_ "GenSigSwitchedByIgnition" SG_ 1426 KY_StartStopp_Info 0;
BA_ "GenSigSendType" SG_ 960 BCM_Ausparken_Betrieb 3;
BA_ "GenSigSwitchedByIgnition" SG_ 960 BCM_Ausparken_Betrieb 0;
BA_ "GenSigSendType" SG_ 960 BCM_Remotestart_Betrieb 3;
BA_ "GenSigSwitchedByIgnition" SG_ 960 BCM_Remotestart_Betrieb 0;
BA_ "GenSigSendType" SG_ 960 BCM_Remotestart_KL15_Anf 3;
BA_ "GenSigSwitchedByIgnition" SG_ 960 BCM_Remotestart_KL15_Anf 0;
BA_ "GenSigSendType" SG_ 960 BCM_Remotestart_MO_Start 3;
BA_ "GenSigSwitchedByIgnition" SG_ 960 BCM_Remotestart_MO_Start 0;
BA_ "GenSigSendType" SG_ 960 Klemmen_Status_01_BZ 0;
BA_ "GenSigFuncType" SG_ 960 Klemmen_Status_01_BZ 1;
BA_ "GenSigSwitchedByIgnition" SG_ 960 Klemmen_Status_01_BZ 0;
BA_ "GenSigSendType" SG_ 960 Klemmen_Status_01_CRC 0;
BA_ "GenSigFuncType" SG_ 960 Klemmen_Status_01_CRC 2;
BA_ "GenSigSwitchedByIgnition" SG_ 960 Klemmen_Status_01_CRC 0;
BA_ "GenSigSendType" SG_ 960 KST_Fahrerhinweis_1 3;
BA_ "GenSigSwitchedByIgnition" SG_ 960 KST_Fahrerhinweis_1 0;
BA_ "GenSigSendType" SG_ 960 KST_Fahrerhinweis_2 3;
BA_ "GenSigSwitchedByIgnition" SG_ 960 KST_Fahrerhinweis_2 0;
BA_ "GenSigSendType" SG_ 960 KST_Fahrerhinweis_4 3;
BA_ "GenSigSwitchedByIgnition" SG_ 960 KST_Fahrerhinweis_4 0;
BA_ "GenSigSendType" SG_ 960 KST_Fahrerhinweis_5 3;
BA_ "GenSigSwitchedByIgnition" SG_ 960 KST_Fahrerhinweis_5 0;
BA_ "GenSigSendType" SG_ 960 KST_Fahrerhinweis_6 3;
BA_ "GenSigSwitchedByIgnition" SG_ 960 KST_Fahrerhinweis_6 0;
BA_ "GenSigSendType" SG_ 960 KST_Warn_P1_ZST_def 3;
BA_ "GenSigSwitchedByIgnition" SG_ 960 KST_Warn_P1_ZST_def 0;
BA_ "GenSigSendType" SG_ 960 KST_Warn_P2_ZST_def 3;
BA_ "GenSigSwitchedByIgnition" SG_ 960 KST_Warn_P2_ZST_def 0;
BA_ "GenSigSendType" SG_ 960 RSt_Fahrerhinweise 3;
BA_ "GenSigSwitchedByIgnition" SG_ 960 RSt_Fahrerhinweise 0;
BA_ "GenSigSendType" SG_ 960 ZAS_Kl_15 3;
BA_ "NWM-WakeupAllowed" SG_ 960 ZAS_Kl_15 1;
BA_ "GenSigFuncType" SG_ 960 ZAS_Kl_15 6;
BA_ "GenSigSwitchedByIgnition" SG_ 960 ZAS_Kl_15 0;
BA_ "GenSigSendType" SG_ 960 ZAS_Kl_50_Startanforderung 3;
BA_ "GenSigSwitchedByIgnition" SG_ 960 ZAS_Kl_50_Startanforderung 0;
BA_ "GenSigSendType" SG_ 960 ZAS_Kl_Infotainment 3;
BA_ "GenSigSwitchedByIgnition" SG_ 960 ZAS_Kl_Infotainment 0;
BA_ "GenSigSendType" SG_ 960 ZAS_Kl_S 3;
BA_ "GenSigSwitchedByIgnition" SG_ 960 ZAS_Kl_S 0;
BA_ "GenSigSendType" SG_ 960 ZAS_Kl_X 3;
BA_ "GenSigSwitchedByIgnition" SG_ 960 ZAS_Kl_X 0;
BA_ "GenSigSendType" SG_ 2463978753 Klemmen_Status_02_BZ 0;
BA_ "GenSigFuncType" SG_ 2463978753 Klemmen_Status_02_BZ 1;
BA_ "GenSigSwitchedByIgnition" SG_ 2463978753 Klemmen_Status_02_BZ 0;
BA_ "GenSigSendType" SG_ 2463978753 Klemmen_Status_02_CRC 0;
BA_ "GenSigFuncType" SG_ 2463978753 Klemmen_Status_02_CRC 2;
BA_ "GenSigSwitchedByIgnition" SG_ 2463978753 Klemmen_Status_02_CRC 0;
BA_ "GenSigSendType" SG_ 2463978753 KST_ComfortReadyStatus 4;
BA_ "GenSigSwitchedByIgnition" SG_ 2463978753 KST_ComfortReadyStatus 0;
BA_ "GenSigSendType" SG_ 2463978753 KST_Freigabe_Zustand 4;
BA_ "GenSigSwitchedByIgnition" SG_ 2463978753 KST_Freigabe_Zustand 0;
BA_ "GenSigSendType" SG_ 2463978753 KST_Sonderzustand_Anforderung 4;
BA_ "GenSigSwitchedByIgnition" SG_ 2463978753 KST_Sonderzustand_Anforderung 0;
BA_ "Fehlerwert" SG_ 2463978753 KST_Sonderzustand_Anforderung 31;
BA_ "GenSigSendType" SG_ 2463978753 KST_Sonderzustand_Status 4;
BA_ "GenSigSwitchedByIgnition" SG_ 2463978753 KST_Sonderzustand_Status 0;
BA_ "Fehlerwert" SG_ 2463978753 KST_Sonderzustand_Status 3;
BA_ "GenSigSendType" SG_ 2463978753 KST_WFS_Fahrfreigabe_Anforderung 4;
BA_ "GenSigSwitchedByIgnition" SG_ 2463978753 KST_WFS_Fahrfreigabe_Anforderung 0;
BA_ "GenSigSendType" SG_ 1420 Klemmen_Steuerung_01_BZ 0;
BA_ "GenSigFuncType" SG_ 1420 Klemmen_Steuerung_01_BZ 1;
BA_ "GenSigSwitchedByIgnition" SG_ 1420 Klemmen_Steuerung_01_BZ 0;
BA_ "GenSigSendType" SG_ 1420 Klemmen_Steuerung_01_CRC 0;
BA_ "GenSigFuncType" SG_ 1420 Klemmen_Steuerung_01_CRC 2;
BA_ "GenSigSwitchedByIgnition" SG_ 1420 Klemmen_Steuerung_01_CRC 0;
BA_ "GenSigSendType" SG_ 1420 KST_Anf_Klemme_15 4;
BA_ "GenSigSwitchedByIgnition" SG_ 1420 KST_Anf_Klemme_15 0;
BA_ "GenSigSendType" SG_ 1420 KST_Anf_Klemme_50 4;
BA_ "GenSigSwitchedByIgnition" SG_ 1420 KST_Anf_Klemme_50 0;
BA_ "GenSigSendType" SG_ 1420 KST_Anf_Klemme_S 3;
BA_ "GenSigSwitchedByIgnition" SG_ 1420 KST_Anf_Klemme_S 0;
BA_ "GenSigSendType" SG_ 1420 KST_Anf_Klemmenfreigabe_ELV 3;
BA_ "GenSigSwitchedByIgnition" SG_ 1420 KST_Anf_Klemmenfreigabe_ELV 0;
BA_ "GenSigSendType" SG_ 1420 KST_Anf_Klemmenfreigabe_WFS 3;
BA_ "GenSigSwitchedByIgnition" SG_ 1420 KST_Anf_Klemmenfreigabe_WFS 0;
BA_ "GenSigSendType" SG_ 1420 KST_Anf_ZV_Verriegelung 3;
BA_ "GenSigSwitchedByIgnition" SG_ 1420 KST_Anf_ZV_Verriegelung 0;
BA_ "GenSigSendType" SG_ 1420 KST_Anzeige_Klemmenzustand 3;
BA_ "GenSigSwitchedByIgnition" SG_ 1420 KST_Anzeige_Klemmenzustand 0;
BA_ "GenSigSendType" SG_ 1420 KST_aut_Abschaltung_Zuendung 4;
BA_ "GenSigSwitchedByIgnition" SG_ 1420 KST_aut_Abschaltung_Zuendung 0;
BA_ "GenSigSendType" SG_ 1420 KST_Txt_Komfortabschaltung 3;
BA_ "GenSigSwitchedByIgnition" SG_ 1420 KST_Txt_Komfortabschaltung 0;
BA_ "GenSigSendType" SG_ 1420 KST_Txt_P_Gang 3;
BA_ "GenSigSwitchedByIgnition" SG_ 1420 KST_Txt_P_Gang 0;
BA_ "GenSigSendType" SG_ 1420 KST_Txt_Panikabschaltung 3;
BA_ "GenSigSwitchedByIgnition" SG_ 1420 KST_Txt_Panikabschaltung 0;
BA_ "GenSigSendType" SG_ 1420 KST_Txt_Werkstatt 3;
BA_ "GenSigSwitchedByIgnition" SG_ 1420 KST_Txt_Werkstatt 0;
BA_ "GenSigSendType" SG_ 1420 KST_Unterdr_Zuendungsmeldung 3;
BA_ "GenSigSwitchedByIgnition" SG_ 1420 KST_Unterdr_Zuendungsmeldung 0;
BA_ "GenSigSendType" SG_ 1420 KST_ZAT_betaetigt 3;
BA_ "GenSigSwitchedByIgnition" SG_ 1420 KST_ZAT_betaetigt 0;
BA_ "GenSigSendType" SG_ 1420 KST_Zuendungswarnung 4;
BA_ "GenSigSwitchedByIgnition" SG_ 1420 KST_Zuendungswarnung 0;
BA_ "GenSigSendType" SG_ 1420 Relais_VoKo_angesteuert 3;
BA_ "GenSigSwitchedByIgnition" SG_ 1420 Relais_VoKo_angesteuert 0;
BA_ "GenSigSendType" SG_ 1420 RSt_Anforderung_HMS 3;
BA_ "GenSigSwitchedByIgnition" SG_ 1420 RSt_Anforderung_HMS 0;
BA_ "GenSigSendType" SG_ 1646 KL_Anf_AussenspiegelHzg 3;
BA_ "GenSigSwitchedByIgnition" SG_ 1646 KL_Anf_AussenspiegelHzg 0;
BA_ "GenSigSendType" SG_ 1646 KL_BCmE_Livetip_Freigabe 3;
BA_ "GenSigSwitchedByIgnition" SG_ 1646 KL_BCmE_Livetip_Freigabe 0;
BA_ "GenSigSendType" SG_ 1646 KL_ErwVK_Anf 3;
BA_ "GenSigSwitchedByIgnition" SG_ 1646 KL_ErwVK_Anf 0;
BA_ "GenSigSendType" SG_ 1646 KL_FSH_Automatikbetrieb 3;
BA_ "GenSigSwitchedByIgnition" SG_ 1646 KL_FSH_Automatikbetrieb 0;
BA_ "GenSigSendType" SG_ 1646 KL_Geblaese_Fond_Status 0;
BA_ "GenSigStartValue" SG_ 1646 KL_Geblaese_Fond_Status 14;
BA_ "GenSigSwitchedByIgnition" SG_ 1646 KL_Geblaese_Fond_Status 0;
BA_ "Fehlerwert" SG_ 1646 KL_Geblaese_Fond_Status 15;
BA_ "GenSigSendType" SG_ 1646 KL_Geblaese_Status 0;
BA_ "GenSigStartValue" SG_ 1646 KL_Geblaese_Status 14;
BA_ "GenSigSwitchedByIgnition" SG_ 1646 KL_Geblaese_Status 0;
BA_ "Fehlerwert" SG_ 1646 KL_Geblaese_Status 15;
BA_ "GenSigSendType" SG_ 1646 KL_Heizkreisventilstellung 0;
BA_ "GenSigSwitchedByIgnition" SG_ 1646 KL_Heizkreisventilstellung 0;
BA_ "Fehlerwert" SG_ 1646 KL_Heizkreisventilstellung 3;
BA_ "GenSigSendType" SG_ 1646 KL_I_Geblaese_Fond 3;
BA_ "GenSigSwitchedByIgnition" SG_ 1646 KL_I_Geblaese_Fond 0;
BA_ "Fehlerwert" SG_ 1646 KL_I_Geblaese_Fond 255;
BA_ "GenSigSendType" SG_ 1646 KL_Innen_Temp 0;
BA_ "GenSigStartValue" SG_ 1646 KL_Innen_Temp 254;
BA_ "GenSigSwitchedByIgnition" SG_ 1646 KL_Innen_Temp 0;
BA_ "Fehlerwert" SG_ 1646 KL_Innen_Temp 255;
BA_ "GenSigSendType" SG_ 1646 KL_Kompressorkupplung 3;
BA_ "GenSigSwitchedByIgnition" SG_ 1646 KL_Kompressorkupplung 0;
BA_ "GenSigSendType" SG_ 1646 KL_Magnetventil 3;
BA_ "GenSigSwitchedByIgnition" SG_ 1646 KL_Magnetventil 0;
BA_ "GenSigSendType" SG_ 1646 KL_Restwaerme_aktiv 3;
BA_ "GenSigSwitchedByIgnition" SG_ 1646 KL_Restwaerme_aktiv 0;
BA_ "GenSigSendType" SG_ 1646 KL_SH_Soll_hl 3;
BA_ "GenSigSwitchedByIgnition" SG_ 1646 KL_SH_Soll_hl 0;
BA_ "GenSigSendType" SG_ 1646 KL_SH_Soll_hr 3;
BA_ "GenSigSwitchedByIgnition" SG_ 1646 KL_SH_Soll_hr 0;
BA_ "GenSigSendType" SG_ 1646 KL_SIH_LEH_Verteilung_VL 3;
BA_ "GenSigSwitchedByIgnition" SG_ 1646 KL_SIH_LEH_Verteilung_VL 0;
BA_ "GenSigSendType" SG_ 1646 KL_SIH_LEH_Verteilung_VR 3;
BA_ "GenSigSwitchedByIgnition" SG_ 1646 KL_SIH_LEH_Verteilung_VR 0;
BA_ "GenSigSendType" SG_ 1646 KL_SIH_LEL_Verteilung_VL 3;
BA_ "GenSigSwitchedByIgnition" SG_ 1646 KL_SIH_LEL_Verteilung_VL 0;
BA_ "GenSigSendType" SG_ 1646 KL_SIH_LEL_Verteilung_VR 3;
BA_ "GenSigSwitchedByIgnition" SG_ 1646 KL_SIH_LEL_Verteilung_VR 0;
BA_ "GenSigSendType" SG_ 1646 KL_Solarluefter_aktiv 3;
BA_ "GenSigSwitchedByIgnition" SG_ 1646 KL_Solarluefter_aktiv 0;
BA_ "GenSigSendType" SG_ 1646 KL_STH_aktiv 3;
BA_ "GenSigSwitchedByIgnition" SG_ 1646 KL_STH_aktiv 0;
BA_ "GenSigSendType" SG_ 1646 KL_STH_Ansteuerung 3;
BA_ "GenSigSwitchedByIgnition" SG_ 1646 KL_STH_Ansteuerung 0;
BA_ "GenSigSendType" SG_ 1646 KL_STH_Betriebsdauer 3;
BA_ "GenSigSwitchedByIgnition" SG_ 1646 KL_STH_Betriebsdauer 0;
BA_ "GenSigSendType" SG_ 1646 KL_STL_aktiv 3;
BA_ "GenSigSwitchedByIgnition" SG_ 1646 KL_STL_aktiv 0;
BA_ "GenSigSendType" SG_ 1646 KL_Umluft_Taste 3;
BA_ "GenSigSwitchedByIgnition" SG_ 1646 KL_Umluft_Taste 0;
BA_ "GenSigSendType" SG_ 1646 KL_WaPu 3;
BA_ "GenSigSwitchedByIgnition" SG_ 1646 KL_WaPu 0;
BA_ "GenSigActiveRepetitions" SG_ 1640 FSH_Taster 5;
BA_ "GenSigSendType" SG_ 1640 FSH_Taster 4;
BA_ "GenSigSwitchedByIgnition" SG_ 1640 FSH_Taster 0;
BA_ "GenSigActiveRepetitions" SG_ 1640 HSH_Taster 5;
BA_ "GenSigSendType" SG_ 1640 HSH_Taster 4;
BA_ "GenSigSwitchedByIgnition" SG_ 1640 HSH_Taster 0;
BA_ "GenSigSendType" SG_ 1640 KL_Beschlagsgefahr 3;
BA_ "GenSigSwitchedByIgnition" SG_ 1640 KL_Beschlagsgefahr 0;
BA_ "GenSigSendType" SG_ 1640 KL_Geblspng_Fond_Soll 0;
BA_ "GenSigSwitchedByIgnition" SG_ 1640 KL_Geblspng_Fond_Soll 0;
BA_ "Fehlerwert" SG_ 1640 KL_Geblspng_Fond_Soll 255;
BA_ "GenSigSendType" SG_ 1640 KL_Geblspng_Soll 0;
BA_ "GenSigSwitchedByIgnition" SG_ 1640 KL_Geblspng_Soll 0;
BA_ "Fehlerwert" SG_ 1640 KL_Geblspng_Soll 255;
BA_ "GenSigSendType" SG_ 1640 KL_I_Geblaese 0;
BA_ "GenSigSwitchedByIgnition" SG_ 1640 KL_I_Geblaese 0;
BA_ "Fehlerwert" SG_ 1640 KL_I_Geblaese 255;
BA_ "GenSigSendType" SG_ 1640 KL_Kompressorstrom_soll 0;
BA_ "GenSigStartValue" SG_ 1640 KL_Kompressorstrom_soll 1022;
BA_ "GenSigSwitchedByIgnition" SG_ 1640 KL_Kompressorstrom_soll 0;
BA_ "Fehlerwert" SG_ 1640 KL_Kompressorstrom_soll 1023;
BA_ "GenSigSendType" SG_ 1640 KL_LRH_Stufe 3;
BA_ "GenSigStartValue" SG_ 1640 KL_LRH_Stufe 1;
BA_ "GenSigSwitchedByIgnition" SG_ 1640 KL_LRH_Stufe 0;
BA_ "GenSigActiveRepetitions" SG_ 1640 KL_LRH_Taster 5;
BA_ "GenSigSendType" SG_ 1640 KL_LRH_Taster 4;
BA_ "GenSigSwitchedByIgnition" SG_ 1640 KL_LRH_Taster 0;
BA_ "GenSigSendType" SG_ 1640 KL_PTC_Verbauinfo 0;
BA_ "GenSigSwitchedByIgnition" SG_ 1640 KL_PTC_Verbauinfo 0;
BA_ "GenSigSendType" SG_ 1640 KL_SIH_Soll_li 3;
BA_ "GenSigSwitchedByIgnition" SG_ 1640 KL_SIH_Soll_li 0;
BA_ "GenSigSendType" SG_ 1640 KL_SIH_Soll_re 3;
BA_ "GenSigSwitchedByIgnition" SG_ 1640 KL_SIH_Soll_re 0;
BA_ "GenSigSendType" SG_ 1640 KL_SIL_Soll_li 3;
BA_ "GenSigSwitchedByIgnition" SG_ 1640 KL_SIL_Soll_li 0;
BA_ "GenSigSendType" SG_ 1640 KL_SIL_Soll_re 3;
BA_ "GenSigSwitchedByIgnition" SG_ 1640 KL_SIL_Soll_re 0;
BA_ "GenSigSendType" SG_ 1640 KL_Umluftklappe_Status 0;
BA_ "GenSigStartValue" SG_ 1640 KL_Umluftklappe_Status 14;
BA_ "GenSigSwitchedByIgnition" SG_ 1640 KL_Umluftklappe_Status 0;
BA_ "Fehlerwert" SG_ 1640 KL_Umluftklappe_Status 15;
BA_ "GenSigSendType" SG_ 1640 KL_Zuheizer_Freigabe 3;
BA_ "GenSigSwitchedByIgnition" SG_ 1640 KL_Zuheizer_Freigabe 0;
BA_ "GenSigSendType" SG_ 1640 KRH_Soll_li 3;
BA_ "GenSigSwitchedByIgnition" SG_ 1640 KRH_Soll_li 0;
BA_ "GenSigSendType" SG_ 1640 KRH_Soll_re 3;
BA_ "GenSigSwitchedByIgnition" SG_ 1640 KRH_Soll_re 0;
BA_ "GenSigSendType" SG_ 2527679635 FSH_Status 0;
BA_ "GenSigSwitchedByIgnition" SG_ 2527679635 FSH_Status 0;
BA_ "Fehlerwert" SG_ 2527679635 FSH_Status 3;
BA_ "GenSigSendType" SG_ 2527679635 HSH_Relais_Anf 3;
BA_ "GenSigSwitchedByIgnition" SG_ 2527679635 HSH_Relais_Anf 0;
BA_ "GenSigSendType" SG_ 2527679635 KL_AL_HL_Anf 3;
BA_ "GenSigSwitchedByIgnition" SG_ 2527679635 KL_AL_HL_Anf 0;
BA_ "GenSigSendType" SG_ 2527679635 KL_AL_HR_Anf 3;
BA_ "GenSigSwitchedByIgnition" SG_ 2527679635 KL_AL_HR_Anf 0;
BA_ "GenSigSendType" SG_ 2527679635 KL_AL_VL_Anf 3;
BA_ "GenSigSwitchedByIgnition" SG_ 2527679635 KL_AL_VL_Anf 0;
BA_ "GenSigSendType" SG_ 2527679635 KL_AL_VR_Anf 3;
BA_ "GenSigSwitchedByIgnition" SG_ 2527679635 KL_AL_VR_Anf 0;
BA_ "GenSigSendType" SG_ 2527679635 KL_Defrost_LED 3;
BA_ "GenSigSwitchedByIgnition" SG_ 2527679635 KL_Defrost_LED 0;
BA_ "GenSigSendType" SG_ 2527679635 KL_FSH_LED 3;
BA_ "GenSigSwitchedByIgnition" SG_ 2527679635 KL_FSH_LED 0;
BA_ "GenSigSendType" SG_ 2527679635 KL_FSH_Soll 3;
BA_ "GenSigSwitchedByIgnition" SG_ 2527679635 KL_FSH_Soll 0;
BA_ "GenSigSendType" SG_ 2527679635 KL_Heizstufe_LSH 3;
BA_ "GenSigSwitchedByIgnition" SG_ 2527679635 KL_Heizstufe_LSH 0;
BA_ "Fehlerwert" SG_ 2527679635 KL_Heizstufe_LSH 15;
BA_ "GenSigSendType" SG_ 2527679635 KL_HSH_LED 3;
BA_ "GenSigSwitchedByIgnition" SG_ 2527679635 KL_HSH_LED 0;
BA_ "GenSigSendType" SG_ 2527679635 KL_HSH_Soll 3;
BA_ "GenSigSwitchedByIgnition" SG_ 2527679635 KL_HSH_Soll 0;
BA_ "GenSigSendType" SG_ 2527679635 KL_HUP_aktiv 3;
BA_ "GenSigSwitchedByIgnition" SG_ 2527679635 KL_HUP_aktiv 0;
BA_ "GenSigSendType" SG_ 2527679635 KL_Klappe_Status 3;
BA_ "GenSigSwitchedByIgnition" SG_ 2527679635 KL_Klappe_Status 0;
BA_ "GenSigSendType" SG_ 2527679635 KL_LRH_PWM 3;
BA_ "GenSigSwitchedByIgnition" SG_ 2527679635 KL_LRH_PWM 0;
BA_ "GenSigSendType" SG_ 2527679635 KL_LRH_Soll 3;
BA_ "GenSigSwitchedByIgnition" SG_ 2527679635 KL_LRH_Soll 0;
BA_ "GenSigSendType" SG_ 2527679635 KL_LSH_Ansteuerung 3;
BA_ "GenSigSwitchedByIgnition" SG_ 2527679635 KL_LSH_Ansteuerung 0;
BA_ "GenSigSendType" SG_ 2527679635 KL_LSH_Betriebsdauer 3;
BA_ "GenSigSwitchedByIgnition" SG_ 2527679635 KL_LSH_Betriebsdauer 0;
BA_ "GenSigSendType" SG_ 2527679635 KL_LSH_DBetr_Bestaet 3;
BA_ "GenSigSwitchedByIgnition" SG_ 2527679635 KL_LSH_DBetr_Bestaet 0;
BA_ "GenSigSendType" SG_ 2527679635 KL_LSH_DBetr_Ein 3;
BA_ "GenSigSwitchedByIgnition" SG_ 2527679635 KL_LSH_DBetr_Ein 0;
BA_ "GenSigSendType" SG_ 2527679635 KL_Temp_ZH_Soll 3;
BA_ "GenSigSwitchedByIgnition" SG_ 2527679635 KL_Temp_ZH_Soll 0;
BA_ "Fehlerwert" SG_ 2527679635 KL_Temp_ZH_Soll 255;
BA_ "GenSigSendType" SG_ 2527679635 KL_VoKo_LED 3;
BA_ "GenSigSwitchedByIgnition" SG_ 2527679635 KL_VoKo_LED 0;
BA_ "GenSigSendType" SG_ 2527679635 KL_Voko_Status 3;
BA_ "GenSigStartValue" SG_ 2527679635 KL_Voko_Status 14;
BA_ "GenSigSwitchedByIgnition" SG_ 2527679635 KL_Voko_Status 0;
BA_ "Fehlerwert" SG_ 2527679635 KL_Voko_Status 15;
BA_ "GenSigSendType" SG_ 2527679635 KL_ZR_Anforderung 3;
BA_ "GenSigSwitchedByIgnition" SG_ 2527679635 KL_ZR_Anforderung 0;
BA_ "GenSigSendType" SG_ 2527679635 SIH_Stufe_LED_li 3;
BA_ "GenSigSwitchedByIgnition" SG_ 2527679635 SIH_Stufe_LED_li 0;
BA_ "GenSigSendType" SG_ 2527679635 SIH_Stufe_LED_re 3;
BA_ "GenSigSwitchedByIgnition" SG_ 2527679635 SIH_Stufe_LED_re 0;
BA_ "GenSigSendType" SG_ 1712 FS_Luftfeuchte_rel 0;
BA_ "Fehlerwert" SG_ 1712 FS_Luftfeuchte_rel 255;
BA_ "GenSigMissingSourceValue" SG_ 1712 FS_Luftfeuchte_rel 255;
BA_ "GenSigSendType" SG_ 1712 FS_ResponseError 0;
BA_ "Fehlerwert" SG_ 1712 FS_ResponseError 1;
BA_ "GenSigSendType" SG_ 1712 FS_Taupunkt 0;
BA_ "Fehlerwert" SG_ 1712 FS_Taupunkt 1023;
BA_ "GenSigMissingSourceValue" SG_ 1712 FS_Taupunkt 1023;
BA_ "GenSigSendType" SG_ 1712 FS_Temp_Scheibe 0;
BA_ "Fehlerwert" SG_ 1712 FS_Temp_Scheibe 1023;
BA_ "GenSigMissingSourceValue" SG_ 1712 FS_Temp_Scheibe 1023;
BA_ "GenSigSendType" SG_ 1712 FS_Temp_Sensor 0;
BA_ "Fehlerwert" SG_ 1712 FS_Temp_Sensor 255;
BA_ "GenSigMissingSourceValue" SG_ 1712 FS_Temp_Sensor 255;
BA_ "GenSigSendType" SG_ 1505 BCM1_Aussen_Temp_ungef 0;
BA_ "GenSigStartValue" SG_ 1505 BCM1_Aussen_Temp_ungef 254;
BA_ "GenSigSwitchedByIgnition" SG_ 1505 BCM1_Aussen_Temp_ungef 0;
BA_ "Fehlerwert" SG_ 1505 BCM1_Aussen_Temp_ungef 255;
BA_ "GenSigSendType" SG_ 1505 BCM1_FStatus_Aussentemp_ungef 0;
BA_ "GenSigStartValue" SG_ 1505 BCM1_FStatus_Aussentemp_ungef 1;
BA_ "GenSigSwitchedByIgnition" SG_ 1505 BCM1_FStatus_Aussentemp_ungef 0;
BA_ "GenSigSendType" SG_ 1505 BCM1_Kompressorstrom_ist 0;
BA_ "GenSigStartValue" SG_ 1505 BCM1_Kompressorstrom_ist 254;
BA_ "GenSigSwitchedByIgnition" SG_ 1505 BCM1_Kompressorstrom_ist 0;
BA_ "Fehlerwert" SG_ 1505 BCM1_Kompressorstrom_ist 255;
BA_ "GenSigSendType" SG_ 1505 BCM1_OBD_FStatus_ATemp 0;
BA_ "GenSigSwitchedByIgnition" SG_ 1505 BCM1_OBD_FStatus_ATemp 0;
BA_ "GenSigSendType" SG_ 1505 BCM1_PTC_stufig_Status 0;
BA_ "GenSigStartValue" SG_ 1505 BCM1_PTC_stufig_Status 6;
BA_ "GenSigSwitchedByIgnition" SG_ 1505 BCM1_PTC_stufig_Status 0;
BA_ "Fehlerwert" SG_ 1505 BCM1_PTC_stufig_Status 7;
BA_ "GenSigSendType" SG_ 1505 BCM_Heizungsabsperrventil_Status 0;
BA_ "GenSigStartValue" SG_ 1505 BCM_Heizungsabsperrventil_Status 2;
BA_ "GenSigSwitchedByIgnition" SG_ 1505 BCM_Heizungsabsperrventil_Status 0;
BA_ "Fehlerwert" SG_ 1505 BCM_Heizungsabsperrventil_Status 3;
BA_ "GenSigSendType" SG_ 1505 BCM_Heizungspumpe_Status 0;
BA_ "GenSigStartValue" SG_ 1505 BCM_Heizungspumpe_Status 2;
BA_ "GenSigSwitchedByIgnition" SG_ 1505 BCM_Heizungspumpe_Status 0;
BA_ "Fehlerwert" SG_ 1505 BCM_Heizungspumpe_Status 3;
BA_ "GenSigSendType" SG_ 1505 BCM_Kompressorkupplung_Status 0;
BA_ "GenSigStartValue" SG_ 1505 BCM_Kompressorkupplung_Status 2;
BA_ "GenSigSwitchedByIgnition" SG_ 1505 BCM_Kompressorkupplung_Status 0;
BA_ "Fehlerwert" SG_ 1505 BCM_Kompressorkupplung_Status 3;
BA_ "GenSigSendType" SG_ 605 KLR_01_BZ 0;
BA_ "GenSigFuncType" SG_ 605 KLR_01_BZ 1;
BA_ "GenSigSwitchedByIgnition" SG_ 605 KLR_01_BZ 0;
BA_ "GenSigSendType" SG_ 605 KLR_01_CRC 0;
BA_ "GenSigFuncType" SG_ 605 KLR_01_CRC 2;
BA_ "GenSigSwitchedByIgnition" SG_ 605 KLR_01_CRC 0;
BA_ "GenSigSendType" SG_ 605 KLR_Fehler 0;
BA_ "GenSigSwitchedByIgnition" SG_ 605 KLR_Fehler 0;
BA_ "Fehlerwert" SG_ 605 KLR_Fehler 1;
BA_ "GenSigSendType" SG_ 605 KLR_Fehler_Codierung 0;
BA_ "GenSigSwitchedByIgnition" SG_ 605 KLR_Fehler_Codierung 0;
BA_ "Fehlerwert" SG_ 605 KLR_Fehler_Codierung 1;
BA_ "GenSigSendType" SG_ 605 KLR_reserveByte2_6 0;
BA_ "GenSigSendType" SG_ 605 KLR_reserveByte6_4 0;
BA_ "GenSigSendType" SG_ 605 KLR_reserveByte7 0;
BA_ "GenSigSendType" SG_ 605 KLR_reserveByte8 0;
BA_ "GenSigSendType" SG_ 605 KLR_ResponseError 0;
BA_ "GenSigSwitchedByIgnition" SG_ 605 KLR_ResponseError 0;
BA_ "Fehlerwert" SG_ 605 KLR_ResponseError 1;
BA_ "GenSigSendType" SG_ 605 KLR_Touchauswertung 0;
BA_ "GenSigStartValue" SG_ 605 KLR_Touchauswertung 14;
BA_ "GenSigSwitchedByIgnition" SG_ 605 KLR_Touchauswertung 0;
BA_ "GenSigSendType" SG_ 605 KLR_Touchintensitaet_1 0;
BA_ "GenSigStartValue" SG_ 605 KLR_Touchintensitaet_1 254;
BA_ "GenSigSwitchedByIgnition" SG_ 605 KLR_Touchintensitaet_1 0;
BA_ "Fehlerwert" SG_ 605 KLR_Touchintensitaet_1 255;
BA_ "GenSigSendType" SG_ 605 KLR_Touchintensitaet_2 0;
BA_ "GenSigStartValue" SG_ 605 KLR_Touchintensitaet_2 254;
BA_ "GenSigSwitchedByIgnition" SG_ 605 KLR_Touchintensitaet_2 0;
BA_ "Fehlerwert" SG_ 605 KLR_Touchintensitaet_2 255;
BA_ "GenSigSendType" SG_ 605 KLR_Touchintensitaet_3 0;
BA_ "GenSigStartValue" SG_ 605 KLR_Touchintensitaet_3 254;
BA_ "GenSigSwitchedByIgnition" SG_ 605 KLR_Touchintensitaet_3 0;
BA_ "Fehlerwert" SG_ 605 KLR_Touchintensitaet_3 255;
BA_ "GenSigSendType" SG_ 2549088270 BCM1_Abschaltstufe 0;
BA_ "GenSigSwitchedByIgnition" SG_ 2549088270 BCM1_Abschaltstufe 0;
BA_ "GenSigSendType" SG_ 2549088270 BCM1_KD_Fehler 0;
BA_ "GenSigSwitchedByIgnition" SG_ 2549088270 BCM1_KD_Fehler 0;
BA_ "GenSigSendType" SG_ 2549088270 BCM1_KompSchutz 0;
BA_ "GenSigSwitchedByIgnition" SG_ 2549088270 BCM1_KompSchutz 0;
BA_ "GenSigSendType" SG_ 2549088270 BCM1_Nachlauftyp 0;
BA_ "GenSigStartValue" SG_ 2549088270 BCM1_Nachlauftyp 2;
BA_ "GenSigSwitchedByIgnition" SG_ 2549088270 BCM1_Nachlauftyp 0;
BA_ "GenSigSendType" SG_ 2549088270 BCM1_Transport_Mode 0;
BA_ "GenSigSwitchedByIgnition" SG_ 2549088270 BCM1_Transport_Mode 0;
BA_ "GenSigSendType" SG_ 2549088270 KN_BCM1_BusKnockOut 0;
BA_ "GenSigSwitchedByIgnition" SG_ 2549088270 KN_BCM1_BusKnockOut 0;
BA_ "GenSigSendType" SG_ 2549088270 KN_BCM1_BusKnockOutTimer 0;
BA_ "GenSigSwitchedByIgnition" SG_ 2549088270 KN_BCM1_BusKnockOutTimer 0;
BA_ "GenSigSendType" SG_ 2549088270 KN_BCM1_DiagPfad 0;
BA_ "GenSigSwitchedByIgnition" SG_ 2549088270 KN_BCM1_DiagPfad 0;
BA_ "GenSigSendType" SG_ 2549088270 KN_BCM1_ECUKnockOut 0;
BA_ "GenSigSwitchedByIgnition" SG_ 2549088270 KN_BCM1_ECUKnockOut 0;
BA_ "GenSigSendType" SG_ 2549088270 KN_BCM1_ECUKnockOutTimer 0;
BA_ "GenSigSwitchedByIgnition" SG_ 2549088270 KN_BCM1_ECUKnockOutTimer 0;
BA_ "GenSigSendType" SG_ 2549088270 NM_BCM1_Lokalaktiv 0;
BA_ "GenSigSwitchedByIgnition" SG_ 2549088270 NM_BCM1_Lokalaktiv 0;
BA_ "GenSigSendType" SG_ 2549088270 NM_BCM1_Subsystemaktiv 0;
BA_ "GenSigSwitchedByIgnition" SG_ 2549088270 NM_BCM1_Subsystemaktiv 0;
BA_ "GenSigSendType" SG_ 2549088270 NM_BCM1_Wakeup 0;
BA_ "NWM-WakeupAllowed" SG_ 2549088270 NM_BCM1_Wakeup 1;
BA_ "GenSigSwitchedByIgnition" SG_ 2549088270 NM_BCM1_Wakeup 0;
BA_ "GenSigSendType" SG_ 2549088272 Gateway_Abschaltstufe 0;
BA_ "GenSigSwitchedByIgnition" SG_ 2549088272 Gateway_Abschaltstufe 0;
BA_ "GenSigSendType" SG_ 2549088272 Gateway_KompSchutz 0;
BA_ "GenSigSwitchedByIgnition" SG_ 2549088272 Gateway_KompSchutz 0;
BA_ "GenSigSendType" SG_ 2549088272 Gateway_Nachlauftyp 0;
BA_ "GenSigStartValue" SG_ 2549088272 Gateway_Nachlauftyp 2;
BA_ "GenSigSwitchedByIgnition" SG_ 2549088272 Gateway_Nachlauftyp 0;
BA_ "GenSigSendType" SG_ 2549088272 Gateway_Transport_Mode 0;
BA_ "GenSigSwitchedByIgnition" SG_ 2549088272 Gateway_Transport_Mode 0;
BA_ "GenSigSendType" SG_ 2549088272 GW_KD_Fehler 0;
BA_ "GenSigSendType" SG_ 2549088272 KN_GW_DiagPfad 0;
BA_ "GenSigSwitchedByIgnition" SG_ 2549088272 KN_GW_DiagPfad 0;
BA_ "GenSigSendType" SG_ 2549088272 NM_Gateway_Wakeup 0;
BA_ "NWM-WakeupAllowed" SG_ 2549088272 NM_Gateway_Wakeup 1;
BA_ "GenSigSwitchedByIgnition" SG_ 2549088272 NM_Gateway_Wakeup 0;
BA_ "GenSigSendType" SG_ 2549088331 KN_TSG_BFS_BusKnockOutTimer 0;
BA_ "GenSigSwitchedByIgnition" SG_ 2549088331 KN_TSG_BFS_BusKnockOutTimer 0;
BA_ "GenSigSendType" SG_ 2549088331 KN_TSG_BFS_DiagPfad 0;
BA_ "GenSigSwitchedByIgnition" SG_ 2549088331 KN_TSG_BFS_DiagPfad 0;
BA_ "GenSigSendType" SG_ 2549088331 KN_TSG_BT_BusKnockOut 0;
BA_ "GenSigSwitchedByIgnition" SG_ 2549088331 KN_TSG_BT_BusKnockOut 0;
BA_ "GenSigSendType" SG_ 2549088331 KN_TSG_BT_ECUKnockOut 0;
BA_ "GenSigSwitchedByIgnition" SG_ 2549088331 KN_TSG_BT_ECUKnockOut 0;
BA_ "GenSigSendType" SG_ 2549088331 KN_TSG_BT_ECUKnockOutTimer 0;
BA_ "GenSigSwitchedByIgnition" SG_ 2549088331 KN_TSG_BT_ECUKnockOutTimer 0;
BA_ "GenSigSendType" SG_ 2549088331 NM_TSG_BFS_Lokalaktiv 0;
BA_ "GenSigSwitchedByIgnition" SG_ 2549088331 NM_TSG_BFS_Lokalaktiv 0;
BA_ "GenSigSendType" SG_ 2549088331 NM_TSG_BFS_Subsystemaktiv 0;
BA_ "GenSigSwitchedByIgnition" SG_ 2549088331 NM_TSG_BFS_Subsystemaktiv 0;
BA_ "GenSigSendType" SG_ 2549088331 NM_TSG_BFS_Wakeup 0;
BA_ "NWM-WakeupAllowed" SG_ 2549088331 NM_TSG_BFS_Wakeup 1;
BA_ "GenSigSwitchedByIgnition" SG_ 2549088331 NM_TSG_BFS_Wakeup 0;
BA_ "GenSigSendType" SG_ 2549088331 TSG_BFS_Abschaltstufe 0;
BA_ "GenSigSwitchedByIgnition" SG_ 2549088331 TSG_BFS_Abschaltstufe 0;
BA_ "GenSigSendType" SG_ 2549088331 TSG_BFS_KD_Fehler 0;
BA_ "GenSigSwitchedByIgnition" SG_ 2549088331 TSG_BFS_KD_Fehler 0;
BA_ "GenSigSendType" SG_ 2549088331 TSG_BFS_KompSchutz 0;
BA_ "GenSigSwitchedByIgnition" SG_ 2549088331 TSG_BFS_KompSchutz 0;
BA_ "GenSigSendType" SG_ 2549088331 TSG_BFS_Nachlauftyp 0;
BA_ "GenSigStartValue" SG_ 2549088331 TSG_BFS_Nachlauftyp 2;
BA_ "GenSigSwitchedByIgnition" SG_ 2549088331 TSG_BFS_Nachlauftyp 0;
BA_ "GenSigSendType" SG_ 2549088331 TSG_BFS_Transport_Mode 0;
BA_ "GenSigSwitchedByIgnition" SG_ 2549088331 TSG_BFS_Transport_Mode 0;
BA_ "GenSigSendType" SG_ 2549088330 KN_TSG_FS_BusKnockOutTimer 0;
BA_ "GenSigSwitchedByIgnition" SG_ 2549088330 KN_TSG_FS_BusKnockOutTimer 0;
BA_ "GenSigSendType" SG_ 2549088330 KN_TSG_FS_DiagPfad 0;
BA_ "GenSigSwitchedByIgnition" SG_ 2549088330 KN_TSG_FS_DiagPfad 0;
BA_ "GenSigSendType" SG_ 2549088330 KN_TSG_FT_BusKnockOut 0;
BA_ "GenSigSwitchedByIgnition" SG_ 2549088330 KN_TSG_FT_BusKnockOut 0;
BA_ "GenSigSendType" SG_ 2549088330 KN_TSG_FT_ECUKnockOut 0;
BA_ "GenSigSwitchedByIgnition" SG_ 2549088330 KN_TSG_FT_ECUKnockOut 0;
BA_ "GenSigSendType" SG_ 2549088330 KN_TSG_FT_ECUKnockOutTimer 0;
BA_ "GenSigSwitchedByIgnition" SG_ 2549088330 KN_TSG_FT_ECUKnockOutTimer 0;
BA_ "GenSigSendType" SG_ 2549088330 NM_TSG_FS_Lokalaktiv 0;
BA_ "GenSigSwitchedByIgnition" SG_ 2549088330 NM_TSG_FS_Lokalaktiv 0;
BA_ "GenSigSendType" SG_ 2549088330 NM_TSG_FS_Subsystemaktiv 0;
BA_ "GenSigSwitchedByIgnition" SG_ 2549088330 NM_TSG_FS_Subsystemaktiv 0;
BA_ "GenSigSendType" SG_ 2549088330 NM_TSG_FS_Wakeup 0;
BA_ "NWM-WakeupAllowed" SG_ 2549088330 NM_TSG_FS_Wakeup 1;
BA_ "GenSigSwitchedByIgnition" SG_ 2549088330 NM_TSG_FS_Wakeup 0;
BA_ "GenSigSendType" SG_ 2549088330 TSG_FS_Abschaltstufe 0;
BA_ "GenSigSwitchedByIgnition" SG_ 2549088330 TSG_FS_Abschaltstufe 0;
BA_ "GenSigSendType" SG_ 2549088330 TSG_FS_KD_Fehler 0;
BA_ "GenSigSwitchedByIgnition" SG_ 2549088330 TSG_FS_KD_Fehler 0;
BA_ "GenSigSendType" SG_ 2549088330 TSG_FS_KompSchutz 0;
BA_ "GenSigSwitchedByIgnition" SG_ 2549088330 TSG_FS_KompSchutz 0;
BA_ "GenSigSendType" SG_ 2549088330 TSG_FS_Nachlauftyp 0;
BA_ "GenSigStartValue" SG_ 2549088330 TSG_FS_Nachlauftyp 2;
BA_ "GenSigSwitchedByIgnition" SG_ 2549088330 TSG_FS_Nachlauftyp 0;
BA_ "GenSigSendType" SG_ 2549088330 TSG_FS_Transport_Mode 0;
BA_ "GenSigSwitchedByIgnition" SG_ 2549088330 TSG_FS_Transport_Mode 0;
BA_REL_ "GenSigTimeoutTime" BU_SG_REL_ BCM SG_ 2527679583 IPA_02_CRC 5000;
BA_REL_ "GenSigTimeoutTime" BU_SG_REL_ BCM SG_ 2527679583 IPA_02_BZ 5000;
BA_REL_ "GenSigTimeoutTime" BU_SG_REL_ BCM SG_ 2527679583 Parken_ZV_Schliessen 5000;
BA_REL_ "GenSigTimeoutTime" BU_SG_REL_ BCM SG_ 2527679583 Parken_aktives_System_02 5000;
BA_REL_ "GenSigTimeoutTime" BU_SG_REL_ BCM SG_ 2527679583 Parken_Schluesselsuche_Anf 5000;
BA_REL_ "GenSigTimeoutTime" BU_SG_REL_ BCM SG_ 2527679583 Parken_Lichtnachlauf_Anf 5000;
BA_REL_ "GenSigTimeoutTime" BU_SG_REL_ BCM SG_ 2527679583 Parken_Blinker_li_Anf 5000;
BA_REL_ "GenSigTimeoutTime" BU_SG_REL_ BCM SG_ 2527679583 Parken_Blinker_re_Anf 5000;
BA_REL_ "GenSigTimeoutTime" BU_SG_REL_ BCM SG_ 2527679583 Parken_Bestaetigungsblinken_Anf 5000;
BA_REL_ "GenSigTimeoutTime" BU_SG_REL_ BCM SG_ 2527679583 Parken_Lichtsteuerung_Anf 5000;
BA_REL_ "GenSigTimeoutTime" BU_SG_REL_ BCM SG_ 1646 KL_STL_aktiv 5000;
BA_REL_ "GenSigTimeoutTime" BU_SG_REL_ BCM SG_ 1646 KL_STH_aktiv 5000;
BA_REL_ "GenSigTimeoutTime" BU_SG_REL_ BCM SG_ 1646 KL_Geblaese_Fond_Status 5000;
BA_REL_ "GenSigTimeoutTime" BU_SG_REL_ BCM SG_ 1646 KL_Geblaese_Status 5000;
BA_REL_ "GenSigTimeoutTime" BU_SG_REL_ BCM SG_ 1646 KL_Restwaerme_aktiv 5000;
BA_REL_ "GenSigTimeoutTime" BU_SG_REL_ BCM SG_ 1646 KL_ErwVK_Anf 5000;
BA_REL_ "GenSigTimeoutTime" BU_SG_REL_ BCM SG_ 1646 KL_SIH_LEL_Verteilung_VL 5000;
BA_REL_ "GenSigTimeoutTime" BU_SG_REL_ BCM SG_ 1646 KL_SIH_LEL_Verteilung_VR 5000;
BA_REL_ "GenSigTimeoutTime" BU_SG_REL_ BCM SG_ 1640 KL_LRH_Taster 2000;
BA_REL_ "GenSigTimeoutTime" BU_SG_REL_ BCM SG_ 1640 KL_LRH_Stufe 2000;
BA_REL_ "GenSigTimeoutTime" BU_SG_REL_ BCM SG_ 1640 KRH_Soll_li 2000;
BA_REL_ "GenSigTimeoutTime" BU_SG_REL_ BCM SG_ 1640 KRH_Soll_re 2000;
BA_REL_ "GenSigTimeoutTime" BU_SG_REL_ BCM SG_ 1640 KL_Geblspng_Soll 2000;
BA_REL_ "GenSigTimeoutTime" BU_SG_REL_ BCM SG_ 1640 KL_Geblspng_Fond_Soll 2000;
BA_REL_ "GenSigTimeoutTime" BU_SG_REL_ BCM SG_ 2527679635 KL_AL_VR_Anf 5000;
BA_REL_ "GenSigTimeoutTime" BU_SG_REL_ BCM SG_ 2527679635 KL_AL_VL_Anf 5000;
BA_REL_ "GenSigTimeoutTime" BU_SG_REL_ BCM SG_ 2527679635 KL_AL_HR_Anf 5000;
BA_REL_ "GenSigTimeoutTime" BU_SG_REL_ BCM SG_ 2527679635 KL_AL_HL_Anf 5000;
BA_REL_ "GenSigTimeoutTime" BU_SG_REL_ BCM SG_ 2527679635 KL_VoKo_LED 5000;
BA_REL_ "GenSigTimeoutTime" BU_SG_REL_ BCM SG_ 2527679635 KL_Defrost_LED 5000;
BA_REL_ "GenSigTimeoutTime" BU_SG_REL_ BCM SG_ 2527679635 KL_HSH_LED 5000;
BA_REL_ "GenSigTimeoutTime" BU_SG_REL_ BCM SG_ 2527679635 HSH_Relais_Anf 5000;
BA_REL_ "GenSigTimeoutTime" BU_SG_REL_ BCM SG_ 2527679635 KL_FSH_LED 5000;
BA_REL_ "GenSigTimeoutTime" BU_SG_REL_ BCM SG_ 605 KLR_01_CRC 600;
BA_REL_ "GenSigTimeoutTime" BU_SG_REL_ BCM SG_ 605 KLR_01_BZ 600;
BA_REL_ "GenSigTimeoutTime" BU_SG_REL_ BCM SG_ 605 KLR_Touchauswertung 600;
BA_REL_ "GenSigTimeoutTime" BU_SG_REL_ Gateway_Max SG_ 1426 KY_StartStopp_Info 2000;
BA_REL_ "GenSigTimeoutTime" BU_SG_REL_ Gateway_Max SG_ 2463978753 Klemmen_Status_02_CRC 5000;
BA_REL_ "GenSigTimeoutTime" BU_SG_REL_ Gateway_Max SG_ 2463978753 Klemmen_Status_02_BZ 5000;
BA_REL_ "GenSigTimeoutTime" BU_SG_REL_ Gateway_Max SG_ 2463978753 KST_Sonderzustand_Status 5000;
BA_REL_ "GenSigTimeoutTime" BU_SG_REL_ Gateway_Max SG_ 2463978753 KST_Sonderzustand_Anforderung 5000;
BA_REL_ "GenSigTimeoutTime" BU_SG_REL_ Gateway_Max SG_ 960 Klemmen_Status_01_CRC 1000;
BA_REL_ "GenSigTimeoutTime" BU_SG_REL_ Gateway_Max SG_ 960 Klemmen_Status_01_BZ 1000;
BA_REL_ "GenSigTimeoutTime" BU_SG_REL_ Gateway_Max SG_ 960 ZAS_Kl_S 1000;
BA_REL_ "GenSigTimeoutTime" BU_SG_REL_ Gateway_Max SG_ 960 ZAS_Kl_15 1000;
BA_REL_ "GenSigTimeoutTime" BU_SG_REL_ Gateway_Max SG_ 1420 KST_Anf_Klemme_15 5000;
BA_REL_ "GenSigTimeoutTime" BU_SG_REL_ Gateway_Max SG_ 1505 BCM1_Aussen_Temp_ungef 2000;
BA_REL_ "GenSigTimeoutTime" BU_SG_REL_ Gateway_Max SG_ 2549088270 BCM1_Nachlauftyp 5000;
BA_REL_ "GenSigTimeoutTime" BU_SG_REL_ Gateway_Max SG_ 2549088270 KN_BCM1_DiagPfad 5000;
BA_REL_ "GenSigTimeoutTime" BU_SG_REL_ Gateway_Max SG_ 2549088270 BCM1_KD_Fehler 2500;
BA_REL_ "GenSigTimeoutTime" BU_SG_REL_ Gateway_Max SG_ 2549088331 TSG_BFS_Nachlauftyp 5000;
BA_REL_ "GenSigTimeoutTime" BU_SG_REL_ Gateway_Max SG_ 2549088331 KN_TSG_BFS_DiagPfad 5000;
BA_REL_ "GenSigTimeoutTime" BU_SG_REL_ Gateway_Max SG_ 2549088331 TSG_BFS_KD_Fehler 2500;
BA_REL_ "GenSigTimeoutTime" BU_SG_REL_ Gateway_Max SG_ 2549088330 TSG_FS_Nachlauftyp 5000;
BA_REL_ "GenSigTimeoutTime" BU_SG_REL_ Gateway_Max SG_ 2549088330 KN_TSG_FS_DiagPfad 5000;
BA_REL_ "GenSigTimeoutTime" BU_SG_REL_ Gateway_Max SG_ 2549088330 TSG_FS_KD_Fehler 2500;
BA_REL_ "GenSigTimeoutTime" BU_SG_REL_ TSGGen3_BFS SG_ 1524 IL_Klemme_30G_aktiv 5000;
BA_REL_ "GenSigTimeoutTime" BU_SG_REL_ TSGGen3_BFS SG_ 2463978753 KST_Sonderzustand_Status 5000;
BA_REL_ "GenSigTimeoutTime" BU_SG_REL_ TSGGen3_BFS SG_ 2463978753 KST_Sonderzustand_Anforderung 5000;
BA_REL_ "GenSigTimeoutTime" BU_SG_REL_ TSGGen3_BFS SG_ 960 ZAS_Kl_S 1000;
BA_REL_ "GenSigTimeoutTime" BU_SG_REL_ TSGGen3_BFS SG_ 960 ZAS_Kl_15 1000;
BA_REL_ "GenSigTimeoutTime" BU_SG_REL_ TSGGen3_BFS SG_ 960 ZAS_Kl_X 1000;
BA_REL_ "GenSigTimeoutTime" BU_SG_REL_ TSGGen3_BFS SG_ 960 ZAS_Kl_50_Startanforderung 1000;
BA_REL_ "GenSigTimeoutTime" BU_SG_REL_ TSGGen3_BFS SG_ 960 BCM_Remotestart_Betrieb 1000;
BA_REL_ "GenSigTimeoutTime" BU_SG_REL_ TSGGen3_BFS SG_ 1646 KL_ErwVK_Anf 5000;
BA_REL_ "GenSigTimeoutTime" BU_SG_REL_ TSGGen3_BFS SG_ 1646 KL_Innen_Temp 5000;
BA_REL_ "GenSigTimeoutTime" BU_SG_REL_ TSGGen3_BFS SG_ 1646 KL_Anf_AussenspiegelHzg 5000;
BA_REL_ "GenSigTimeoutTime" BU_SG_REL_ TSGGen3_BFS SG_ 1505 BCM1_Aussen_Temp_ungef 2000;
BA_REL_ "GenSigTimeoutTime" BU_SG_REL_ TSGGen3_BFS SG_ 1505 BCM1_FStatus_Aussentemp_ungef 2000;
BA_REL_ "GenSigTimeoutTime" BU_SG_REL_ TSGGen3_FS SG_ 1524 IL_Klemme_30G_aktiv 5000;
BA_REL_ "GenSigTimeoutTime" BU_SG_REL_ TSGGen3_FS SG_ 2463978753 KST_Sonderzustand_Status 5000;
BA_REL_ "GenSigTimeoutTime" BU_SG_REL_ TSGGen3_FS SG_ 2463978753 KST_Sonderzustand_Anforderung 5000;
BA_REL_ "GenSigTimeoutTime" BU_SG_REL_ TSGGen3_FS SG_ 960 ZAS_Kl_S 1000;
BA_REL_ "GenSigTimeoutTime" BU_SG_REL_ TSGGen3_FS SG_ 960 ZAS_Kl_15 1000;
BA_REL_ "GenSigTimeoutTime" BU_SG_REL_ TSGGen3_FS SG_ 960 ZAS_Kl_X 1000;
BA_REL_ "GenSigTimeoutTime" BU_SG_REL_ TSGGen3_FS SG_ 960 ZAS_Kl_50_Startanforderung 1000;
BA_REL_ "GenSigTimeoutTime" BU_SG_REL_ TSGGen3_FS SG_ 960 BCM_Remotestart_Betrieb 1000;
BA_REL_ "GenSigTimeoutTime" BU_SG_REL_ TSGGen3_FS SG_ 1646 KL_STH_aktiv 5000;
BA_REL_ "GenSigTimeoutTime" BU_SG_REL_ TSGGen3_FS SG_ 1646 KL_ErwVK_Anf 5000;
BA_REL_ "GenSigTimeoutTime" BU_SG_REL_ TSGGen3_FS SG_ 1646 KL_Innen_Temp 5000;
BA_REL_ "GenSigTimeoutTime" BU_SG_REL_ TSGGen3_FS SG_ 1646 KL_Anf_AussenspiegelHzg 5000;
BA_REL_ "GenSigTimeoutTime" BU_SG_REL_ TSGGen3_FS SG_ 1505 BCM1_Aussen_Temp_ungef 2000;
BA_REL_ "GenSigTimeoutTime" BU_SG_REL_ TSGGen3_FS SG_ 1505 BCM1_FStatus_Aussentemp_ungef 2000;
BA_REL_ "GenSigTimeoutTime" BU_SG_REL_ TSGGen3_HBFS SG_ 1524 IL_Klemme_30G_aktiv 5000;
BA_REL_ "GenSigTimeoutTime" BU_SG_REL_ TSGGen3_HBFS SG_ 2463978753 KST_Sonderzustand_Status 5000;
BA_REL_ "GenSigTimeoutTime" BU_SG_REL_ TSGGen3_HBFS SG_ 2463978753 KST_Sonderzustand_Anforderung 5000;
BA_REL_ "GenSigTimeoutTime" BU_SG_REL_ TSGGen3_HBFS SG_ 960 ZAS_Kl_S 1000;
BA_REL_ "GenSigTimeoutTime" BU_SG_REL_ TSGGen3_HBFS SG_ 960 ZAS_Kl_15 1000;
BA_REL_ "GenSigTimeoutTime" BU_SG_REL_ TSGGen3_HBFS SG_ 960 ZAS_Kl_X 1000;
BA_REL_ "GenSigTimeoutTime" BU_SG_REL_ TSGGen3_HBFS SG_ 960 ZAS_Kl_50_Startanforderung 1000;
BA_REL_ "GenSigTimeoutTime" BU_SG_REL_ TSGGen3_HBFS SG_ 1646 KL_ErwVK_Anf 5000;
BA_REL_ "GenSigTimeoutTime" BU_SG_REL_ TSGGen3_HBFS SG_ 1646 KL_Innen_Temp 5000;
BA_REL_ "GenSigTimeoutTime" BU_SG_REL_ TSGGen3_HBFS SG_ 1505 BCM1_Aussen_Temp_ungef 2000;
BA_REL_ "GenSigTimeoutTime" BU_SG_REL_ TSGGen3_HBFS SG_ 1505 BCM1_FStatus_Aussentemp_ungef 2000;
BA_REL_ "GenSigTimeoutTime" BU_SG_REL_ TSGGen3_HFS SG_ 1524 IL_Klemme_30G_aktiv 5000;
BA_REL_ "GenSigTimeoutTime" BU_SG_REL_ TSGGen3_HFS SG_ 2463978753 KST_Sonderzustand_Status 5000;
BA_REL_ "GenSigTimeoutTime" BU_SG_REL_ TSGGen3_HFS SG_ 2463978753 KST_Sonderzustand_Anforderung 5000;
BA_REL_ "GenSigTimeoutTime" BU_SG_REL_ TSGGen3_HFS SG_ 960 ZAS_Kl_S 1000;
BA_REL_ "GenSigTimeoutTime" BU_SG_REL_ TSGGen3_HFS SG_ 960 ZAS_Kl_15 1000;
BA_REL_ "GenSigTimeoutTime" BU_SG_REL_ TSGGen3_HFS SG_ 960 ZAS_Kl_X 1000;
BA_REL_ "GenSigTimeoutTime" BU_SG_REL_ TSGGen3_HFS SG_ 960 ZAS_Kl_50_Startanforderung 1000;
BA_REL_ "GenSigTimeoutTime" BU_SG_REL_ TSGGen3_HFS SG_ 1646 KL_ErwVK_Anf 5000;
BA_REL_ "GenSigTimeoutTime" BU_SG_REL_ TSGGen3_HFS SG_ 1646 KL_Innen_Temp 5000;
BA_REL_ "GenSigTimeoutTime" BU_SG_REL_ TSGGen3_HFS SG_ 1505 BCM1_Aussen_Temp_ungef 2000;
BA_REL_ "GenSigTimeoutTime" BU_SG_REL_ TSGGen3_HFS SG_ 1505 BCM1_FStatus_Aussentemp_ungef 2000;
BA_REL_ "GenSigTimeoutTime" BU_SG_REL_ WLC_01_CFD SG_ 960 ZAS_Kl_S 1000;
BA_REL_ "GenSigTimeoutTime" BU_SG_REL_ WLC_01_CFD SG_ 960 ZAS_Kl_15 1000;
BA_REL_ "GenSigTimeoutTime" BU_SG_REL_ WLC_01_CFD SG_ 1646 KL_Geblaese_Status 5000;
BA_REL_ "GenSigTimeoutTime" BU_SG_REL_ WLC_01_CFD SG_ 1646 KL_Innen_Temp 5000;
VAL_ 1524 IL_Bel_FS_Ausstieg 0 "inaktiv" 1 "aktiv" ;
VAL_ 1524 IL_Bel_BFS_Ausstieg 0 "inaktiv" 1 "aktiv" ;
VAL_ 1524 IL_Bel_HFS_Ausstieg 0 "inaktiv" 1 "aktiv" ;
VAL_ 1524 IL_Bel_HBFS_Ausstieg 0 "inaktiv" 1 "aktiv" ;
VAL_ 1524 BCM1_Innenlicht_gedimmt_V 0 "100% Innenlicht" 1 "gedimmtes Innenlicht" ;
VAL_ 1524 BCM1_Innenlicht_gedimmt_H 0 "100% Innenlicht" 1 "gedimmtes Innenlicht" ;
VAL_ 1524 IL_Innenlicht_aktiv 0 "Innenlicht inaktiv" 1 "Innenlicht aktiv" ;
VAL_ 1524 IL_Klemme_30G_aktiv 0 "Kl_30G_abgeschaltet" 1 "eingeschaltet" ;
VAL_ 1524 BCM1_DI_Rampe_Innenlicht 0 "Dimmrampe 0" 1 "Dimmrampe 1" ;
VAL_ 1524 BCM1_DI_Rampe_Leselicht 0 "Dimmrampe 0" 1 "Dimmrampe 1" ;
VAL_ 1524 BCM1_Innenlicht_H 0 "Aus" 1 "Ein" ;
VAL_ 1524 BCM1_Innenlicht_V 0 "Aus" 1 "Ein" ;
VAL_ 1524 BCM1_Leselicht_Anf_hl 0 "Aus" 1 "Ein" ;
VAL_ 1524 BCM1_Leselicht_Anf_hr 0 "Aus" 1 "Ein" ;
VAL_ 1524 BCM1_Leselicht_Anf_vl 0 "Aus" 1 "Ein" ;
VAL_ 1524 BCM1_Leselicht_Anf_vr 0 "Aus" 1 "Ein" ;
VAL_ 1524 BCM1_Leuchten_Aus 0 "keine Aenderung" 1 "Aus" ;
VAL_ 1524 AMB_Charisma_FahrPr 0 "keine_Funktion" 1 "Programm_1" 2 "Programm_2" 3 "Programm_3" 4 "Programm_4" 5 "Programm_5" 6 "Programm_6" 7 "Programm_7" 8 "Programm_8" 9 "Programm_9" 10 "Programm_10" 11 "Programm_11" 12 "Programm_12" 13 "Programm_13" 14 "Programm_14" 15 "Programm_15" ;
VAL_ 1524 AMB_Charisma_Status 0 "Init" 1 "verfuegbar" 2 "nicht_verfuegbar" 3 "asynchron_durch_Fahrerwunsch" ;
VAL_ 2527679583 IPA_PL_Anzeige_links 0 "keine_PL_erkannt" 1 "links_Quer" 2 "links_Laengs" 3 "reserviert" ;
VAL_ 2527679583 IPA_PL_Anzeige_rechts 0 "keine_PL_erkannt" 1 "rechts_Quer" 2 "rechts_Laengs" 3 "reserviert" ;
VAL_ 2527679583 Parken_Seitenspiegel_Anf 0 "Keine_Anforderung" 1 "Seitenspiegel_anklappen" 2 "Seitenspiegel_abklappen" ;
VAL_ 2527679583 Parken_ZV_Schliessen 0 "Keine_Anforderung" 1 "ZV_verriegeln" 2 "ZV_safen" ;
VAL_ 2527679583 Parken_aktives_System_02 0 "Init" 1 "Keine_Aktivitaet" 2 "RPA" 3 "IPA" 4 "MA" 5 "TP" 6 "rTP" 7 "AAA" 8 "rAAA" 9 "ARA_1" 10 "PLA" 11 "RBF" 12 "PHP" 13 "RA" ;
VAL_ 2527679583 Parken_ZR_Sondermodus_Anf 0 "Init" 1 "Keine_Anforderung" 2 "Anforderung_Sondermodus" ;
VAL_ 2527679583 Parken_Schluesselsuche_Anf 0 "keine_Anforderung" 1 "Anforderung_Schluesselsuche" ;
VAL_ 2527679583 Parken_FFB_LED_Anf 0 "keine_Anforderung" 1 "Abbruch_Fehler" 2 "Bereit_OK" 3 "Beendet" ;
VAL_ 2527679583 Parken_Wegfahrsperren_Anf 0 "keine_Anforderung" 1 "Anforderung_Fahreruebernahme" 2 "Anforderung_Fahreruebergabe" ;
VAL_ 2527679583 Parken_Aktivierungslicht_Anf 0 "keine_Anforderung" 1 "Aktivierungslicht" ;
VAL_ 2527679583 Parken_Fahrtrichtungslicht_Anf 0 "keine_Anforderung" 1 "Vorwaerts" 2 "Rueckwaerts" ;
VAL_ 2527679583 Parken_Lichtnachlauf_Anf 0 "keine_Anforderung" 1 "Anforderung_Lichtnachlauf" ;
VAL_ 2527679583 IPA_Akustik_PL_gefunden 0 "keinen_Ton_ausgeben" 1 "Ton_ausgeben" ;
VAL_ 2527679583 Parken_Blinker_li_Anf 0 "keine_Anforderung" 1 "Blinker_links_aktivieren" ;
VAL_ 2527679583 Parken_Blinker_re_Anf 0 "keine_Anforderung" 1 "Blinker_rechts_aktivieren" ;
VAL_ 2527679583 Parken_Fahrerhinweise_Anf 0 "keine_Anforderung" 1 "Fahrerhinweise_anzeigen" ;
VAL_ 2527679583 Parken_Bestaetigungsblinken_Anf 0 "keine_Anforderung" 1 "Erfolgsblinken_Einparken" 2 "Abbruchsblinken" 3 "Erfolgsblinken_Ausparken" ;
VAL_ 2527679583 Parken_Fahrbereitschaftlicht_Anf 0 "keine_Anforderung" 1 "Fahrbereitschaftslicht" ;
VAL_ 2527679583 Parken_Lichtsteuerung_Anf 0 "keine_Anforderung" 1 "Automatik_Lichtmodus_aktivieren" ;
VAL_ 2527679583 IPA_Anf_Meldungen 0 "keine Meldung" 1 "beendet" 2 "Fahrinf_Bremse_FT_betaetigen" 3 "Suche_fortsetzen_ESC_Eingriff" 4 "n_a_temp_ESC_deaktiviert" 5 "n_a_temp_Anhaengerbetrieb" 6 "Suche_Zeitlimit_ueberschritten" 7 "Undefined" 8 "Fahrinf_PaLueSu_aufschalten" 9 "RPARemoteWunschAbgebrochen" 10 "IPAGeschwindigkeitReduzieren" 11 "IPARPAAktivierung2" 12 "AP_nicht_moeglich" 13 "RPAGarageStart" 14 "n_a_temp_Tuer_Heckklappe_offen" 15 "Stby_Tuer_Heckklappe_schliessen" 16 "PP_aktiv_nur_aussen_bedienbar" 17 "RPAUebergabe2" 18 "n_a_Offroad_Modus" 19 "PP_Schluessel_oder_App_bedienen" 20 "RPAUebergabe1" 21 "PP_Schluessel_bedienen" 22 "IPAAbbruchSuchfahrt" 23 "Systemstoerung_Service" 24 "n_a_temp_Sensorsicht" 25 "IPAAbbruchSuchfahrtLadestecke" 26 "IPAPausierenWeiterfahrt" 27 "n_a_temp_FAS_aktiv" 28 "PP_BT_unterbrochen" 29 "Hindernis_in_Fahrtrichtung" 30 "IPAAusparkenBlinker" 31 "RPAUebernahme" 32 "Suche_Rangierflaeche_zu_klein" 33 "n_a_temp_Drive_Select" 34 "IPAAktivierung1" 35 "Fahrinf_Fahrtrichtungswechsel" 36 "RPARemoteWunsch" 37 "GP_Fzgposition_vor_Garage" 38 "GP_RT_Garage_oeffnen" 39 "GP_Kein_Zuparken" 40 "Suche_Fahrinfo_beachten" 41 "GP_Fzgposition_freie_Parkflaeche" 42 "GP_n_a_temp_Laser" 43 "Geschwindigkeitsueberschreitung" 44 "Fahrinf_Weiter_vorfahren" 45 "RPAAktivierung1" 46 "Fahrinf_Anhalten" 47 "GP_AP_nicht_moeglich_Fahrweg" 48 "PP_Gang_Schluesselauthentifizier" 49 "Fahrhinweis_FT_betaetigen" 50 "PP_aktiv_Hinweis_FUEN" 128 "Disclaimer_LP_rechts" 129 "Disclaimer_LP_links" 130 "Disclaimer_RQ_rechts" 131 "Disclaimer_RQ_links" 132 "Disclaimer_VQ_rechts" 133 "Disclaimer_VQ_links" 134 "Disclaimer_AP_rechts" 135 "Disclaimer_AP_links" 136 "IPARPAAktivierung3" 137 "IPAAbbruchLenkeingriff" 138 "IPAAbbruchAnhaenger" 139 "IPARPAAktivierung4" 140 "IPAAbbruchZeitlimit" 141 "IPAFahrzeugAusgeparkt" 142 "IPAFahrzeugEingeparkt" 143 "IPAPausieren" 144 "IPAAbbruchESC" 145 "Stby_Verkehr_erkannt" 146 "MAAbbruchLenkeingriff" 147 "IPAAbbruchSchaltung" 148 "IPAAbbruchParklueckeKlein" 149 "IPABordsteinheber2" 150 "IPAAbbruchSensorsicht" 151 "Beendet_Stoerung_Fzgverbindung" 152 "Beendet_selbst_bremsen" 153 "IPAAbbruchFahrdynamischerEing" 154 "IPAAbbruchFalscheBewegungsric" 155 "IPAAbbruchDiETaSchliesskreuz" 156 "IPAPausierenHindernis" 157 "FUEN_moeglich" 158 "IPABordsteinheber4" 159 "IPAAbbruchOffroadModus" 160 "IPABordsteinheber5" 161 "PP_Fehler_Schluesselautorisier" 162 "IPABordsteinheber6" 163 "IPABordsteinheber7" 164 "Stby_FT_oder_RT_betaetigen" 165 "Stby_Hindernis_Richtungswechsel" 166 "Stby_erhoehter_Fahrwiderstand" 167 "Abbruch_EPB_aktiviert" 168 "Abbruch_MO_nicht_bereit" 169 "IPAAbbruchPDC" 170 "Abbruch_Gurtschloss_gesteckt" 171 "IPAAbbruchGeschwindigkeitHoch" 172 "IPAPausierenTueren" 173 "IPAAbbruchNotstopp" 174 "IPAAbbruchFahrerabwesenheit" 175 "IPAAbbruchSystempartner" 176 "PosOK_Lenkrad_loslassen_Bremse" 177 "PosOK_Lenkrad_loslassen_FT" 178 "Wiederaufnahme_FT_betaetigen" 179 "IPABordsteinheber9" 180 "IPAAbbruchKlemme15Aus" 181 "IPABordsteinheber8" 192 "TPA_aborted_deviated_from_trajec" 193 "TPA_aborted_limited_visibility" 194 "TPA_aborted_localization_failure" 195 "TPA_aborted_System_error" 196 "TPA_aborted_TPA_canceled" 197 "TPA_unavlbl_localization_failure" 198 "TPA_unavlbl_limited_visibility" 199 "TPA_unavlbl_System_error" 200 "TPA_temp_unavailable" 201 "rTPA_nicht_verfuegbar_TPA_bis_ZP" 202 "TPA_PP_belegt_TPA_Altern" 203 "TPA_PP_belegt_IPA_0_Altern" 204 "TPA_PP_belegt_IPA_1_Altern" 205 "TPA_PP_belegt_IPA_mehr_Altern" 206 "TPA_ausgerichtetes_Parken_aktiv" 207 "TPA_Ausparken_eingeschraenkt" ;
VAL_ 1425 KY_Gesamt_Entr 0 "inaktiv" 1 "aktiv" ;
VAL_ 1425 KY_FS_Entr 0 "inaktiv" 1 "aktiv" ;
VAL_ 1425 KY_BFS_Entr 0 "inaktiv" 1 "aktiv" ;
VAL_ 1425 KY_HFS_Entr 0 "inaktiv" 1 "aktiv" ;
VAL_ 1425 KY_HBFS_Entr 0 "inaktiv" 1 "aktiv" ;
VAL_ 1425 KY_HD_Entr 0 "inaktiv" 1 "aktiv" ;
VAL_ 1425 KY_HS_Entr 0 "inaktiv" 1 "aktiv" ;
VAL_ 1425 KY_Schliessverh_HD 0 "inaktiv" 1 "aktiv" ;
VAL_ 1425 KY_Bdraten_Rueckspr 0 "inaktiv" 1 "aktiv" ;
VAL_ 1425 KY_Entry_ETuer_HFS 0 "inaktiv" 1 "aktiv" ;
VAL_ 1425 KY_Entry_ETuer_HBFS 0 "inaktiv" 1 "aktiv" ;
VAL_ 1425 KY_VirtuellesPedal_HK 0 "Aus" 1 "Ein" ;
VAL_ 1425 KY_3_Bremslicht_Ein 0 "Aus" 1 "Ein" ;
VAL_ 1426 KY_ID_Geber1_im_Fzg 0 "inaktiv" 1 "aktiv" ;
VAL_ 1426 KY_ID_Geber2_im_Fzg 0 "inaktiv" 1 "aktiv" ;
VAL_ 1426 KY_ID_Geber3_im_Fzg 0 "inaktiv" 1 "aktiv" ;
VAL_ 1426 KY_ID_Geber4_im_Fzg 0 "inaktiv" 1 "aktiv" ;
VAL_ 1426 KY_Startknopf_Bel 0 "inaktiv" 1 "aktiv" ;
VAL_ 1426 KY_ID_Geber_Suche 0 "inaktiv" 1 "aktiv" ;
VAL_ 1426 KY_Meldungen 0 "keine_Meldung" 1 "Schluessel_nicht_gefunden" 2 "Schluessel_im_Kofferraum" 3 "Schluessel_im_Fahrzeug" 4 "Kessy_defekt" ;
VAL_ 1426 KY_Gong_600 0 "inaktiv" 1 "aktiv" ;
VAL_ 1426 KY_Passiv_Autolock_Menue 0 "inaktiv" 1 "aktiv" ;
VAL_ 1426 KY_Passiv_Autolock_Akt 0 "inaktiv" 1 "aktiv" ;
VAL_ 1426 KY_Passiv_Autolock 0 "inaktiv" 1 "aktiv" ;
VAL_ 1426 KY_Passiv_Autounlock 0 "inaktiv" 1 "aktiv" ;
VAL_ 1426 KY_Gestik_HD 0 "inaktiv" 1 "aktiv" ;
VAL_ 1426 KY_StartStopp_Info 0 "Motorlauf_nicht_notwendig_(Stoppfreigabe)" 1 "Motoranlauf_nicht_zwingend_notwendig_(Stoppverbot,keine_Startanforderung)" 2 "Motoranlauf_zwingend_notwendig_(Startanforderung)" 3 "Systemfehler" ;
VAL_ 1426 KY_Fzg_Verlassen_erkannt 0 "nicht_erkannt" 1 "erkannt" ;
VAL_ 1426 KY_Fzg_Zugang_erkannt 0 "nicht_erkannt" 1 "erkannt" ;
VAL_ 1426 KY_EasyClose_Abbruch 0 "EasyClose_kein_Abbruch" 1 "EasyClose_Abbruch" ;
VAL_ 1426 KY_EasyClose_Status 0 "Lampe_AUS" 1 "Lampe_EIN" 2 "Lampe_NORMAL" 3 "Lampe_HEKTIK" 4 "Akustik_Verweigerung" ;
VAL_ 1426 KY_HD_Auffahrt 0 "keine_Anforderung" 1 "HD_Auffahrt_angefordert" ;
VAL_ 1426 KY_HD_Zufahrt 0 "keine_Anforderung" 1 "HD_Zufahrt_angefordert" ;
VAL_ 1426 KY_Aktive_LFScans 0 "Init" 1 "Entry_Exit_Scan_1" 2 "Entry_Exit_Scan_2" 3 "GO_Scan_1" 4 "GO_Scan_2" 5 "Keyminder_Scan" 6 "ServiceKey1_Scan" 7 "ServiceKey2_Scan" 8 "Komfortlauf_RW_Begrenzer" 9 "Komfortlauf_RW_Begrenzer_EHeck" 10 "RSSI_Scan_EasyClose" 11 "PU_Scan" 12 "Diagnose_Scan" ;
VAL_ 1426 KY_LF_Aktiv 0 "Funktempfang_nicht_aktiv" 1 "LF_Funkempfang_aktiv" ;
VAL_ 1426 KY_AnzKoord_Info 0 "Init" 1 "Keyminder_Suche_erfolgreich" 2 "Keyminder_Suche_negativ" ;
VAL_ 1426 KY_Schluesselposition_9 0 "nicht_gefunden" 1 "im_Innenraum_gefunden" 2 "im_Aussenraum_gefunden_nah" 3 "im_Aussenraum_gefunden_fern" ;
VAL_ 1426 KY_Schluesselposition_1 0 "nicht_gefunden" 1 "im_Innenraum_gefunden" 2 "im_Aussenraum_gefunden_nah" 3 "im_Aussenraum_gefunden_fern" ;
VAL_ 1426 KY_Schluesselposition_2 0 "nicht_gefunden" 1 "im_Innenraum_gefunden" 2 "im_Aussenraum_gefunden_nah" 3 "im_Aussenraum_gefunden_fern" ;
VAL_ 1426 KY_Schluesselposition_3 0 "nicht_gefunden" 1 "im_Innenraum_gefunden" 2 "im_Aussenraum_gefunden_nah" 3 "im_Aussenraum_gefunden_fern" ;
VAL_ 1426 KY_Schluesselposition_4 0 "nicht_gefunden" 1 "im_Innenraum_gefunden" 2 "im_Aussenraum_gefunden_nah" 3 "im_Aussenraum_gefunden_fern" ;
VAL_ 1426 KY_Schluesselposition_5 0 "nicht_gefunden" 1 "im_Innenraum_gefunden" 2 "im_Aussenraum_gefunden_nah" 3 "im_Aussenraum_gefunden_fern" ;
VAL_ 1426 KY_Schluesselposition_6 0 "nicht_gefunden" 1 "im_Innenraum_gefunden" 2 "im_Aussenraum_gefunden_nah" 3 "im_Aussenraum_gefunden_fern" ;
VAL_ 1426 KY_Schluesselposition_7 0 "nicht_gefunden" 1 "im_Innenraum_gefunden" 2 "im_Aussenraum_gefunden_nah" 3 "im_Aussenraum_gefunden_fern" ;
VAL_ 1426 KY_Schluesselposition_8 0 "nicht_gefunden" 1 "im_Innenraum_gefunden" 2 "im_Aussenraum_gefunden_nah" 3 "im_Aussenraum_gefunden_fern" ;
VAL_ 960 RSt_Fahrerhinweise 0 "Init" 1 "Fahreruebernahme_Hinweis_ZAT_Automat_ohne_Gong" 2 "Fahreruebernahme_Hinweis_ZAT_Automat_mit_Gong" 3 "Fahreruebernahme_Hinweis_ZAT_Handschalter_ohne_Gong" 4 "Fahreruebernahme_Hinweis_ZAT_Handschalter_mit_Gong" 5 "Fahreruebernahme_Hinweis_ZAS_Automat_ohne_Gong" 6 "Fahreruebernahme_Hinweis_ZAS_Automat_mit_Gong" 7 "Fahreruebernahme_Hinweis_ZAS_Handschalter_ohne_Gong" 8 "Fahreruebernahme_Hinweis_ZAS_Handschalter_mit_Gong" 9 "RemoteStart_aktiv_ohne_Gong" 10 "RemoteStart_aktiv_mit_Gong" 11 "void" 12 "void" 13 "void" 14 "void" 15 "void" ;
VAL_ 960 ZAS_Kl_S 0 "aus" 1 "S_Kontakt_ein" ;
VAL_ 960 ZAS_Kl_15 0 "aus" 1 "ein" ;
VAL_ 960 ZAS_Kl_X 0 "aus" 1 "ein" ;
VAL_ 960 ZAS_Kl_50_Startanforderung 0 "aus" 1 "KL50_ein_Startwunsch_Fahrer" ;
VAL_ 960 BCM_Remotestart_Betrieb 0 "kein_RS_Betrieb" 1 "RS_Betrieb" ;
VAL_ 960 ZAS_Kl_Infotainment 0 "inaktiv" 1 "aktiv" ;
VAL_ 960 BCM_Remotestart_KL15_Anf 0 "inaktiv" 1 "aktiv" ;
VAL_ 960 BCM_Remotestart_MO_Start 0 "nicht_angefordert" 1 "angefordert" ;
VAL_ 960 KST_Warn_P1_ZST_def 0 "nicht_defekt" 1 "defekt" ;
VAL_ 960 KST_Warn_P2_ZST_def 0 "nicht_defekt" 1 "defekt" ;
VAL_ 960 KST_Fahrerhinweis_1 0 "inaktiv" 1 "aktiv" ;
VAL_ 960 KST_Fahrerhinweis_2 0 "inaktiv" 1 "aktiv" ;
VAL_ 960 BCM_Ausparken_Betrieb 0 "kein_Betrieb" 1 "Ausparkvorgang_aktiv" ;
VAL_ 960 KST_Fahrerhinweis_4 0 "inaktiv" 1 "aktiv" ;
VAL_ 960 KST_Fahrerhinweis_5 0 "inaktiv" 1 "aktiv" ;
VAL_ 960 KST_Fahrerhinweis_6 0 "inaktiv" 1 "aktiv" ;
VAL_ 2463978753 KST_WFS_Fahrfreigabe_Anforderung 0 "Keine" 1 "Uneingeschraenkt" 2 "Eingeschraenkt" ;
VAL_ 2463978753 KST_Sonderzustand_Status 0 "Init" 1 "Uebergang_neue_Anforderung" 2 "Aktiv" 3 "Fehler" ;
VAL_ 2463978753 KST_Sonderzustand_Anforderung 0 "Init" 1 "RemoteStart" 2 "RemoteParkAssist" 3 "IntelligentParkAssist" 4 "TrainiertesParken" 5 "OnlineRemoteUpdate" 6 "Einfrierschutz" 7 "Klemme15ViaDiagnose" 8 "RueckwandklappenSicherungPDC" 9 "ParkHausPilot" 10 "AnhaengerAnkuppelAssistent" 11 "MotorWeiterlaufSchaltung" 31 "Fehler" ;
VAL_ 2463978753 KST_ComfortReadyStatus 0 "aus" 1 "ComfortReadyStatus_ein" ;
VAL_ 2463978753 KST_Freigabe_Zustand 0 "Init" 1 "Kl50_freigegeben" 2 "Kl50_gesperrt" ;
VAL_ 1420 KST_Anf_Klemme_15 0 "nicht_angefordert" 1 "angefordert" ;
VAL_ 1420 KST_Anf_Klemme_50 0 "nicht_angefordert" 1 "angefordert" ;
VAL_ 1420 KST_Anf_Klemme_S 0 "nicht_angefordert" 1 "angefordert" ;
VAL_ 1420 KST_Txt_Werkstatt 0 "Aus" 1 "Ein" ;
VAL_ 1420 KST_Txt_P_Gang 0 "Aus" 1 "Ein" ;
VAL_ 1420 KST_Txt_Panikabschaltung 0 "Aus" 1 "Ein" ;
VAL_ 1420 KST_Anf_Klemmenfreigabe_ELV 0 "nicht_angefordert" 1 "angefordert" ;
VAL_ 1420 KST_Txt_Komfortabschaltung 0 "inaktiv" 1 "aktiv" ;
VAL_ 1420 KST_ZAT_betaetigt 0 "Aus" 1 "Ein" ;
VAL_ 1420 KST_Unterdr_Zuendungsmeldung 0 "keine_Unterdr_der_Zuendungsmeldung" 1 "Unterdr_der_Zuendungsmeldung_aktiv" ;
VAL_ 1420 KST_aut_Abschaltung_Zuendung 0 "Zuendung_wird_bei_Verl_nicht_deaktiviert" 1 "Zuendung_wird_bei_Verl_deaktiviert" ;
VAL_ 1420 KST_Anf_Klemmenfreigabe_WFS 0 "nicht_angefordert" 1 "angefordert" ;
VAL_ 1420 KST_Anf_ZV_Verriegelung 0 "inaktiv" 1 "aktiv" ;
VAL_ 1420 Relais_VoKo_angesteuert 0 "nicht_angesteuert" 1 "angesteuert" ;
VAL_ 1420 RSt_Anforderung_HMS 0 "keine_Anforderung" 1 "halten" 2 "parken" 3 "halten_Standby" 4 "anfahren" 5 "Loesen_ueber_Rampe" 6 "Parken_mit_P" ;
VAL_ 1420 KST_Zuendungswarnung 0 "keine_Ausgabe_Zuendungswarnung" 1 "Ausg_Zuendungswarnung_Stillstand" 2 "Ausg_Zuendungswarnung_Fahrt" 3 "reserved" ;
VAL_ 1420 KST_Anzeige_Klemmenzustand 0 "keine_Anzeige" 1 "Fehler_Infotainment" 2 "Update_in_progress" 3 "Fehler_Infotainment_Fzg_Gesperrt" ;
VAL_ 1646 KL_STL_aktiv 0 "Standlueftung_nicht_aktiv" 1 "Standlueftung_aktiv" ;
VAL_ 1646 KL_STH_aktiv 0 "Standheizung_nicht_aktiv" 1 "Standheizung_aktiv" ;
VAL_ 1646 KL_Solarluefter_aktiv 0 "Solarluefter_nicht_aktiv" 1 "Solarluefter_aktiv__auto" ;
VAL_ 1646 KL_Umluft_Taste 0 "Taste_nicht_gedrueckt" 1 "Taste_gedrueckt" ;
VAL_ 1646 KL_Geblaese_Fond_Status 0 "Geblaese_aus" 1 "Geblaesestufe_10" 2 "Geblaesestufe_20" 3 "Geblaesestufe_30" 4 "Geblaesestufe_40" 5 "Geblaesestufe_50" 6 "Geblaesestufe_60" 7 "Geblaesestufe_70" 8 "Geblaesestufe_80" 9 "Geblaesestufe_90" 10 "Geblaesestufe_100" 14 "Init" 15 "Fehler" ;
VAL_ 1646 KL_STH_Ansteuerung 0 "Aus" 1 "Ein" 2 "Ein_mit_Motorvorwaermung" 3 "Heizleistung_reduziert" ;
VAL_ 1646 KL_Magnetventil 0 "Aus" 1 "Ein" ;
VAL_ 1646 KL_WaPu 0 "Wasserpumpe_aus" 1 "Wasserpumpe_aktiv" ;
VAL_ 1646 KL_Geblaese_Status 0 "Geblaese_aus" 1 "Geblaesestufe_10" 2 "Geblaesestufe_20" 3 "Geblaesestufe_30" 4 "Geblaesestufe_40" 5 "Geblaesestufe_50" 6 "Geblaesestufe_60" 7 "Geblaesestufe_70" 8 "Geblaesestufe_80" 9 "Geblaesestufe_90" 10 "Geblaesestufe_100" 14 "Init" 15 "Fehler" ;
VAL_ 1646 KL_Restwaerme_aktiv 0 "inaktiv" 1 "aktiv" ;
VAL_ 1646 KL_Kompressorkupplung 0 "oeffnen" 1 "schliessen" ;
VAL_ 1646 KL_BCmE_Livetip_Freigabe 0 "Anzeige_Livetip_nicht_zulaessig" 1 "Anzeige_Livetip_zulaessig" ;
VAL_ 1646 KL_ErwVK_Anf 0 "nicht_angefordert" 1 "angefordert" ;
VAL_ 1646 KL_Innen_Temp 253 "nicht_verbaut" 254 "nicht_verfuegbar" 255 "Fehler" ;
VAL_ 1646 KL_I_Geblaese_Fond 255 "Fehler" ;
VAL_ 1646 KL_Anf_AussenspiegelHzg 0 "nicht_angefordert" 1 "angefordert" ;
VAL_ 1646 KL_Heizkreisventilstellung 0 "Init" 1 "Ventilstellung_gem_Anforderung" 2 "Ventilstellung_abweichend_Anf" 3 "Fehler" ;
VAL_ 1646 KL_FSH_Automatikbetrieb 0 "aus" 1 "angefordert_durch_Regelung" ;
VAL_ 1646 KL_SIH_LEH_Verteilung_VL 0 "gleichmaessige_Verteilung" 1 "Sitz_Prio_Hoch" 2 "Sitz_Prio_Mittel" 3 "Sitz_Prio_Niedrig" 4 "Lehne_Prio_Niedrig" 5 "Lehne_Prio_Mittel" 6 "Lehne_Prio_Hoch" ;
VAL_ 1646 KL_SIH_LEL_Verteilung_VL 0 "gleichmaessige_Verteilung" 1 "Sitz_Prio_Hoch" 2 "Sitz_Prio_Mittel" 3 "Sitz_Prio_Niedrig" 4 "Lehne_Prio_Niedrig" 5 "Lehne_Prio_Mittel" 6 "Lehne_Prio_Hoch" ;
VAL_ 1646 KL_SIH_LEH_Verteilung_VR 0 "gleichmaessige_Verteilung" 1 "Sitz_Prio_Hoch" 2 "Sitz_Prio_Mittel" 3 "Sitz_Prio_Niedrig" 4 "Lehne_Prio_Niedrig" 5 "Lehne_Prio_Mittel" 6 "Lehne_Prio_Hoch" ;
VAL_ 1646 KL_SIH_LEL_Verteilung_VR 0 "gleichmaessige_Verteilung" 1 "Sitz_Prio_Hoch" 2 "Sitz_Prio_Mittel" 3 "Sitz_Prio_Niedrig" 4 "Lehne_Prio_Niedrig" 5 "Lehne_Prio_Mittel" 6 "Lehne_Prio_Hoch" ;
VAL_ 1640 KL_LRH_Taster 0 "nicht_betaetigt" 1 "betaetigt" ;
VAL_ 1640 KL_LRH_Stufe 0 "Stufe_niedrig" 1 "Stufe_mittel" 2 "Stufe_hoch" 3 "AUS" ;
VAL_ 1640 HSH_Taster 0 "nicht_betaetigt" 1 "short_push" 2 "long_push" 3 "tbd" ;
VAL_ 1640 FSH_Taster 0 "nicht_betaetigt" 1 "betaetigt" ;
VAL_ 1640 KL_Zuheizer_Freigabe 0 "keine_Freigabe_Zuheizer" 1 "Zuheizerfreigabe" ;
VAL_ 1640 KL_Beschlagsgefahr 0 "keine_Beschlagsgefahr" 1 "Beschlagsgefahr" ;
VAL_ 1640 KRH_Soll_li 0 "aus" 1 "Stufe_1" 2 "Stufe_2" 3 "Stufe_3" ;
VAL_ 1640 KRH_Soll_re 0 "aus" 1 "Stufe_1" 2 "Stufe_2" 3 "Stufe_3" ;
VAL_ 1640 KL_Geblspng_Soll 0 "0V_Motorspannung" 252 "0V_sofort_Abschalten" 253 "0V_senken_mit_Rampe" 254 "reserviert" 255 "Fehler" ;
VAL_ 1640 KL_Geblspng_Fond_Soll 0 "0V_Motorspannung" 252 "0V_sofort_Abschalten" 253 "0V_senken_mit_Rampe" 254 "reserviert" 255 "Fehler" ;
VAL_ 1640 KL_I_Geblaese 255 "Fehler" ;
VAL_ 1640 KL_Kompressorstrom_soll 1022 "Init" 1023 "Fehler" ;
VAL_ 1640 KL_Umluftklappe_Status 0 "Frischluft" 1 "Teilumluft_10" 2 "Teilumluft_20" 3 "Teilumluft_30" 4 "Teilumluft_40" 5 "Teilumluft_50" 6 "Teilumluft_60" 7 "Teilumluft_70" 8 "Teilumluft_80" 9 "Teilumluft_90" 10 "Umluft" 14 "Init" 15 "Fehler" ;
VAL_ 1640 KL_PTC_Verbauinfo 0 "kein_PTC" 1 "600W_geschaltet" 2 "1000W_geschaltet" 3 "1400W_LIN" ;
VAL_ 2527679635 KL_Voko_Status 0 "aus" 1 "ein" 14 "Init" 15 "Fehler" ;
VAL_ 2527679635 KL_LRH_Soll 0 "nicht_angefordert" 1 "angefordert" ;
VAL_ 2527679635 KL_AL_VR_Anf 0 "Init" 1 "waermer" 2 "kaelter" ;
VAL_ 2527679635 KL_AL_VL_Anf 0 "Init" 1 "waermer" 2 "kaelter" ;
VAL_ 2527679635 KL_AL_HR_Anf 0 "Init" 1 "waermer" 2 "kaelter" ;
VAL_ 2527679635 KL_AL_HL_Anf 0 "Init" 1 "waermer" 2 "kaelter" ;
VAL_ 2527679635 KL_HSH_Soll 0 "nicht_angefordert" 1 "angefordert" ;
VAL_ 2527679635 KL_FSH_Soll 0 "nicht_angefordert" 1 "angefordert" ;
VAL_ 2527679635 KL_ZR_Anforderung 0 "init" 1 "inaktiv" 2 "aktiv" 3 "reserviert" ;
VAL_ 2527679635 KL_VoKo_LED 0 "Aus" 1 "Ein" ;
VAL_ 2527679635 KL_Defrost_LED 0 "Aus" 1 "Ein" ;
VAL_ 2527679635 KL_HSH_LED 0 "Aus" 1 "Ein" ;
VAL_ 2527679635 HSH_Relais_Anf 0 "nicht_angefordert" 1 "angefordert" ;
VAL_ 2527679635 FSH_Status 0 "aus" 1 "ein" 2 "tbd" 3 "Fehler" ;
VAL_ 2527679635 SIH_Stufe_LED_li 0 "Aus" 2 "Stufe_2" 4 "Stufe_4" 6 "Stufe_6" ;
VAL_ 2527679635 SIH_Stufe_LED_re 0 "Aus" 2 "Stufe_2" 4 "Stufe_4" 6 "Stufe_6" ;
VAL_ 2527679635 KL_FSH_LED 0 "Aus" 1 "Ein" ;
VAL_ 2527679635 KL_HUP_aktiv 0 "Aus" 1 "Ein" ;
VAL_ 2527679635 KL_LSH_DBetr_Ein 0 "Dauerbetrieb_nicht_gefordert" 1 "Dauerbetrieb_gefordert" ;
VAL_ 2527679635 KL_LSH_DBetr_Bestaet 0 "kein_Dauerbetrieb" 1 "Dauerbetrieb_bestaetigt" ;
VAL_ 2527679635 KL_Klappe_Status 0 "Init" 1 "Front" 2 "Heck" 3 "Front_u_Heck" 4 "misch_Front_u_Heck" ;
VAL_ 2527679635 KL_LSH_Ansteuerung 0 "Aus" 1 "Ein" 2 "Kombi_Betrieb" 3 "Heizleistung_reduziert" ;
VAL_ 2527679635 KL_Heizstufe_LSH 0 "Init" 1 "Stufe_1" 2 "Stufe_2" 3 "Stufe_3" 4 "Stufe_4" 5 "Stufe_5" 6 "Stufe_6" 7 "Stufe_7" 8 "Stufe_8" 9 "Stufe_9" 10 "Stufe_10" 15 "Fehler" ;
VAL_ 2527679635 KL_LSH_Betriebsdauer 127 "Dauerbetrieb" ;
VAL_ 2527679635 KL_Temp_ZH_Soll 0 "Funk_nicht_verbaut_nicht_aktiv" 255 "Fehler" ;
VAL_ 1712 FS_Taupunkt 0 "nicht verfuegbar" 1023 "Fehler" ;
VAL_ 1712 FS_ResponseError 0 "normal" 1 "Fehler" ;
VAL_ 1712 FS_Temp_Scheibe 0 "nicht verfuegbar" 1023 "Fehler" ;
VAL_ 1712 FS_Temp_Sensor 0 "nicht verfuegbar" 255 "Fehler" ;
VAL_ 1712 FS_Luftfeuchte_rel 0 "nicht verfuegbar" 255 "Fehler" ;
VAL_ 1505 BCM1_Aussen_Temp_ungef 253 "nicht_verbaut" 254 "Initwert" 255 "Fehler" ;
VAL_ 1505 BCM_Heizungsabsperrventil_Status 0 "HAV_offen" 1 "HAV_geschlossen" 2 "Init_oder_nicht_verbaut" 3 "Fehler" ;
VAL_ 1505 BCM_Heizungspumpe_Status 0 "Pumpe_aus" 1 "Pumpe_aktiv_und_Stauts_iO" 2 "Init_oder_nicht_verbaut" 3 "Fehler" ;
VAL_ 1505 BCM_Kompressorkupplung_Status 0 "Kupplung_offen" 1 "Kupplung_geschlossen" 2 "Init_oder_nicht_verbaut" 3 "Fehler" ;
VAL_ 1505 BCM1_PTC_stufig_Status 0 "Aus" 1 "Stufe_1_aktiv" 2 "Stufe_2_aktiv" 3 "Stufe_3_aktiv" 6 "Init_oder_nicht_verbaut" 7 "Fehler" ;
VAL_ 1505 BCM1_FStatus_Aussentemp_ungef 0 "iO" 1 "niO" ;
VAL_ 1505 BCM1_Kompressorstrom_ist 254 "Init, bzw. nicht verfuegbar" 255 "Fehler" ;
VAL_ 1505 BCM1_OBD_FStatus_ATemp 0 "kein Fehler / Init / nicht verbaut" 1 "KS- (Kurzschluss nach minus)" 2 "KS+ (Kurzschluss nach plus)" 3 "OC (Leitungsunterbrechung)" 4 "OOR+ (Signal zu gross)" 5 "OOR- (Signal zu klein)" 6 "RC+ (Signal unplausibel zu gross)" 7 "RC- (Signal unplausibel zu klein)" 8 "KS+/OC (Kurzschluss nach plus/Unterbrechung)" 9 "KS-/OC  (Kurzschluss nach minus/Unterbrechung)" 10 "KS-/KS+  (Kurzschluss nach minus/plus)" 11 "KS-/KS+/OC (Kurzschluss nach minus/plus/Unterbrechung)" 12 "frei" 13 "frei" 14 "frei" 15 "frei" ;
VAL_ 605 KLR_Fehler 0 "kein_Fehler" 1 "Fehler" ;
VAL_ 605 KLR_ResponseError 0 "normal" 1 "Fehler" ;
VAL_ 605 KLR_Fehler_Codierung 0 "Kein_Fehler" 1 "Fehler" ;
VAL_ 605 KLR_Touchintensitaet_1 251 "Kalibrierung" 252 "nicht_verfuegbar" 253 "res" 254 "Init" 255 "Fehler" ;
VAL_ 605 KLR_Touchintensitaet_2 251 "Kalibrierung" 252 "nicht_verfuegbar" 253 "res" 254 "Init" 255 "Fehler" ;
VAL_ 605 KLR_Touchintensitaet_3 251 "Kalibrierung" 252 "nicht_verfuegbar" 253 "res" 254 "Init" 255 "Fehler" ;
VAL_ 605 KLR_Touchauswertung 0 "Keine_Beruehrung" 1 "Leicht_beruehrt_innen" 2 "Leicht_beruehrt_links" 3 "Leicht_beruehrt_rechts" 4 "Leicht_beruehrt_links_rechts" 5 "Leicht_umgriffen_links" 6 "Leicht_umgriffen_rechts" 7 "Leicht_umgriffen_links_rechts" 8 "Stark_umgriffen_links" 9 "Stark_umgriffen_rechts" 10 "Stark_umgriffen_links_rechts" 11 "res" 12 "res" 13 "Kalibrierung" 14 "Init" 15 "Fehler_Touchauswertung" ;
VAL_ 2549088270 BCM1_KompSchutz 0 "inaktiv" 1 "aktiv" ;
VAL_ 2549088270 BCM1_Abschaltstufe 0 "keine_Einschraenkung" 1 "Funktionseinschraenkung" ;
VAL_ 2549088270 BCM1_Transport_Mode 0 "keine_Einschraenkung" 1 "Funktionseinschraenkung" ;
VAL_ 2549088270 BCM1_Nachlauftyp 0 "Komm_bei_KL15_EIN" 1 "Komm_nach_KL15_AUS" 2 "Komm_bei_KL15_AUS" ;
VAL_ 2549088270 KN_BCM1_ECUKnockOutTimer 63 "ECUKnockOut_deaktiviert" ;
VAL_ 2549088270 KN_BCM1_BusKnockOut 0 "Funktion_nicht_ausgeloest" 1 "Veto_aktiv" 2 "Funktion_ausgeloest" 3 "Funktion_deaktiviert" ;
VAL_ 2549088270 KN_BCM1_BusKnockOutTimer 255 "BusKnockOut_deaktiviert" ;
VAL_ 2549088270 NM_BCM1_Wakeup 0 "Peripherie_Wakeup__Ursache_nicht_bekannt" 1 "CAN_Wakeup" 2 "KL15_HW" 3 "KL30" 4 "KL58_xs_xt_xd" 5 "Warnblinktaster_EIN" 6 "LDS_Standlicht" 7 "Klemme_S" 8 "Lock_Unlock_Taster" 9 "Heckdeckel_Grifftaster" 10 "Funkbefehl" 11 "Drehfalle_HL" 12 "Drehfalle_HR" 13 "Motorhaubenkontakt" 14 "Heckdeckel_Vorraste" 15 "Heckdeckel_Hauptraste" 16 "LDS_Abblendlicht" 17 "Drehfalle_FT" 18 "Drehfalle_BT" 19 "Kessy_Schluessel_erkannt" 20 "Heckdeckel_Entriegelungstaster" 21 "Schlossrueckmeldung_HL" 22 "Schlossrueckmeldung_HR" 23 "Lichthupe" 25 "DWA_Heckscheibenbruch" 26 "LIN1" 27 "LIN2" 28 "LIN3" 29 "LIN4" 30 "LIN5" 31 "LIN6" 33 "LIN8" 36 "LDS_Nebellicht_Nebelschlusslicht" 37 "Valet_Taster" 38 "Scheinwerferdiebstahlueberwachung" 39 "Versorgung_Innenlicht_KL30g" 40 "Display_Taster" 41 "RearMode_Taster" 42 "SAD_Taster" 43 "Rollo_Taster" 44 "bCall_Taster" 45 "eCall_Taster" 46 "Sitzpneumatikregler" 47 "Signalhorn" 48 "Zustandswechsel_ZV_BEV_PHEV" 49 "Ladesteckerentriegelung_BEV_PHEV" 50 "LIN10_WakeUp" 51 "Taster_Laderaumschliessung" 52 "STH_Taster" 53 "Defrost_Taster_Betaetigt" 54 "Ladesteckerverriegelung_BEV_PHEV" 55 "TuerInnenGriff_HBFS" 56 "TuerInnenGriff_HFS" 57 "TuerAussenGriff_HBFS" 58 "TuerAussenGriff_HFS" 60 "LIN7_WakeUp" 61 "LIN9_WakeUp" 62 "LIN11_WakeUp" 63 "LIN12_WakeUp" 64 "LIN13_WakeUp" 65 "LIN14_WakeUp" 128 "ZV_Wiederverriegelung" 129 "Coming_Home_Ende" 130 "Leaving_Home_Ende" 131 "Softtouch_Freigabe_entziehen" 132 "Fensterheber_Freigabe_entziehen" 133 "Schiebedach_Freigabe_entziehen" 134 "Verdeck_Freigabe_entziehen" 135 "ELV_Freigabe" 136 "KL58xt_Ende" 137 "IRUE_Ausloesung" 138 "NGS_Ausloesung" 139 "Sounder_Alarm" 140 "Regenschliessen" 141 "Remotestart" 142 "Lichtwarnung_Ende" 143 "DWA_Alarm" 144 "Innenlicht" 145 "Tankklappe_wurde_geschlossen" 146 "Parklicht" 147 "Klimafunktion" 148 "Standlicht" 149 "Tankklappe_wurde_geoeffnet" 150 "SAFE_LED" 151 "ZV_TAG_aus_einfahren" 254 "Watchdog_Test" 255 "Entwicklungsursache" ;
VAL_ 2549088270 KN_BCM1_ECUKnockOut 0 "Funktion_nicht_ausgeloest" 1 "Veto_war_aktiv" 2 "Funktion_ausgeloest" 3 "Funktion_deaktiviert" ;
VAL_ 2549088270 KN_BCM1_DiagPfad 0 "aktiv" 1 "inaktiv" ;
VAL_ 2549088270 NM_BCM1_Lokalaktiv 0 "war_nicht_lokal_aktiv" 1 "war_lokal_aktiv" ;
VAL_ 2549088270 NM_BCM1_Subsystemaktiv 0 "war_nicht_lokal_aktiv" 1 "war_lokal_aktiv" ;
VAL_ 2549088270 BCM1_KD_Fehler 0 "Kein_KD_Fehler" 1 "KD_Fehler" ;
VAL_ 2549088272 Gateway_KompSchutz 0 "inaktiv" 1 "aktiv" ;
VAL_ 2549088272 Gateway_Abschaltstufe 0 "keine_Einschraenkung" 1 "Funktionseinschraenkung" ;
VAL_ 2549088272 Gateway_Transport_Mode 0 "keine_Einschraenkung" 1 "Funktionseinschraenkung" ;
VAL_ 2549088272 Gateway_Nachlauftyp 0 "Komm_bei_KL15_EIN" 1 "Komm_nach_KL15_AUS" 2 "Komm_bei_KL15_AUS" ;
VAL_ 2549088272 NM_Gateway_Wakeup 0 "Peripherie_Wakeup__Ursache_nicht_bekannt" 1 "Bus_Wakeup" 2 "KL15_HW" 3 "ACAN_Wakeup" 4 "FCAN_Wakeup" 5 "KCAN_Wakeup" 6 "ICAN_Wakeup" 7 "DiagCAN_Wakeup" 8 "ECAN_Wakeup" 9 "Energie_LIN_Wakeup" 10 "Bedien_LIN_Wakeup" 11 "HybridCAN_Wakeup" 12 "Flexray_Wakeup" 13 "MFL_WakeUp" 14 "Ethernet" 15 "DCAN_Wakeup" 16 "K2CAN_Wakeup" 17 "CCAN" 18 "AFSCAN_Wakeup" 19 "LIN1" 20 "LIN2" 21 "LIN3" 22 "LIN4" 23 "LIN5" 24 "LIN6" 25 "FASCAN" 26 "FAS2CAN" 27 "MDKCAN" 32 "FlexRay_Branch1_WakeUp" 33 "FlexRay_Branch2_WakeUp" 34 "FlexRay_Branch3_WakeUp" 35 "FlexRay_Branch4_WakeUp" 36 "FlexRay_Branch5_WakeUp" 37 "FlexRay_Branch6_WakeUp" 38 "FlexRay_Branch7_WakeUp" 39 "FlexRay_Branch8_WakeUp" 40 "FlexRay_Branch9_WakeUp" 41 "FlexRay_Branch10_WakeUp" 42 "FlexRay_Branch11_WakeUp" 43 "FlexRay_Branch12_WakeUp" 44 "FlexRay_Branch13_WakeUp" 45 "FlexRay_Branch14_WakeUp" 46 "FlexRay_Branch15_WakeUp" 47 "FlexRay_Branch16_WakeUp" 128 "Energiemanagement" 129 "Funktionswakeup_OBDC" 130 "Hochvoltenergiemanagement" 131 "CWU_empfangen" 132 "Fuer_Bus_relevanten_FC_empfangen" 133 "OnlineDienst_empfangen" 134 "HV_Aktivieren" 135 "HV_Deaktivieren" 136 "VTS_Suche_DriverCard" 137 "VTS_Hupen_Blinken" 138 "Remote_Vehicle_Status" 139 "Plug_and_Charge" 140 "VTS_Wakeup_Infotainment" 141 "EMHLR" 142 "NFcGW_fordert_OTA_FC_an" 143 "Komponentenschutz" 144 "UserStateServer" 145 "Dimmung" 146 "Kessy" 147 "StandardAussenlicht" 148 "ParkKoordinator" 149 "HVLMDynamicChargingPOI" 150 "HVLMChargingManagementServer" 151 "HVLMExtendedChargingMonitoring" 152 "Zentralverriegelung" 153 "FunctionOnDemand" 154 "IAA" 155 "StandKlimatisierung" 156 "RealTimeMonitor" 157 "Klemmensteuerung" 158 "Fremdladung_erkannt" ;
VAL_ 2549088272 KN_GW_DiagPfad 0 "aktiv" 1 "inaktiv" ;
VAL_ 2549088272 GW_KD_Fehler 0 "kein_KD_Fehler" 1 "KD_Fehler" ;
VAL_ 2549088331 TSG_BFS_KompSchutz 0 "inaktiv" 1 "aktiv" ;
VAL_ 2549088331 TSG_BFS_Abschaltstufe 0 "keine_Einschraenkung" 1 "Funktionseinschraenkung" ;
VAL_ 2549088331 TSG_BFS_Transport_Mode 0 "keine_Einschraenkung" 1 "Funktionseinschraenkung" ;
VAL_ 2549088331 TSG_BFS_Nachlauftyp 0 "Komm_bei_KL15_EIN" 1 "Komm_nach_KL15_AUS" 2 "Komm_bei_KL15_AUS" ;
VAL_ 2549088331 KN_TSG_BT_ECUKnockOutTimer 63 "ECUKnockOut_deaktiviert" ;
VAL_ 2549088331 KN_TSG_BT_BusKnockOut 0 "Funktion_nicht_ausgeloest" 1 "Veto_aktiv" 2 "Funktion_ausgeloest" 3 "Funktion_deaktiviert" ;
VAL_ 2549088331 KN_TSG_BFS_BusKnockOutTimer 255 "BusKnockOut_deaktiviert" ;
VAL_ 2549088331 NM_TSG_BFS_Wakeup 0 "Peripherie_Wakeup__Ursache_nicht_bekannt" 1 "Bus_Wakeup" 2 "KL15_HW" 4 "KL30_Reset" 5 "LIN_Wakeup" 6 "Drehfalle" 10 "Memory_Pos_Taste_1" 11 "Memory_Pos_Taste_2" 12 "Memory_Speichern_Taste" 13 "Schliesszylinder_entriegeln" 14 "Schliesszylinder_verriegeln" 15 "Innenverriegelungstaster_verriegeln" 16 "Innenverriegelungstaster_entriegeln" 18 "Tueraussengrifftaster" 19 "Tueraussengriffverriegelungstaster" 20 "Fensterheberbedienfeld" 24 "Schlossrueckmeldeleitung" 25 "Tuerinnengriff" 27 "Memory_Pos_Taste_3" 28 "Watchdog_Reset" 31 "Spiegelauswahlschalter" 32 "Sperrklinke" 33 "KiSi_Rueckmeldeleitung" 34 "ECC_Reset" 43 "Diagnose_Reset" ;
VAL_ 2549088331 KN_TSG_BT_ECUKnockOut 0 "Funktion_nicht_ausgeloest" 1 "Veto_war_aktiv" 2 "Funktion_ausgeloest" 3 "Funktion_deaktiviert" ;
VAL_ 2549088331 KN_TSG_BFS_DiagPfad 0 "aktiv" 1 "inaktiv" ;
VAL_ 2549088331 NM_TSG_BFS_Lokalaktiv 0 "war_nicht_lokal_aktiv" 1 "war_lokal_aktiv" ;
VAL_ 2549088331 NM_TSG_BFS_Subsystemaktiv 0 "Subsystem_war_nicht_lokalaktiv" 1 "war_lokalaktiv" ;
VAL_ 2549088331 TSG_BFS_KD_Fehler 0 "kein_KD_Fehler" 1 "KD_Fehler" ;
VAL_ 2549088330 TSG_FS_KompSchutz 0 "inaktiv" 1 "aktiv" ;
VAL_ 2549088330 TSG_FS_Abschaltstufe 0 "keine_Einschraenkung" 1 "Funktionseinschraenkung" ;
VAL_ 2549088330 TSG_FS_Transport_Mode 0 "keine_Einschraenkung" 1 "Funktionseinschraenkung" ;
VAL_ 2549088330 TSG_FS_Nachlauftyp 0 "Komm_bei_KL15_EIN" 1 "Komm_nach_KL15_AUS" 2 "Komm_bei_KL15_AUS" ;
VAL_ 2549088330 KN_TSG_FT_ECUKnockOutTimer 63 "ECUKnockOut_deaktiviert" ;
VAL_ 2549088330 KN_TSG_FT_BusKnockOut 0 "Funktion_nicht_ausgeloest" 1 "Veto_aktiv" 2 "Funktion_ausgeloest" 3 "Funktion_deaktiviert" ;
VAL_ 2549088330 KN_TSG_FS_BusKnockOutTimer 255 "BusKnockOut_deaktiviert" ;
VAL_ 2549088330 NM_TSG_FS_Wakeup 0 "Peripherie_Wakeup__Ursache_nicht_bekannt" 1 "Bus_Wakeup" 2 "KL15_HW" 4 "KL30_Reset" 5 "LIN_Wakeup" 6 "Drehfalle" 7 "HDF_Taster" 8 "KiSi_Links_Taster" 9 "KiSi_Rechts_Taster" 10 "Memory_Pos_Taste_1" 11 "Memory_Pos_Taste_2" 12 "Memory_Speichern_Taste" 13 "Schliesszylinder_entriegeln" 14 "Schliesszylinder_verriegeln" 15 "Innenverriegelungstaster_verriegeln" 16 "Innenverriegelungstaster_entriegeln" 17 "TDE_Taster" 18 "Türaussengrifftaster" 19 "Tueraussengriffverriegelungstaster" 20 "Fensterheberbedienfeld" 21 "Spiegelverstell_Taster" 22 "DWA_Taster" 24 "Schlossrueckmeldeleitung" 25 "Tuerinnengriff" 26 "SWA_Taster" 27 "Memory_Pos_Taste_3" 28 "Watchdog_Reset" 31 "Spiegelauswahlschalter" 32 "Sperrklinke" 33 "KiSi_Rueckmeldeleitung" 34 "ECC_Reset" 43 "Diagnose_Reset" ;
VAL_ 2549088330 KN_TSG_FT_ECUKnockOut 0 "Funktion_nicht_ausgeloest" 1 "Veto_war_aktiv" 2 "Funktion_ausgeloest" 3 "Funktion_deaktiviert" ;
VAL_ 2549088330 KN_TSG_FS_DiagPfad 0 "aktiv" 1 "inaktiv" ;
VAL_ 2549088330 NM_TSG_FS_Lokalaktiv 0 "war_nicht_lokal_aktiv" 1 "war_lokal_aktiv" ;
VAL_ 2549088330 NM_TSG_FS_Subsystemaktiv 0 "Subsystem_war_nicht_lokalaktiv" 1 "war_lokalaktiv" ;
VAL_ 2549088330 TSG_FS_KD_Fehler 0 "kein_KD_Fehler" 1 "KD_Fehler" ;
